VERSION ""

NS_ :

BS_:

BU_: WCM4 WCM3 WCM2 WCM VPM VLM VKM VICM VECM VDM VCU_RTOS_ETH VCU_ENTRY_ETH VCU_AGVM_ETH VCU UVM UPM TIM TEST_TOOL_1 TCP_ETH TCP TCM TCCM SRR_SRR_ETH SRR_SRR SRR_SLR_ETH SRR_SLR SRR_RR SRR_RF_ETH SRR_RF SRR_LR_CR SRR_LF_ETH SRR_LF SIB SDM SCL SBZA_R SBZA_L SBM SAM_RR SAM_RF SAM_LR SAM_LF SAM_BH SADS RadioLow_ETH RadioLow RSI_RTOS_ETH RSI RDCM PTM PLCM PFCM PDR_ETH PDR PCM PA ODS2 ODS NVM MTCM_R MTCM_L MSM_RR MSM_P MSM_LR MSM_D MSB2 MSB1 MRCM_R MRCM_L MFC LRR_RR_ETH LRR_LR_ETH LRR_CF_ETH LRR LRL_CF_ETH LIB_48V LIB1 IPC_INT IPC_GP IPC ICS_Info ICCM HVAC_FP_R HVAC_FP_F HUD_CAN HDLM FPI_RTOS_ETH FPI FOPM FCM_LC FCM EPSb EPS_1 EPSRAb EPSRAa EPS EOCM_HC_Superset EOCM_HCP2 EOCM ELM ECP_X1 ECP_S2 ECP_S ECP_MC ECP_H3 ECP_H2 ECP_H1 ECP_E ECM EBCM DMS DEFC DCM CSM_ETH CSM_AV CSM CGM_OTA_ETH CGM BSM_MH BSM_HEV BSM BCM ARS ARB APA AOS AMP ALC AHS AHL_AFL ADIMb ADIMa ACP2_MCU

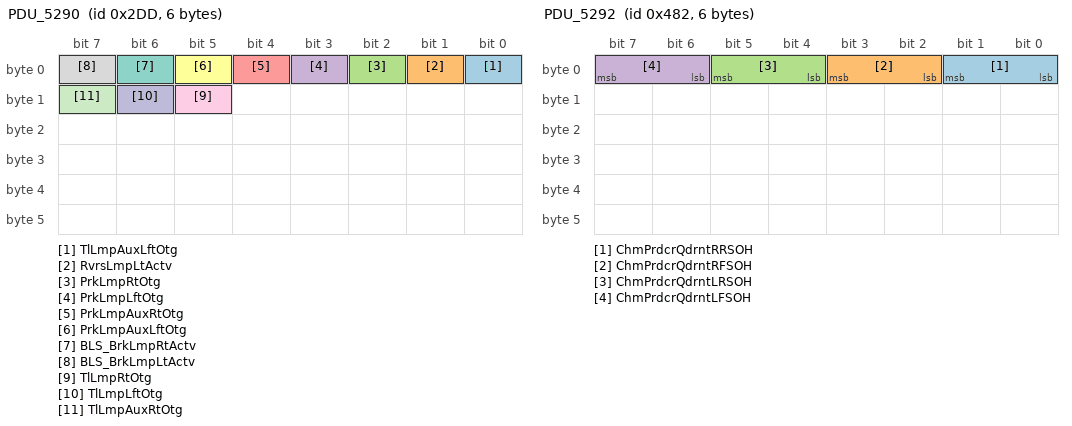
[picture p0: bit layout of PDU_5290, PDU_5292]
BO_ 733 PDU_5290: 6 CGM
 SG_ TlLmpAuxLftOtg : 0|1@0+ (1,0) [0|1] "" VKM
 SG_ RvrsLmpLtActv : 1|1@0+ (1,0) [0|1] "" VKM
 SG_ PrkLmpRtOtg : 2|1@0+ (1,0) [0|1] "" VKM
 SG_ PrkLmpLftOtg : 3|1@0+ (1,0) [0|1] "" VKM
 SG_ PrkLmpAuxRtOtg : 4|1@0+ (1,0) [0|1] "" VKM
 SG_ PrkLmpAuxLftOtg : 5|1@0+ (1,0) [0|1] "" VKM
 SG_ BLS_BrkLmpRtActv : 6|1@0+ (1,0) [0|1] "" VKM
 SG_ BLS_BrkLmpLtActv : 7|1@0+ (1,0) [0|1] "" VKM
 SG_ TlLmpRtOtg : 13|1@0+ (1,0) [0|1] "" VKM
 SG_ TlLmpLftOtg : 14|1@0+ (1,0) [0|1] "" VKM
 SG_ TlLmpAuxRtOtg : 15|1@0+ (1,0) [0|1] "" VKM

BO_ 734 PDU_5291: 6 CGM
 SG_ BGI5_TrnLmpRtFncActv : 6|1@0+ (1,0) [0|1] "" VKM
 SG_ BGI5_TrnLmpLtFncActv : 7|1@0+ (1,0) [0|1] "" VKM

BO_ 1154 PDU_5292: 6 AMP
 SG_ ChmPrdcrQdrntRRSOH : 1|2@0+ (1,0) [0|2] "" VCU
 SG_ ChmPrdcrQdrntRFSOH : 3|2@0+ (1,0) [0|2] "" VCU
 SG_ ChmPrdcrQdrntLRSOH : 5|2@0+ (1,0) [0|2] "" VCU
 SG_ ChmPrdcrQdrntLFSOH : 7|2@0+ (1,0) [0|2] "" VCU

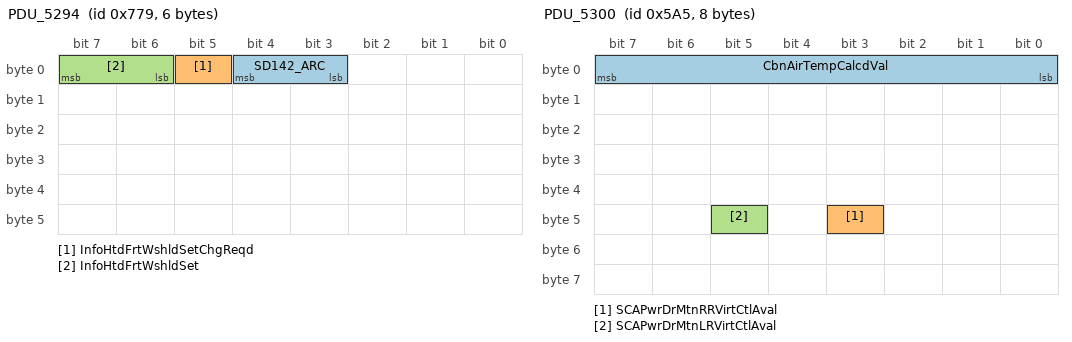
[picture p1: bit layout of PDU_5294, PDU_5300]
BO_ 1913 PDU_5294: 6 RadioLow
 SG_ SD142_ARC : 4|2@0+ (1,0) [0|3] "" CGM
 SG_ InfoHtdFrtWshldSetChgReqd : 5|1@0+ (1,0) [0|1] "" CGM
 SG_ InfoHtdFrtWshldSet : 7|2@0+ (1,0) [0|3] "" CGM

BO_ 229 PDU_5296: 6 CSM
 SG_ DrvModeConfDrvrResp : 7|4@0+ (1,0) [0|15] "" CGM

BO_ 537 PDU_5297: 6 IPC
 SG_ MaxPwrModeConfDrvrResp : 7|3@0+ (1,0) [0|7] "" CGM

BO_ 1304 PDU_5298: 8 VCU
 SG_ HVACICRBlwLvlChgRrRt : 2|5@0+ (1,-12) [-12|19] "" Vector__XXX
 SG_ HVACICRBlwLvlChgFrtRt : 7|5@0+ (1,-12) [-12|19] "" Vector__XXX
 SG_ HVACICRBlwLvlRrRt : 9|4@0+ (1,0) [0|15] "" Vector__XXX
 SG_ HVACICRBlwLvlFrtRt : 13|4@0+ (1,0) [0|15] "" Vector__XXX
 SG_ HVACICRMcrClmStSyncRrRt : 18|1@0+ (1,0) [0|1] "" Vector__XXX
 SG_ HVACICRMcrClmStSyncRrLt : 19|1@0+ (1,0) [0|1] "" Vector__XXX
 SG_ HVACICRMcrClmStSyncFrtRt : 20|1@0+ (1,0) [0|1] "" Vector__XXX
 SG_ HVACICRMcrClmStSyncFrtLt : 21|1@0+ (1,0) [0|1] "" Vector__XXX
 SG_ HVACICRNckScrfLvlChgFrtLt : 25|3@0+ (1,-3) [-3|4] "" Vector__XXX
 SG_ HVACICRNckScrfLvlChgRrRt : 32|3@0+ (1,-3) [-3|4] "" Vector__XXX
 SG_ HVACICRNckScrfLvlChgRrLt : 35|3@0+ (1,-3) [-3|4] "" Vector__XXX
 SG_ HVACICRNckScrfLvlChgFrtRt : 38|3@0+ (1,-3) [-3|4] "" Vector__XXX
 SG_ HVACICRNckScrfLvlRrLt : 41|2@0+ (1,0) [0|3] "" Vector__XXX
 SG_ HVACICRNckScrfLvlFrtRt : 43|2@0+ (1,0) [0|3] "" Vector__XXX
 SG_ HVACICRNckScrfLvlFrtLt : 45|2@0+ (1,0) [0|3] "" Vector__XXX
 SG_ HVACICRFrtRtAutoSetChg : 49|1@0+ (1,0) [0|1] "" Vector__XXX
 SG_ HVACICRBlwLvlRrRtActv : 50|1@0+ (1,0) [0|1] "" Vector__XXX
 SG_ HVACICRBlwLvlFrtRtActv : 51|1@0+ (1,0) [0|1] "" Vector__XXX
 SG_ SD163_ARC : 53|2@0+ (1,0) [0|3] "" Vector__XXX
 SG_ HVACICRNckScrfLvlRrRt : 55|2@0+ (1,0) [0|3] "" Vector__XXX
 SG_ HVACICRRrRtAutoSetChg : 56|1@0+ (1,0) [0|1] "" Vector__XXX
 SG_ HVACICRNckScrfLvlRrRtActv : 57|1@0+ (1,0) [0|1] "" Vector__XXX
 SG_ HVACICRNckScrfLvlRrLtActv : 58|1@0+ (1,0) [0|1] "" Vector__XXX
 SG_ HVACICRNckScrfLvlFrtRtActv : 59|1@0+ (1,0) [0|1] "" Vector__XXX
 SG_ HVACICRNckScrfLvlFrtLtActv : 60|1@0+ (1,0) [0|1] "" Vector__XXX

BO_ 1445 PDU_5300: 8 CGM
 SG_ CbnAirTempCalcdVal : 7|8@0+ (0.5,-40) [-40|87.5] "deg C" TCP
 SG_ SCAPwrDrMtnRRVirtCtlAval : 43|1@0+ (1,0) [0|1] "" VCU
 SG_ SCAPwrDrMtnLRVirtCtlAval : 45|1@0+ (1,0) [0|1] "" VCU

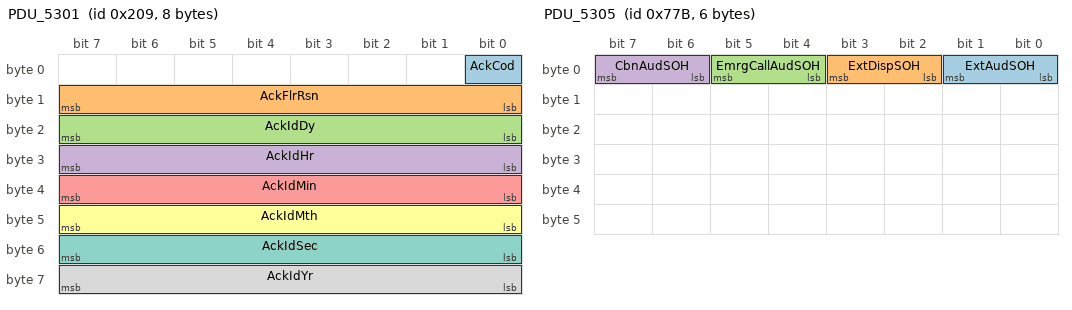
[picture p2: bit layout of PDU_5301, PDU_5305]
BO_ 521 PDU_5301: 8 TCP
 SG_ AckCod : 0|1@0+ (1,0) [0|1] "" Vector__XXX
 SG_ AckFlrRsn : 15|8@0+ (1,0) [0|255] "" Vector__XXX
 SG_ AckIdDy : 23|8@0+ (1,0) [0|255] "" Vector__XXX
 SG_ AckIdHr : 31|8@0+ (1,0) [0|255] "" Vector__XXX
 SG_ AckIdMin : 39|8@0+ (1,0) [0|255] "" Vector__XXX
 SG_ AckIdMth : 47|8@0+ (1,0) [0|255] "" Vector__XXX
 SG_ AckIdSec : 55|8@0+ (1,0) [0|255] "" Vector__XXX
 SG_ AckIdYr : 63|8@0+ (1,0) [0|255] "" Vector__XXX

BO_ 1910 PDU_5303: 8 CGM
 SG_ IntrAmbtColrCtlCstAvlFlg34 : 8|1@0+ (1,0) [0|1] "" VCU
 SG_ IntrAmbtColrCtlCstAvlFlg33 : 9|1@0+ (1,0) [0|1] "" VCU
 SG_ IntrAmbtColrCtlCstAvlFlg32 : 10|1@0+ (1,0) [0|1] "" VCU
 SG_ IntrAmbtColrCtlCstAvlFlg42 : 16|1@0+ (1,0) [0|1] "" VCU
 SG_ IntrAmbtColrCtlCstAvlFlg41 : 17|1@0+ (1,0) [0|1] "" VCU
 SG_ IntrAmbtColrCtlCstAvlFlg40 : 18|1@0+ (1,0) [0|1] "" VCU
 SG_ IntrAmbtColrCtlCstAvlFlg39 : 19|1@0+ (1,0) [0|1] "" VCU
 SG_ IntrAmbtColrCtlCstAvlFlg38 : 20|1@0+ (1,0) [0|1] "" VCU
 SG_ IntrAmbtColrCtlCstAvlFlg37 : 21|1@0+ (1,0) [0|1] "" VCU
 SG_ IntrAmbtColrCtlCstAvlFlg36 : 22|1@0+ (1,0) [0|1] "" VCU
 SG_ IntrAmbtColrCtlCstAvlFlg35 : 23|1@0+ (1,0) [0|1] "" VCU
 SG_ IntrAmbtColrCtlCstAvlFlg50 : 24|1@0+ (1,0) [0|1] "" VCU
 SG_ IntrAmbtColrCtlCstAvlFlg49 : 25|1@0+ (1,0) [0|1] "" VCU
 SG_ IntrAmbtColrCtlCstAvlFlg48 : 26|1@0+ (1,0) [0|1] "" VCU
 SG_ IntrAmbtColrCtlCstAvlFlg47 : 27|1@0+ (1,0) [0|1] "" VCU
 SG_ IntrAmbtColrCtlCstAvlFlg46 : 28|1@0+ (1,0) [0|1] "" VCU
 SG_ IntrAmbtColrCtlCstAvlFlg45 : 29|1@0+ (1,0) [0|1] "" VCU
 SG_ IntrAmbtColrCtlCstAvlFlg44 : 30|1@0+ (1,0) [0|1] "" VCU
 SG_ IntrAmbtColrCtlCstAvlFlg43 : 31|1@0+ (1,0) [0|1] "" VCU
 SG_ IntrAmbtColrCtlCstAvlFlg58 : 32|1@0+ (1,0) [0|1] "" VCU
 SG_ IntrAmbtColrCtlCstAvlFlg57 : 33|1@0+ (1,0) [0|1] "" VCU
 SG_ IntrAmbtColrCtlCstAvlFlg56 : 34|1@0+ (1,0) [0|1] "" VCU
 SG_ IntrAmbtColrCtlCstAvlFlg55 : 35|1@0+ (1,0) [0|1] "" VCU
 SG_ IntrAmbtColrCtlCstAvlFlg54 : 36|1@0+ (1,0) [0|1] "" VCU
 SG_ IntrAmbtColrCtlCstAvlFlg53 : 37|1@0+ (1,0) [0|1] "" VCU
 SG_ IntrAmbtColrCtlCstAvlFlg52 : 38|1@0+ (1,0) [0|1] "" VCU
 SG_ IntrAmbtColrCtlCstAvlFlg51 : 39|1@0+ (1,0) [0|1] "" VCU
 SG_ IntrAmbtColrCtlCstAvlFlg66 : 40|1@0+ (1,0) [0|1] "" VCU
 SG_ IntrAmbtColrCtlCstAvlFlg65 : 41|1@0+ (1,0) [0|1] "" VCU
 SG_ IntrAmbtColrCtlCstAvlFlg64 : 42|1@0+ (1,0) [0|1] "" VCU
 SG_ IntrAmbtColrCtlCstAvlFlg63 : 43|1@0+ (1,0) [0|1] "" VCU
 SG_ IntrAmbtColrCtlCstAvlFlg62 : 44|1@0+ (1,0) [0|1] "" VCU
 SG_ IntrAmbtColrCtlCstAvlFlg61 : 45|1@0+ (1,0) [0|1] "" VCU
 SG_ IntrAmbtColrCtlCstAvlFlg60 : 46|1@0+ (1,0) [0|1] "" VCU
 SG_ IntrAmbtColrCtlCstAvlFlg59 : 47|1@0+ (1,0) [0|1] "" VCU
 SG_ IntrAmbtColrCtlCstAvlFlg74 : 48|1@0+ (1,0) [0|1] "" VCU
 SG_ IntrAmbtColrCtlCstAvlFlg73 : 49|1@0+ (1,0) [0|1] "" VCU
 SG_ IntrAmbtColrCtlCstAvlFlg72 : 50|1@0+ (1,0) [0|1] "" VCU
 SG_ IntrAmbtColrCtlCstAvlFlg71 : 51|1@0+ (1,0) [0|1] "" VCU
 SG_ IntrAmbtColrCtlCstAvlFlg70 : 52|1@0+ (1,0) [0|1] "" VCU
 SG_ IntrAmbtColrCtlCstAvlFlg69 : 53|1@0+ (1,0) [0|1] "" VCU
 SG_ IntrAmbtColrCtlCstAvlFlg68 : 54|1@0+ (1,0) [0|1] "" VCU
 SG_ IntrAmbtColrCtlCstAvlFlg67 : 55|1@0+ (1,0) [0|1] "" VCU
 SG_ IntrAmbtColrCtlCstAvlFlg82 : 56|1@0+ (1,0) [0|1] "" VCU
 SG_ IntrAmbtColrCtlCstAvlFlg81 : 57|1@0+ (1,0) [0|1] "" VCU
 SG_ IntrAmbtColrCtlCstAvlFlg80 : 58|1@0+ (1,0) [0|1] "" VCU
 SG_ IntrAmbtColrCtlCstAvlFlg79 : 59|1@0+ (1,0) [0|1] "" VCU
 SG_ IntrAmbtColrCtlCstAvlFlg78 : 60|1@0+ (1,0) [0|1] "" VCU
 SG_ IntrAmbtColrCtlCstAvlFlg77 : 61|1@0+ (1,0) [0|1] "" VCU
 SG_ IntrAmbtColrCtlCstAvlFlg76 : 62|1@0+ (1,0) [0|1] "" VCU
 SG_ IntrAmbtColrCtlCstAvlFlg75 : 63|1@0+ (1,0) [0|1] "" VCU

BO_ 1912 PDU_5304: 8 CGM
 SG_ IntrAmbtColrCtlCstAvlFlg107 : 0|1@0+ (1,0) [0|1] "" VCU
 SG_ IntrAmbtColrCtlCstAvlFlg106 : 1|1@0+ (1,0) [0|1] "" VCU
 SG_ IntrAmbtColrCtlCstAvlFlg105 : 2|1@0+ (1,0) [0|1] "" VCU
 SG_ IntrAmbtColrCtlCstAvlFlg104 : 3|1@0+ (1,0) [0|1] "" VCU
 SG_ IntrAmbtColrCtlCstAvlFlg103 : 4|1@0+ (1,0) [0|1] "" VCU
 SG_ IntrAmbtColrCtlCstAvlFlg102 : 5|1@0+ (1,0) [0|1] "" VCU
 SG_ IntrAmbtColrCtlCstAvlFlg101 : 6|1@0+ (1,0) [0|1] "" VCU
 SG_ IntrAmbtColrCtlCstAvlFlg100 : 7|1@0+ (1,0) [0|1] "" VCU
 SG_ IntrAmbtColrCtlCstAvlFlg115 : 8|1@0+ (1,0) [0|1] "" VCU
 SG_ IntrAmbtColrCtlCstAvlFlg114 : 9|1@0+ (1,0) [0|1] "" VCU
 SG_ IntrAmbtColrCtlCstAvlFlg113 : 10|1@0+ (1,0) [0|1] "" VCU
 SG_ IntrAmbtColrCtlCstAvlFlg112 : 11|1@0+ (1,0) [0|1] "" VCU
 SG_ IntrAmbtColrCtlCstAvlFlg111 : 12|1@0+ (1,0) [0|1] "" VCU
 SG_ IntrAmbtColrCtlCstAvlFlg110 : 13|1@0+ (1,0) [0|1] "" VCU
 SG_ IntrAmbtColrCtlCstAvlFlg109 : 14|1@0+ (1,0) [0|1] "" VCU
 SG_ IntrAmbtColrCtlCstAvlFlg108 : 15|1@0+ (1,0) [0|1] "" VCU
 SG_ IntrAmbtColrCtlCstAvlFlg123 : 16|1@0+ (1,0) [0|1] "" VCU
 SG_ IntrAmbtColrCtlCstAvlFlg122 : 17|1@0+ (1,0) [0|1] "" VCU
 SG_ IntrAmbtColrCtlCstAvlFlg121 : 18|1@0+ (1,0) [0|1] "" VCU
 SG_ IntrAmbtColrCtlCstAvlFlg120 : 19|1@0+ (1,0) [0|1] "" VCU
 SG_ IntrAmbtColrCtlCstAvlFlg119 : 20|1@0+ (1,0) [0|1] "" VCU
 SG_ IntrAmbtColrCtlCstAvlFlg118 : 21|1@0+ (1,0) [0|1] "" VCU
 SG_ IntrAmbtColrCtlCstAvlFlg117 : 22|1@0+ (1,0) [0|1] "" VCU
 SG_ IntrAmbtColrCtlCstAvlFlg116 : 23|1@0+ (1,0) [0|1] "" VCU
 SG_ IntrAmbtColrCtlCstAvlFlg86 : 24|1@0+ (1,0) [0|1] "" VCU
 SG_ IntrAmbtColrCtlCstAvlFlg85 : 25|1@0+ (1,0) [0|1] "" VCU
 SG_ IntrAmbtColrCtlCstAvlFlg84 : 26|1@0+ (1,0) [0|1] "" VCU
 SG_ IntrAmbtColrCtlCstAvlFlg83 : 27|1@0+ (1,0) [0|1] "" VCU
 SG_ IntrAmbtColrCtlCstAvlFlg127 : 28|1@0+ (1,0) [0|1] "" VCU
 SG_ IntrAmbtColrCtlCstAvlFlg126 : 29|1@0+ (1,0) [0|1] "" VCU
 SG_ IntrAmbtColrCtlCstAvlFlg125 : 30|1@0+ (1,0) [0|1] "" VCU
 SG_ IntrAmbtColrCtlCstAvlFlg124 : 31|1@0+ (1,0) [0|1] "" VCU
 SG_ IntrAmbtColrCtlCstAvlFlg94 : 32|1@0+ (1,0) [0|1] "" VCU
 SG_ IntrAmbtColrCtlCstAvlFlg93 : 33|1@0+ (1,0) [0|1] "" VCU
 SG_ IntrAmbtColrCtlCstAvlFlg92 : 34|1@0+ (1,0) [0|1] "" VCU
 SG_ IntrAmbtColrCtlCstAvlFlg91 : 35|1@0+ (1,0) [0|1] "" VCU
 SG_ IntrAmbtColrCtlCstAvlFlg90 : 36|1@0+ (1,0) [0|1] "" VCU
 SG_ IntrAmbtColrCtlCstAvlFlg89 : 37|1@0+ (1,0) [0|1] "" VCU
 SG_ IntrAmbtColrCtlCstAvlFlg88 : 38|1@0+ (1,0) [0|1] "" VCU
 SG_ IntrAmbtColrCtlCstAvlFlg87 : 39|1@0+ (1,0) [0|1] "" VCU
 SG_ ElvtdIdlCstSetAvlFlg2 : 40|1@0+ (1,0) [0|1] "" RadioLow,CSM,CSM_AV,VCU
 SG_ ElvtdIdlCstSetAvlFlg1 : 41|1@0+ (1,0) [0|1] "" RadioLow,CSM,CSM_AV,VCU
 SG_ ElvtdIdlCstSetAval : 42|1@0+ (1,0) [0|1] "" RadioLow,CSM,CSM_AV,VCU
 SG_ IntrAmbtColrCtlCstAvlFlg99 : 43|1@0+ (1,0) [0|1] "" VCU
 SG_ IntrAmbtColrCtlCstAvlFlg98 : 44|1@0+ (1,0) [0|1] "" VCU
 SG_ IntrAmbtColrCtlCstAvlFlg97 : 45|1@0+ (1,0) [0|1] "" VCU
 SG_ IntrAmbtColrCtlCstAvlFlg96 : 46|1@0+ (1,0) [0|1] "" VCU
 SG_ IntrAmbtColrCtlCstAvlFlg95 : 47|1@0+ (1,0) [0|1] "" VCU
 SG_ DMSDrwDrvrCstAvlFlg3 : 48|1@0+ (1,0) [0|1] "" CSM,CSM_AV,VCU
 SG_ DMSDrwDrvrCstAvlFlg2 : 49|1@0+ (1,0) [0|1] "" CSM,CSM_AV,VCU
 SG_ DMSDrwDrvrCstAvlFlg1 : 50|1@0+ (1,0) [0|1] "" CSM,CSM_AV,VCU
 SG_ ElvtdIdlCstSetAvlFlg7 : 51|1@0+ (1,0) [0|1] "" RadioLow,CSM,CSM_AV,VCU
 SG_ ElvtdIdlCstSetAvlFlg6 : 52|1@0+ (1,0) [0|1] "" RadioLow,CSM,CSM_AV,VCU
 SG_ ElvtdIdlCstSetAvlFlg5 : 53|1@0+ (1,0) [0|1] "" RadioLow,CSM,CSM_AV,VCU
 SG_ ElvtdIdlCstSetAvlFlg4 : 54|1@0+ (1,0) [0|1] "" RadioLow,CSM,CSM_AV,VCU
 SG_ ElvtdIdlCstSetAvlFlg3 : 55|1@0+ (1,0) [0|1] "" RadioLow,CSM,CSM_AV,VCU
 SG_ VehSpdAcurLvl : 58|2@0+ (1,0) [0|2] "" FPI,RSI,IPC,IPC_INT,VCU
 SG_ DMSDrwDrvrCstSetAval : 59|1@0+ (1,0) [0|1] "" CSM,CSM_AV,VCU
 SG_ DMSDrwDrvrCstAvlFlg7 : 60|1@0+ (1,0) [0|1] "" CSM,CSM_AV,VCU
 SG_ DMSDrwDrvrCstAvlFlg6 : 61|1@0+ (1,0) [0|1] "" CSM,CSM_AV,VCU
 SG_ DMSDrwDrvrCstAvlFlg5 : 62|1@0+ (1,0) [0|1] "" CSM,CSM_AV,VCU
 SG_ DMSDrwDrvrCstAvlFlg4 : 63|1@0+ (1,0) [0|1] "" CSM,CSM_AV,VCU

BO_ 1915 PDU_5305: 6 CSM_AV
 SG_ ExtAudSOH : 1|2@0+ (1,0) [0|3] "" CGM
 SG_ ExtDispSOH : 3|2@0+ (1,0) [0|3] "" CGM
 SG_ EmrgCallAudSOH : 5|2@0+ (1,0) [0|3] "" CGM
 SG_ CbnAudSOH : 7|2@0+ (1,0) [0|3] "" CGM

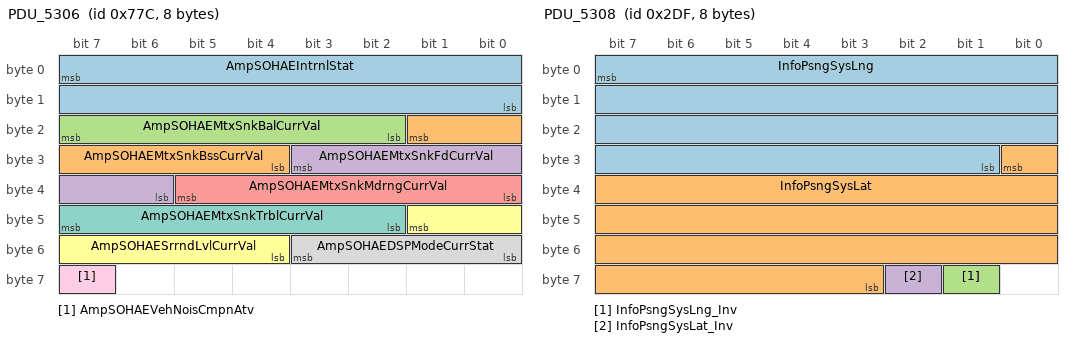
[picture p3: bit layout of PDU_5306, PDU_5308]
BO_ 1916 PDU_5306: 8 AMP
 SG_ AmpSOHAEIntrnlStat : 7|16@0+ (1,0) [0|65535] "" VCU
 SG_ AmpSOHAEMtxSnkBssCurrVal : 17|6@0- (1,0) [-32|31] "detent" VCU
 SG_ AmpSOHAEMtxSnkBalCurrVal : 23|6@0- (1,0) [-32|31] "detent" VCU
 SG_ AmpSOHAEMtxSnkFdCurrVal : 27|6@0- (1,0) [-32|31] "detent" VCU
 SG_ AmpSOHAEMtxSnkMdrngCurrVal : 37|6@0- (1,0) [-32|31] "detent" VCU
 SG_ AmpSOHAESrrndLvlCurrVal : 41|6@0- (1,0) [-32|31] "detent" VCU
 SG_ AmpSOHAEMtxSnkTrblCurrVal : 47|6@0- (1,0) [-32|31] "detent" VCU
 SG_ AmpSOHAEDSPModeCurrStat : 51|4@0+ (1,0) [0|8] "" VCU
 SG_ AmpSOHAEVehNoisCmpnAtv : 63|1@0+ (1,0) [0|1] "" VCU

BO_ 735 PDU_5308: 8 VCU
 SG_ InfoPsngSysLng : 7|31@0- (1,0) [-1.07374e+009|1.07374e+009] "" CGM
 SG_ InfoPsngSysLat : 24|30@0- (1,0) [-5.36871e+008|5.36871e+008] "" CGM
 SG_ InfoPsngSysLng_Inv : 57|1@0+ (1,0) [0|1] "" CGM
 SG_ InfoPsngSysLat_Inv : 58|1@0+ (1,0) [0|1] "" CGM

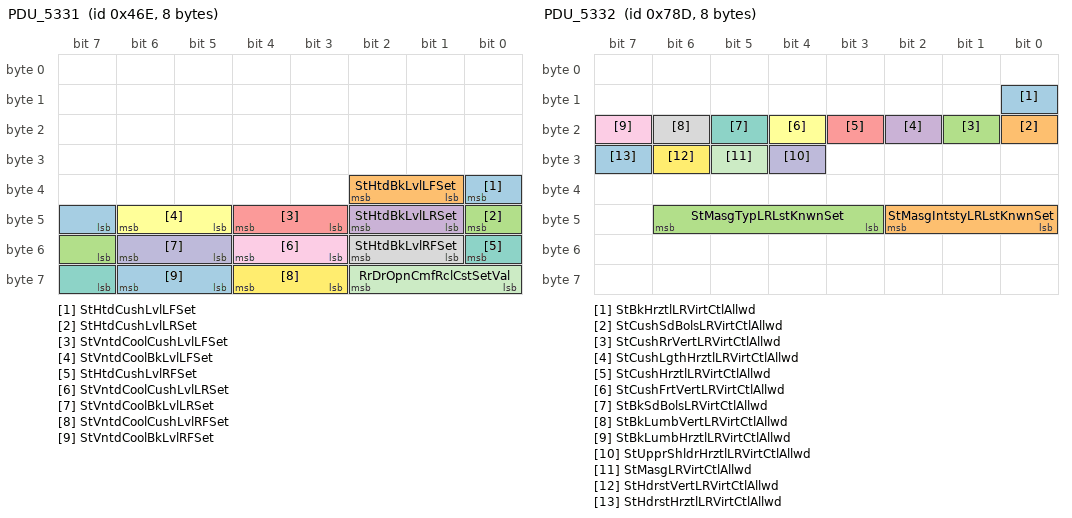
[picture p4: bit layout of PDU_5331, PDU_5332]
BO_ 1134 PDU_5331: 8 CGM
 SG_ StHtdCushLvlLFSet : 32|2@0+ (1,0) [0|3] "" VCU
 SG_ StHtdBkLvlLFSet : 34|2@0+ (1,0) [0|3] "" VCU
 SG_ StHtdCushLvlLRSet : 40|2@0+ (1,0) [0|3] "" VCU
 SG_ StHtdBkLvlLRSet : 42|2@0+ (1,0) [0|3] "" VCU
 SG_ StVntdCoolCushLvlLFSet : 44|2@0+ (1,0) [0|3] "" VCU
 SG_ StVntdCoolBkLvlLFSet : 46|2@0+ (1,0) [0|3] "" VCU
 SG_ StHtdCushLvlRFSet : 48|2@0+ (1,0) [0|3] "" VCU
 SG_ StHtdBkLvlRFSet : 50|2@0+ (1,0) [0|3] "" VCU
 SG_ StVntdCoolCushLvlLRSet : 52|2@0+ (1,0) [0|3] "" VCU
 SG_ StVntdCoolBkLvlLRSet : 54|2@0+ (1,0) [0|3] "" VCU
 SG_ RrDrOpnCmfRclCstSetVal : 58|3@0+ (1,0) [0|2] "" VCU
 SG_ StVntdCoolCushLvlRFSet : 60|2@0+ (1,0) [0|3] "" VCU
 SG_ StVntdCoolBkLvlRFSet : 62|2@0+ (1,0) [0|3] "" VCU

BO_ 1933 PDU_5332: 8 CGM
 SG_ StBkHrztlLRVirtCtlAllwd : 8|1@0+ (1,0) [0|1] "" VCU
 SG_ StCushSdBolsLRVirtCtlAllwd : 16|1@0+ (1,0) [0|1] "" VCU
 SG_ StCushRrVertLRVirtCtlAllwd : 17|1@0+ (1,0) [0|1] "" VCU
 SG_ StCushLgthHrztlLRVirtCtlAllwd : 18|1@0+ (1,0) [0|1] "" VCU
 SG_ StCushHrztlLRVirtCtlAllwd : 19|1@0+ (1,0) [0|1] "" VCU
 SG_ StCushFrtVertLRVirtCtlAllwd : 20|1@0+ (1,0) [0|1] "" VCU
 SG_ StBkSdBolsLRVirtCtlAllwd : 21|1@0+ (1,0) [0|1] "" VCU
 SG_ StBkLumbVertLRVirtCtlAllwd : 22|1@0+ (1,0) [0|1] "" VCU
 SG_ StBkLumbHrztlLRVirtCtlAllwd : 23|1@0+ (1,0) [0|1] "" VCU
 SG_ StUpprShldrHrztlLRVirtCtlAllwd : 28|1@0+ (1,0) [0|1] "" VCU
 SG_ StMasgLRVirtCtlAllwd : 29|1@0+ (1,0) [0|1] "" VCU
 SG_ StHdrstVertLRVirtCtlAllwd : 30|1@0+ (1,0) [0|1] "" VCU
 SG_ StHdrstHrztlLRVirtCtlAllwd : 31|1@0+ (1,0) [0|1] "" VCU
 SG_ StMasgIntstyLRLstKnwnSet : 42|3@0+ (1,0) [0|7] "" VCU
 SG_ StMasgTypLRLstKnwnSet : 46|4@0+ (1,0) [0|15] "" VCU

BO_ 1131 PDU_5335: 8 VCU
 SG_ SuprRmtPrkFcsStsVCU : 34|1@0+ (1,0) [0|1] "" CGM

BO_ 1133 PDU_5338: 8 VCU
 SG_ HVACICROtltFrtRtInbdVrtPs : 0|7@0+ (1,0) [0|127] "%" Vector__XXX
 SG_ HVACICROtltFrtRtInbdHrztlPs : 7|7@0+ (1,0) [0|127] "%" Vector__XXX
 SG_ HVACICROtltFrtRtOtbdHrztlPs : 9|7@0+ (1,0) [0|127] "%" Vector__XXX
 SG_ HVACICROtltFrtRtOtbdVrtPs : 18|7@0+ (1,0) [0|127] "%" Vector__XXX
 SG_ HVACICROtltFrtRtOtbdArflQnty : 24|3@0+ (1,0) [0|4] "" Vector__XXX
 SG_ HVACICROtltFrtRtInbdArflQnty : 27|3@0+ (1,0) [0|4] "" Vector__XXX
 SG_ SD213_ARC : 33|2@0+ (1,0) [0|3] "" Vector__XXX
 SG_ HVACICROtltFrtRtStat : 35|2@0+ (1,0) [0|3] "" Vector__XXX
 SG_ HVACICROscMdFrtRtSet : 37|2@0+ (1,0) [0|3] "" Vector__XXX
 SG_ HVACICROtltRrLtInbdHrztlPs : 45|7@0+ (1,0) [0|127] "%" Vector__XXX
 SG_ HVACICRHVACPwrFrtRtChg : 46|1@0+ (1,0) [0|1] "" Vector__XXX
 SG_ HVACICRCkMdOn : 47|1@0+ (1,0) [0|1] "" Vector__XXX
 SG_ HVACICROtltRrLtInbdVrtPs : 54|7@0+ (1,0) [0|127] "%" Vector__XXX
 SG_ HVACICRHVACPwrRrLtChg : 57|1@0+ (1,0) [0|1] "" Vector__XXX
 SG_ SD214_ARC : 59|2@0+ (1,0) [0|3] "" Vector__XXX
 SG_ HVACICROtltRrLtStat : 61|2@0+ (1,0) [0|3] "" Vector__XXX
 SG_ HVACICROscMdRrLtSet : 63|2@0+ (1,0) [0|3] "" Vector__XXX

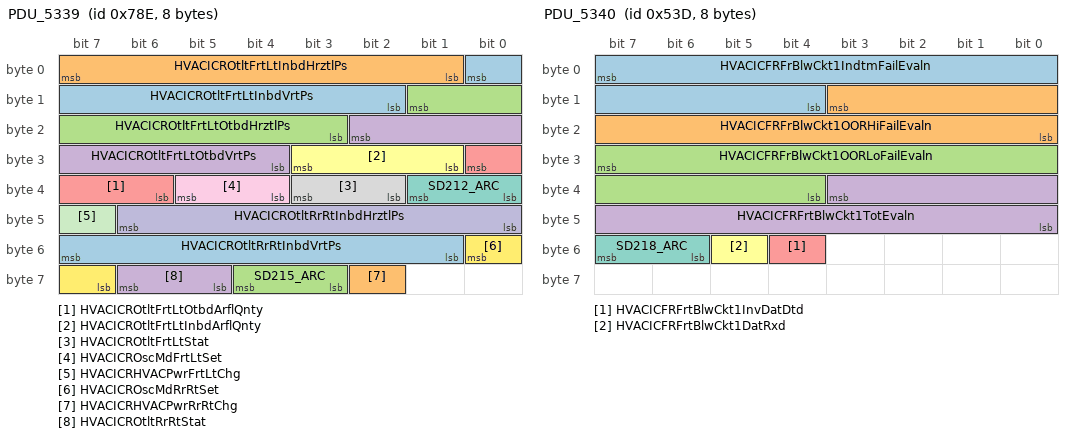
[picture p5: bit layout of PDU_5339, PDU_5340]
BO_ 1934 PDU_5339: 8 VCU
 SG_ HVACICROtltFrtLtInbdVrtPs : 0|7@0+ (1,0) [0|127] "%" Vector__XXX
 SG_ HVACICROtltFrtLtInbdHrztlPs : 7|7@0+ (1,0) [0|127] "%" Vector__XXX
 SG_ HVACICROtltFrtLtOtbdHrztlPs : 9|7@0+ (1,0) [0|127] "%" Vector__XXX
 SG_ HVACICROtltFrtLtOtbdVrtPs : 18|7@0+ (1,0) [0|127] "%" Vector__XXX
 SG_ HVACICROtltFrtLtOtbdArflQnty : 24|3@0+ (1,0) [0|4] "" Vector__XXX
 SG_ HVACICROtltFrtLtInbdArflQnty : 27|3@0+ (1,0) [0|4] "" Vector__XXX
 SG_ SD212_ARC : 33|2@0+ (1,0) [0|3] "" Vector__XXX
 SG_ HVACICROtltFrtLtStat : 35|2@0+ (1,0) [0|3] "" Vector__XXX
 SG_ HVACICROscMdFrtLtSet : 37|2@0+ (1,0) [0|3] "" Vector__XXX
 SG_ HVACICROtltRrRtInbdHrztlPs : 46|7@0+ (1,0) [0|127] "%" Vector__XXX
 SG_ HVACICRHVACPwrFrtLtChg : 47|1@0+ (1,0) [0|1] "" Vector__XXX
 SG_ HVACICROscMdRrRtSet : 48|2@0+ (1,0) [0|3] "" Vector__XXX
 SG_ HVACICROtltRrRtInbdVrtPs : 55|7@0+ (1,0) [0|127] "%" Vector__XXX
 SG_ HVACICRHVACPwrRrRtChg : 58|1@0+ (1,0) [0|1] "" Vector__XXX
 SG_ SD215_ARC : 60|2@0+ (1,0) [0|3] "" Vector__XXX
 SG_ HVACICROtltRrRtStat : 62|2@0+ (1,0) [0|3] "" Vector__XXX

BO_ 1341 PDU_5340: 8 VCU
 SG_ HVACICFRFrBlwCkt1IndtmFailEvaln : 7|12@0+ (1,0) [0|4095] "Counts" Vector__XXX
 SG_ HVACICFRFrBlwCkt1OORHiFailEvaln : 11|12@0+ (1,0) [0|4095] "Counts" Vector__XXX
 SG_ HVACICFRFrBlwCkt1OORLoFailEvaln : 31|12@0+ (1,0) [0|4095] "Counts" Vector__XXX
 SG_ HVACICFRFrtBlwCkt1TotEvaln : 35|12@0+ (1,0) [0|4095] "Counts" Vector__XXX
 SG_ HVACICFRFrtBlwCkt1InvDatDtd : 52|1@0+ (1,0) [0|1] "" Vector__XXX
 SG_ HVACICFRFrtBlwCkt1DatRxd : 53|1@0+ (1,0) [0|1] "" Vector__XXX
 SG_ SD218_ARC : 55|2@0+ (1,0) [0|3] "" Vector__XXX

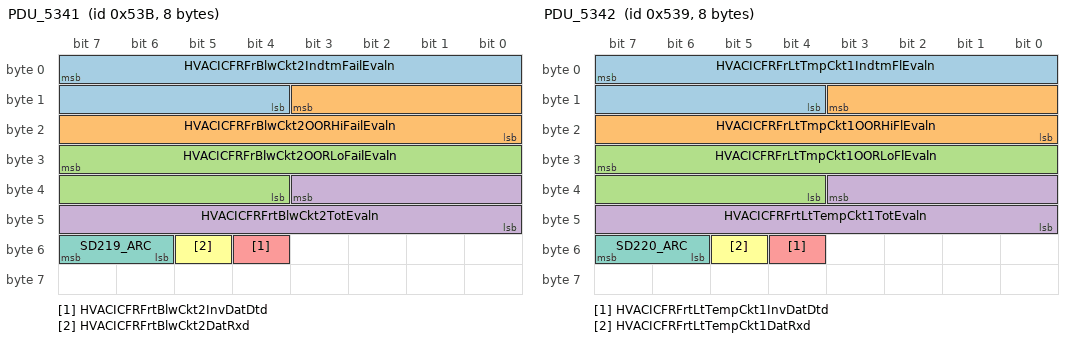
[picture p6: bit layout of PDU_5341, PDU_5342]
BO_ 1339 PDU_5341: 8 VCU
 SG_ HVACICFRFrBlwCkt2IndtmFailEvaln : 7|12@0+ (1,0) [0|4095] "Counts" Vector__XXX
 SG_ HVACICFRFrBlwCkt2OORHiFailEvaln : 11|12@0+ (1,0) [0|4095] "Counts" Vector__XXX
 SG_ HVACICFRFrBlwCkt2OORLoFailEvaln : 31|12@0+ (1,0) [0|4095] "Counts" Vector__XXX
 SG_ HVACICFRFrtBlwCkt2TotEvaln : 35|12@0+ (1,0) [0|4095] "Counts" Vector__XXX
 SG_ HVACICFRFrtBlwCkt2InvDatDtd : 52|1@0+ (1,0) [0|1] "" Vector__XXX
 SG_ HVACICFRFrtBlwCkt2DatRxd : 53|1@0+ (1,0) [0|1] "" Vector__XXX
 SG_ SD219_ARC : 55|2@0+ (1,0) [0|3] "" Vector__XXX

BO_ 1337 PDU_5342: 8 VCU
 SG_ HVACICFRFrLtTmpCkt1IndtmFlEvaln : 7|12@0+ (1,0) [0|4095] "Counts" Vector__XXX
 SG_ HVACICFRFrLtTmpCkt1OORHiFlEvaln : 11|12@0+ (1,0) [0|4095] "Counts" Vector__XXX
 SG_ HVACICFRFrLtTmpCkt1OORLoFlEvaln : 31|12@0+ (1,0) [0|4095] "Counts" Vector__XXX
 SG_ HVACICFRFrtLtTempCkt1TotEvaln : 35|12@0+ (1,0) [0|4095] "Counts" Vector__XXX
 SG_ HVACICFRFrtLtTempCkt1InvDatDtd : 52|1@0+ (1,0) [0|1] "" Vector__XXX
 SG_ HVACICFRFrtLtTempCkt1DatRxd : 53|1@0+ (1,0) [0|1] "" Vector__XXX
 SG_ SD220_ARC : 55|2@0+ (1,0) [0|3] "" Vector__XXX

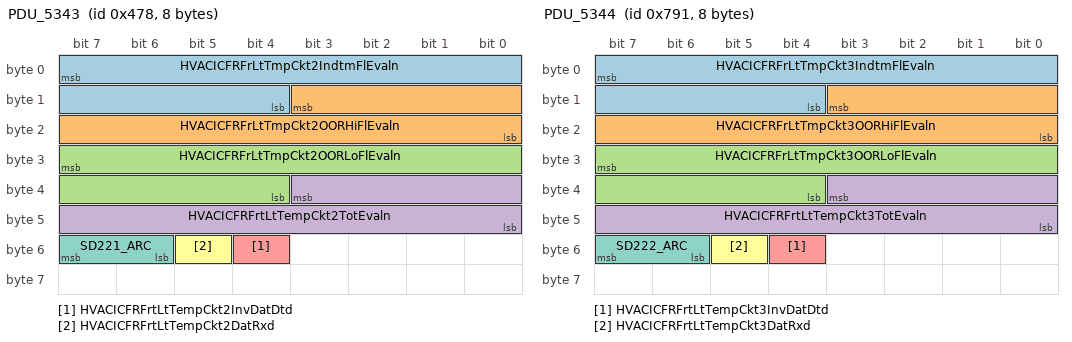
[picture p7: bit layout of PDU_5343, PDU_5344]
BO_ 1144 PDU_5343: 8 VCU
 SG_ HVACICFRFrLtTmpCkt2IndtmFlEvaln : 7|12@0+ (1,0) [0|4095] "Counts" Vector__XXX
 SG_ HVACICFRFrLtTmpCkt2OORHiFlEvaln : 11|12@0+ (1,0) [0|4095] "Counts" Vector__XXX
 SG_ HVACICFRFrLtTmpCkt2OORLoFlEvaln : 31|12@0+ (1,0) [0|4095] "Counts" Vector__XXX
 SG_ HVACICFRFrtLtTempCkt2TotEvaln : 35|12@0+ (1,0) [0|4095] "Counts" Vector__XXX
 SG_ HVACICFRFrtLtTempCkt2InvDatDtd : 52|1@0+ (1,0) [0|1] "" Vector__XXX
 SG_ HVACICFRFrtLtTempCkt2DatRxd : 53|1@0+ (1,0) [0|1] "" Vector__XXX
 SG_ SD221_ARC : 55|2@0+ (1,0) [0|3] "" Vector__XXX

BO_ 1937 PDU_5344: 8 VCU
 SG_ HVACICFRFrLtTmpCkt3IndtmFlEvaln : 7|12@0+ (1,0) [0|4095] "Counts" Vector__XXX
 SG_ HVACICFRFrLtTmpCkt3OORHiFlEvaln : 11|12@0+ (1,0) [0|4095] "Counts" Vector__XXX
 SG_ HVACICFRFrLtTmpCkt3OORLoFlEvaln : 31|12@0+ (1,0) [0|4095] "Counts" Vector__XXX
 SG_ HVACICFRFrtLtTempCkt3TotEvaln : 35|12@0+ (1,0) [0|4095] "Counts" Vector__XXX
 SG_ HVACICFRFrtLtTempCkt3InvDatDtd : 52|1@0+ (1,0) [0|1] "" Vector__XXX
 SG_ HVACICFRFrtLtTempCkt3DatRxd : 53|1@0+ (1,0) [0|1] "" Vector__XXX
 SG_ SD222_ARC : 55|2@0+ (1,0) [0|3] "" Vector__XXX

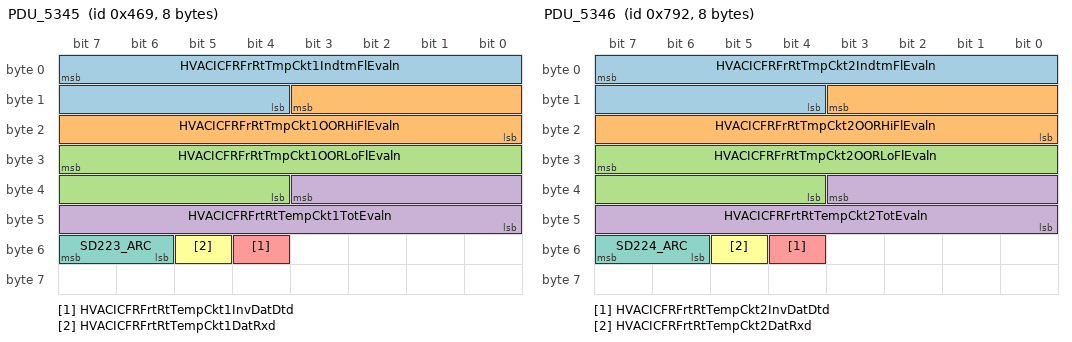
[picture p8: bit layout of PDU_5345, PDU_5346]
BO_ 1129 PDU_5345: 8 VCU
 SG_ HVACICFRFrRtTmpCkt1IndtmFlEvaln : 7|12@0+ (1,0) [0|4095] "Counts" Vector__XXX
 SG_ HVACICFRFrRtTmpCkt1OORHiFlEvaln : 11|12@0+ (1,0) [0|4095] "Counts" Vector__XXX
 SG_ HVACICFRFrRtTmpCkt1OORLoFlEvaln : 31|12@0+ (1,0) [0|4095] "Counts" Vector__XXX
 SG_ HVACICFRFrtRtTempCkt1TotEvaln : 35|12@0+ (1,0) [0|4095] "Counts" Vector__XXX
 SG_ HVACICFRFrtRtTempCkt1InvDatDtd : 52|1@0+ (1,0) [0|1] "" Vector__XXX
 SG_ HVACICFRFrtRtTempCkt1DatRxd : 53|1@0+ (1,0) [0|1] "" Vector__XXX
 SG_ SD223_ARC : 55|2@0+ (1,0) [0|3] "" Vector__XXX

BO_ 1938 PDU_5346: 8 VCU
 SG_ HVACICFRFrRtTmpCkt2IndtmFlEvaln : 7|12@0+ (1,0) [0|4095] "Counts" Vector__XXX
 SG_ HVACICFRFrRtTmpCkt2OORHiFlEvaln : 11|12@0+ (1,0) [0|4095] "Counts" Vector__XXX
 SG_ HVACICFRFrRtTmpCkt2OORLoFlEvaln : 31|12@0+ (1,0) [0|4095] "Counts" Vector__XXX
 SG_ HVACICFRFrtRtTempCkt2TotEvaln : 35|12@0+ (1,0) [0|4095] "Counts" Vector__XXX
 SG_ HVACICFRFrtRtTempCkt2InvDatDtd : 52|1@0+ (1,0) [0|1] "" Vector__XXX
 SG_ HVACICFRFrtRtTempCkt2DatRxd : 53|1@0+ (1,0) [0|1] "" Vector__XXX
 SG_ SD224_ARC : 55|2@0+ (1,0) [0|3] "" Vector__XXX

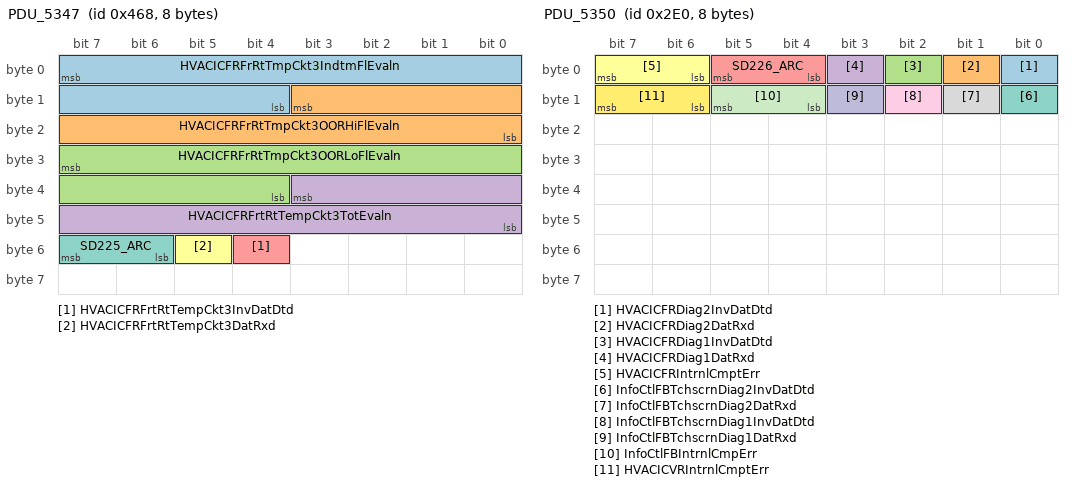
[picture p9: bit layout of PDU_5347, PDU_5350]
BO_ 1128 PDU_5347: 8 VCU
 SG_ HVACICFRFrRtTmpCkt3IndtmFlEvaln : 7|12@0+ (1,0) [0|4095] "Counts" Vector__XXX
 SG_ HVACICFRFrRtTmpCkt3OORHiFlEvaln : 11|12@0+ (1,0) [0|4095] "Counts" Vector__XXX
 SG_ HVACICFRFrRtTmpCkt3OORLoFlEvaln : 31|12@0+ (1,0) [0|4095] "Counts" Vector__XXX
 SG_ HVACICFRFrtRtTempCkt3TotEvaln : 35|12@0+ (1,0) [0|4095] "Counts" Vector__XXX
 SG_ HVACICFRFrtRtTempCkt3InvDatDtd : 52|1@0+ (1,0) [0|1] "" Vector__XXX
 SG_ HVACICFRFrtRtTempCkt3DatRxd : 53|1@0+ (1,0) [0|1] "" Vector__XXX
 SG_ SD225_ARC : 55|2@0+ (1,0) [0|3] "" Vector__XXX

BO_ 1939 PDU_5348: 8 VCU
 SG_ HVACICFRMsg2TotEvaln : 7|8@0+ (1,0) [0|255] "Counts" Vector__XXX
 SG_ HVACICFRTempChgFrtLt : 10|5@0- (1,0) [-16|15] "Counts" Vector__XXX
 SG_ HVACICFRBlwLvlChgFrt : 15|5@0- (1,0) [-16|15] "Counts" Vector__XXX
 SG_ HVACICFRBlwLvlFrtSnsdStat1 : 16|3@0+ (1,0) [0|5] "" Vector__XXX
 SG_ HVACICFRTempChgFrtRt : 21|5@0- (1,0) [-16|15] "Counts" Vector__XXX
 SG_ HVACICFRTempFrtLtSnsdStat1 : 26|3@0+ (1,0) [0|5] "" Vector__XXX
 SG_ HVACICFRBlwLvlFrtSnsdStat2 : 29|3@0+ (1,0) [0|5] "" Vector__XXX
 SG_ HVACICFRTempFrtRtSnsdStat2 : 33|3@0+ (1,0) [0|5] "" Vector__XXX
 SG_ HVACICFRTempFrtRtSnsdStat1 : 36|3@0+ (1,0) [0|5] "" Vector__XXX
 SG_ HVACICFRTempFrtLtSnsdStat2 : 39|3@0+ (1,0) [0|5] "" Vector__XXX
 SG_ SD217_ARC : 40|2@0+ (1,0) [0|3] "" Vector__XXX
 SG_ HVACICFRTempFrtRtCorrSts : 42|2@0+ (1,0) [0|2] "" Vector__XXX
 SG_ HVACICFRTempFrtLtCorrSts : 44|2@0+ (1,0) [0|2] "" Vector__XXX
 SG_ HVACICFRBlwLvlFrtCorrSts : 46|2@0+ (1,0) [0|2] "" Vector__XXX
 SG_ HVACICFRTempFrtRtDatErr : 50|1@0+ (1,0) [0|1] "" Vector__XXX
 SG_ HVACICFRTempFrtLtDatErr : 51|1@0+ (1,0) [0|1] "" Vector__XXX
 SG_ HVACICFRMsg2InvDatDtd : 52|1@0+ (1,0) [0|1] "" Vector__XXX
 SG_ HVACICFRMsg2DatRxd : 53|1@0+ (1,0) [0|1] "" Vector__XXX
 SG_ HVACICFRBlwLvlFrtDatErr : 54|1@0+ (1,0) [0|1] "" Vector__XXX

BO_ 1127 PDU_5349: 8 VCU
 SG_ HVACICFRMsg1TotEvaln : 7|8@0+ (1,0) [0|255] "Counts" Vector__XXX
 SG_ HVACICFRFrtHVACAutoSnsdStat : 9|3@0+ (1,0) [0|5] "" Vector__XXX
 SG_ HVACICFRFrtDefrSnsdStat : 12|3@0+ (1,0) [0|5] "" Vector__XXX
 SG_ HVACICFRCompSnsdStat : 15|3@0+ (1,0) [0|5] "" Vector__XXX
 SG_ HVACICFRRrDfgSnsdStat : 16|3@0+ (1,0) [0|5] "" Vector__XXX
 SG_ HVACICFRRecircSnsdStat : 19|3@0+ (1,0) [0|5] "" Vector__XXX
 SG_ HVACICFRHtSnsdStat : 22|3@0+ (1,0) [0|5] "" Vector__XXX
 SG_ HVACICFRFrtHVACAutoDatErr : 24|1@0+ (1,0) [0|1] "" Vector__XXX
 SG_ HVACICFRFrtDefrDatErr : 25|1@0+ (1,0) [0|1] "" Vector__XXX
 SG_ HVACICFRCompSetChg : 26|1@0+ (1,0) [0|1] "" Vector__XXX
 SG_ HVACICFRCompDatErr : 27|1@0+ (1,0) [0|1] "" Vector__XXX
 SG_ SD216_ARC : 29|2@0+ (1,0) [0|3] "" Vector__XXX
 SG_ HVACICFRRecircSetChg : 32|1@0+ (1,0) [0|1] "" Vector__XXX
 SG_ HVACICFRRecircDatErr : 33|1@0+ (1,0) [0|1] "" Vector__XXX
 SG_ HVACICFRMsg1InvDatDtd : 34|1@0+ (1,0) [0|1] "" Vector__XXX
 SG_ HVACICFRMsg1DatRxd : 35|1@0+ (1,0) [0|1] "" Vector__XXX
 SG_ HVACICFRMaxDefrChg : 36|1@0+ (1,0) [0|1] "" Vector__XXX
 SG_ HVACICFRHtSetChg : 37|1@0+ (1,0) [0|1] "" Vector__XXX
 SG_ HVACICFRHtDatErr : 38|1@0+ (1,0) [0|1] "" Vector__XXX
 SG_ HVACICFRFrtHVACAutoSetChg : 39|1@0+ (1,0) [0|1] "" Vector__XXX
 SG_ HVACICFRRrDfgSetChg : 46|1@0+ (1,0) [0|1] "" Vector__XXX
 SG_ HVACICFRRrDfgDatErr : 47|1@0+ (1,0) [0|1] "" Vector__XXX

BO_ 736 PDU_5350: 8 VCU
 SG_ HVACICFRDiag2InvDatDtd : 0|1@0+ (1,0) [0|1] "" Vector__XXX
 SG_ HVACICFRDiag2DatRxd : 1|1@0+ (1,0) [0|1] "" Vector__XXX
 SG_ HVACICFRDiag1InvDatDtd : 2|1@0+ (1,0) [0|1] "" Vector__XXX
 SG_ HVACICFRDiag1DatRxd : 3|1@0+ (1,0) [0|1] "" Vector__XXX
 SG_ SD226_ARC : 5|2@0+ (1,0) [0|3] "" Vector__XXX
 SG_ HVACICFRIntrnlCmptErr : 7|2@0+ (1,0) [0|2] "" Vector__XXX
 SG_ InfoCtlFBTchscrnDiag2InvDatDtd : 8|1@0+ (1,0) [0|1] "" Vector__XXX
 SG_ InfoCtlFBTchscrnDiag2DatRxd : 9|1@0+ (1,0) [0|1] "" Vector__XXX
 SG_ InfoCtlFBTchscrnDiag1InvDatDtd : 10|1@0+ (1,0) [0|1] "" Vector__XXX
 SG_ InfoCtlFBTchscrnDiag1DatRxd : 11|1@0+ (1,0) [0|1] "" Vector__XXX
 SG_ InfoCtlFBIntrnlCmpErr : 13|2@0+ (1,0) [0|2] "" Vector__XXX
 SG_ HVACICVRIntrnlCmptErr : 15|2@0+ (1,0) [0|2] "" Vector__XXX

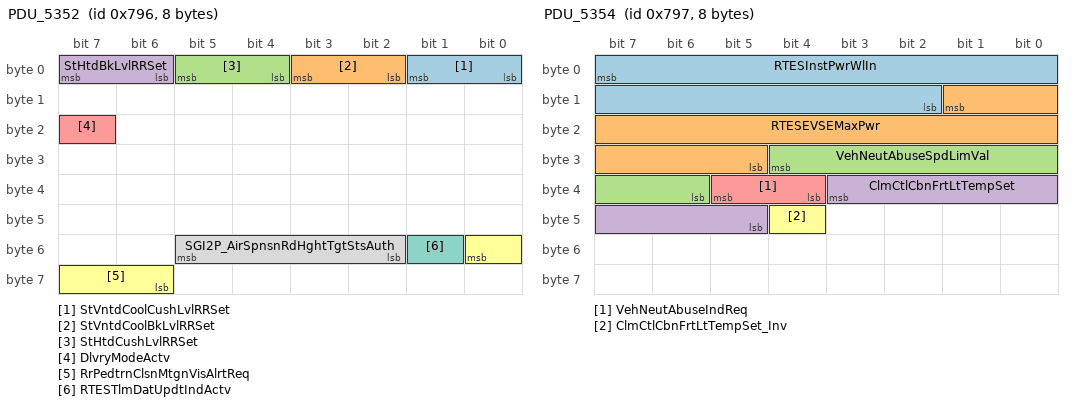
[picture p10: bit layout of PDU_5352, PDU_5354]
BO_ 1942 PDU_5352: 8 CGM
 SG_ StVntdCoolCushLvlRRSet : 1|2@0+ (1,0) [0|3] "" VCU
 SG_ StVntdCoolBkLvlRRSet : 3|2@0+ (1,0) [0|3] "" VCU
 SG_ StHtdCushLvlRRSet : 5|2@0+ (1,0) [0|3] "" VCU
 SG_ StHtdBkLvlRRSet : 7|2@0+ (1,0) [0|3] "" VCU
 SG_ DlvryModeActv : 23|1@0+ (1,0) [0|1] "" CSM,CSM_AV,VCU
 SG_ RrPedtrnClsnMtgnVisAlrtReq : 48|3@0+ (1,0) [0|2] "" VCU
 SG_ RTESTlmDatUpdtIndActv : 49|1@0+ (1,0) [0|1] "" TCP
 SG_ SGI2P_AirSpnsnRdHghtTgtStsAuth : 53|4@0+ (1,0) [0|13] "" CSM,CSM_AV,VCU

BO_ 1124 PDU_5353: 8 VCU
 SG_ StVntdCoolBkLvlLRVirtCtlReq : 1|3@0+ (1,0) [0|4] "" CGM
 SG_ StHtdCushLvlLRVirtCtlReq : 4|3@0+ (1,0) [0|4] "" CGM
 SG_ StHtdBkLvlLRVirtCtlReq : 7|3@0+ (1,0) [0|4] "" CGM
 SG_ StHtdCushLvlRFVirtCtlReq : 8|3@0+ (1,0) [0|4] "" CGM
 SG_ StHtdBkLvlRFVirtCtlReq : 11|3@0+ (1,0) [0|4] "" CGM
 SG_ StVntdCoolCushLvlLRVirtCtlReq : 14|3@0+ (1,0) [0|4] "" CGM
 SG_ StVntdCoolCushLvlRFVirtCtlReq : 18|3@0+ (1,0) [0|4] "" CGM
 SG_ StVntdCoolBkLvlRFVirtCtlReq : 21|3@0+ (1,0) [0|4] "" CGM
 SG_ StVntdCoolBkLvlRRVirtCtlReq : 25|3@0+ (1,0) [0|4] "" CGM
 SG_ StHtdCushLvlRRVirtCtlReq : 28|3@0+ (1,0) [0|4] "" CGM
 SG_ StHtdBkLvlRRVirtCtlReq : 31|3@0+ (1,0) [0|4] "" CGM
 SG_ StMemLRVirtCtlReq : 35|6@0+ (1,0) [0|33] "" CGM
 SG_ StVntdCoolCushLvlRRVirtCtlReq : 38|3@0+ (1,0) [0|4] "" CGM
 SG_ StMemRFVirtCtlReq : 45|6@0+ (1,0) [0|33] "" CGM
 SG_ RrDrOpnCmfRclCstChgSetReq : 49|3@0+ (1,0) [0|2] "" CGM
 SG_ StMemRRVirtCtlReq : 55|6@0+ (1,0) [0|33] "" CGM
 SG_ VirtFrtPsStInfoDspFRstReq : 56|1@0+ (1,0) [0|1] "" FPI
 SG_ PhnWrlsChrg1DsbldCstChgSetReq : 59|3@0+ (1,0) [0|2] "" WCM
 SG_ DlvryModeVwgCstChgSetReq : 62|3@0+ (1,0) [0|2] "" CGM

BO_ 1943 PDU_5354: 8 CGM
 SG_ RTESInstPwrWlIn : 7|14@0- (0.1,0) [-819.2|819.1] "KW" TCP
 SG_ RTESEVSEMaxPwr : 9|13@0+ (0.1,0) [0|819.1] "KW" TCP
 SG_ VehNeutAbuseSpdLimVal : 28|7@0+ (1,0) [0|127] "km/h" IPC,IPC_INT,VCU
 SG_ ClmCtlCbnFrtLtTempSet : 35|7@0+ (0.5,0) [0|63.5] "Deg C" TCP
 SG_ VehNeutAbuseIndReq : 37|2@0+ (1,0) [0|2] "" IPC,IPC_INT,VCU
 SG_ ClmCtlCbnFrtLtTempSet_Inv : 44|1@0+ (1,0) [0|1] "" TCP

BO_ 1123 PDU_5355: 6 FPI
 SG_ VirtFrtPsStInfoDspPwrBtnCtlAval : 4|1@0+ (1,0) [0|1] "" VCU
 SG_ FrtPsStInfoDspPwrBtnCurrSlnVal : 7|3@0+ (1,0) [0|2] "" VCU

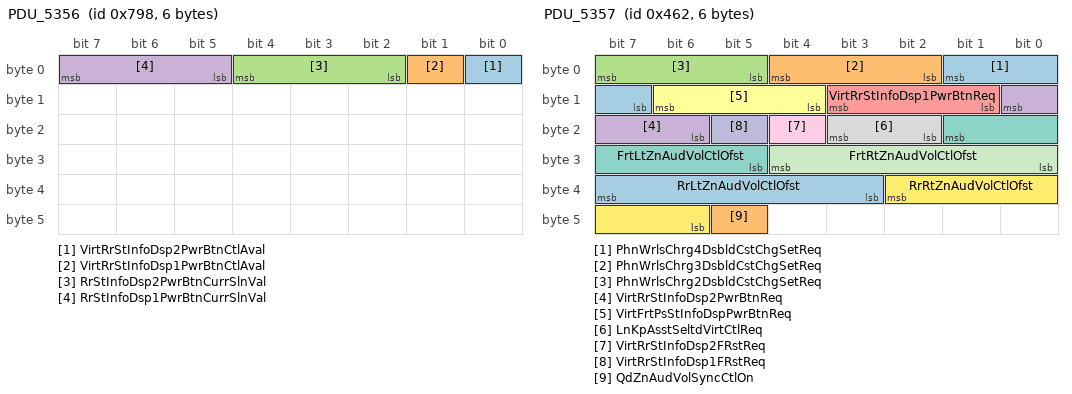
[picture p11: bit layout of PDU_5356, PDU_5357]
BO_ 1944 PDU_5356: 6 RSI
 SG_ VirtRrStInfoDsp2PwrBtnCtlAval : 0|1@0+ (1,0) [0|1] "" VCU
 SG_ VirtRrStInfoDsp1PwrBtnCtlAval : 1|1@0+ (1,0) [0|1] "" VCU
 SG_ RrStInfoDsp2PwrBtnCurrSlnVal : 4|3@0+ (1,0) [0|2] "" VCU
 SG_ RrStInfoDsp1PwrBtnCurrSlnVal : 7|3@0+ (1,0) [0|2] "" VCU

BO_ 1122 PDU_5357: 6 VCU
 SG_ PhnWrlsChrg4DsbldCstChgSetReq : 1|3@0+ (1,0) [0|2] "" WCM4
 SG_ PhnWrlsChrg3DsbldCstChgSetReq : 4|3@0+ (1,0) [0|2] "" WCM3
 SG_ PhnWrlsChrg2DsbldCstChgSetReq : 7|3@0+ (1,0) [0|2] "" WCM2
 SG_ VirtRrStInfoDsp2PwrBtnReq : 8|3@0+ (1,0) [0|2] "" RSI
 SG_ VirtRrStInfoDsp1PwrBtnReq : 11|3@0+ (1,0) [0|2] "" RSI
 SG_ VirtFrtPsStInfoDspPwrBtnReq : 14|3@0+ (1,0) [0|2] "" FPI
 SG_ FrtLtZnAudVolCtlOfst : 17|5@0- (1,0) [-16|15] "detent" AMP
 SG_ LnKpAsstSeltdVirtCtlReq : 19|2@0+ (1,0) [0|2] "" CGM
 SG_ VirtRrStInfoDsp2FRstReq : 20|1@0+ (1,0) [0|1] "" RSI
 SG_ VirtRrStInfoDsp1FRstReq : 21|1@0+ (1,0) [0|1] "" RSI
 SG_ FrtRtZnAudVolCtlOfst : 28|5@0- (1,0) [-16|15] "detent" AMP
 SG_ RrRtZnAudVolCtlOfst : 34|5@0- (1,0) [-16|15] "detent" AMP
 SG_ RrLtZnAudVolCtlOfst : 39|5@0- (1,0) [-16|15] "detent" AMP
 SG_ QdZnAudVolSyncCtlOn : 45|1@0+ (1,0) [0|1] "" AMP

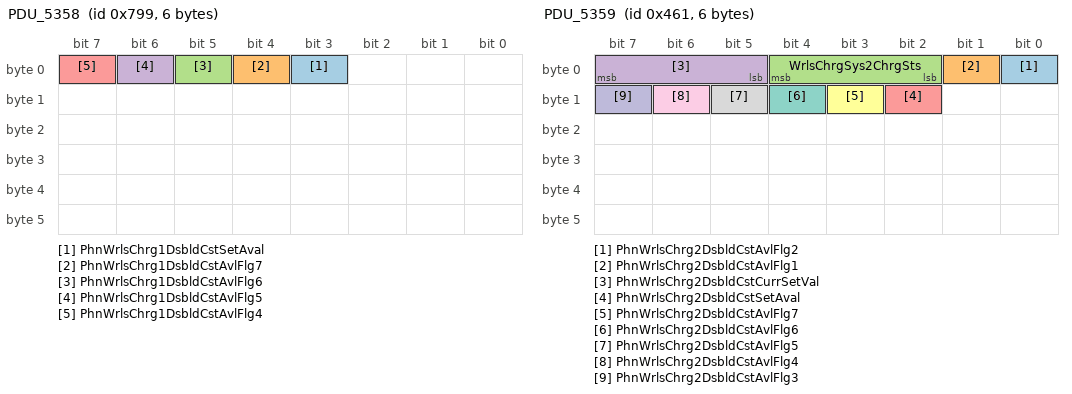
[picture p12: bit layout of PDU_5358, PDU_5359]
BO_ 1945 PDU_5358: 6 WCM
 SG_ PhnWrlsChrg1DsbldCstSetAval : 3|1@0+ (1,0) [0|1] "" VCU
 SG_ PhnWrlsChrg1DsbldCstAvlFlg7 : 4|1@0+ (1,0) [0|1] "" VCU
 SG_ PhnWrlsChrg1DsbldCstAvlFlg6 : 5|1@0+ (1,0) [0|1] "" VCU
 SG_ PhnWrlsChrg1DsbldCstAvlFlg5 : 6|1@0+ (1,0) [0|1] "" VCU
 SG_ PhnWrlsChrg1DsbldCstAvlFlg4 : 7|1@0+ (1,0) [0|1] "" VCU

BO_ 1121 PDU_5359: 6 WCM2
 SG_ PhnWrlsChrg2DsbldCstAvlFlg2 : 0|1@0+ (1,0) [0|1] "" VCU
 SG_ PhnWrlsChrg2DsbldCstAvlFlg1 : 1|1@0+ (1,0) [0|1] "" VCU
 SG_ WrlsChrgSys2ChrgSts : 4|3@0+ (1,0) [0|7] "" VCU
 SG_ PhnWrlsChrg2DsbldCstCurrSetVal : 7|3@0+ (1,0) [0|2] "" VCU
 SG_ PhnWrlsChrg2DsbldCstSetAval : 10|1@0+ (1,0) [0|1] "" VCU
 SG_ PhnWrlsChrg2DsbldCstAvlFlg7 : 11|1@0+ (1,0) [0|1] "" VCU
 SG_ PhnWrlsChrg2DsbldCstAvlFlg6 : 12|1@0+ (1,0) [0|1] "" VCU
 SG_ PhnWrlsChrg2DsbldCstAvlFlg5 : 13|1@0+ (1,0) [0|1] "" VCU
 SG_ PhnWrlsChrg2DsbldCstAvlFlg4 : 14|1@0+ (1,0) [0|1] "" VCU
 SG_ PhnWrlsChrg2DsbldCstAvlFlg3 : 15|1@0+ (1,0) [0|1] "" VCU

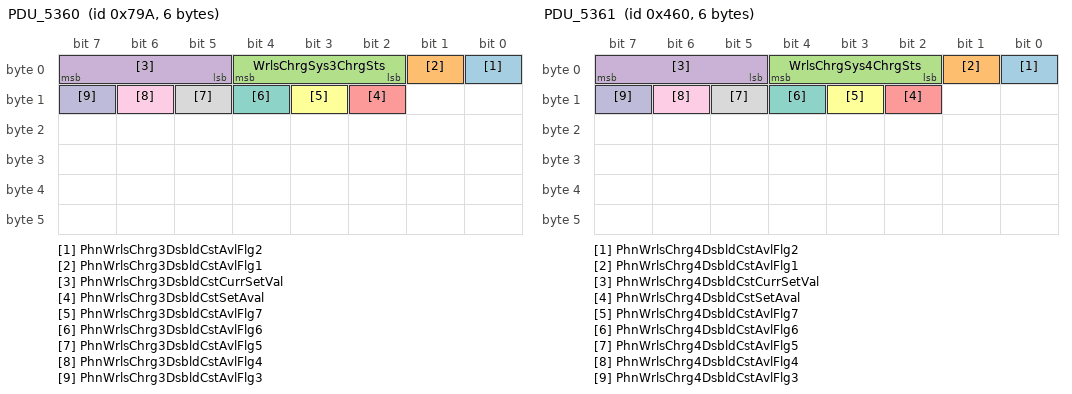
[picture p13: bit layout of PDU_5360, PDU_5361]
BO_ 1946 PDU_5360: 6 WCM3
 SG_ PhnWrlsChrg3DsbldCstAvlFlg2 : 0|1@0+ (1,0) [0|1] "" VCU
 SG_ PhnWrlsChrg3DsbldCstAvlFlg1 : 1|1@0+ (1,0) [0|1] "" VCU
 SG_ WrlsChrgSys3ChrgSts : 4|3@0+ (1,0) [0|7] "" VCU
 SG_ PhnWrlsChrg3DsbldCstCurrSetVal : 7|3@0+ (1,0) [0|2] "" VCU
 SG_ PhnWrlsChrg3DsbldCstSetAval : 10|1@0+ (1,0) [0|1] "" VCU
 SG_ PhnWrlsChrg3DsbldCstAvlFlg7 : 11|1@0+ (1,0) [0|1] "" VCU
 SG_ PhnWrlsChrg3DsbldCstAvlFlg6 : 12|1@0+ (1,0) [0|1] "" VCU
 SG_ PhnWrlsChrg3DsbldCstAvlFlg5 : 13|1@0+ (1,0) [0|1] "" VCU
 SG_ PhnWrlsChrg3DsbldCstAvlFlg4 : 14|1@0+ (1,0) [0|1] "" VCU
 SG_ PhnWrlsChrg3DsbldCstAvlFlg3 : 15|1@0+ (1,0) [0|1] "" VCU

BO_ 1120 PDU_5361: 6 WCM4
 SG_ PhnWrlsChrg4DsbldCstAvlFlg2 : 0|1@0+ (1,0) [0|1] "" VCU
 SG_ PhnWrlsChrg4DsbldCstAvlFlg1 : 1|1@0+ (1,0) [0|1] "" VCU
 SG_ WrlsChrgSys4ChrgSts : 4|3@0+ (1,0) [0|7] "" VCU
 SG_ PhnWrlsChrg4DsbldCstCurrSetVal : 7|3@0+ (1,0) [0|2] "" VCU
 SG_ PhnWrlsChrg4DsbldCstSetAval : 10|1@0+ (1,0) [0|1] "" VCU
 SG_ PhnWrlsChrg4DsbldCstAvlFlg7 : 11|1@0+ (1,0) [0|1] "" VCU
 SG_ PhnWrlsChrg4DsbldCstAvlFlg6 : 12|1@0+ (1,0) [0|1] "" VCU
 SG_ PhnWrlsChrg4DsbldCstAvlFlg5 : 13|1@0+ (1,0) [0|1] "" VCU
 SG_ PhnWrlsChrg4DsbldCstAvlFlg4 : 14|1@0+ (1,0) [0|1] "" VCU
 SG_ PhnWrlsChrg4DsbldCstAvlFlg3 : 15|1@0+ (1,0) [0|1] "" VCU

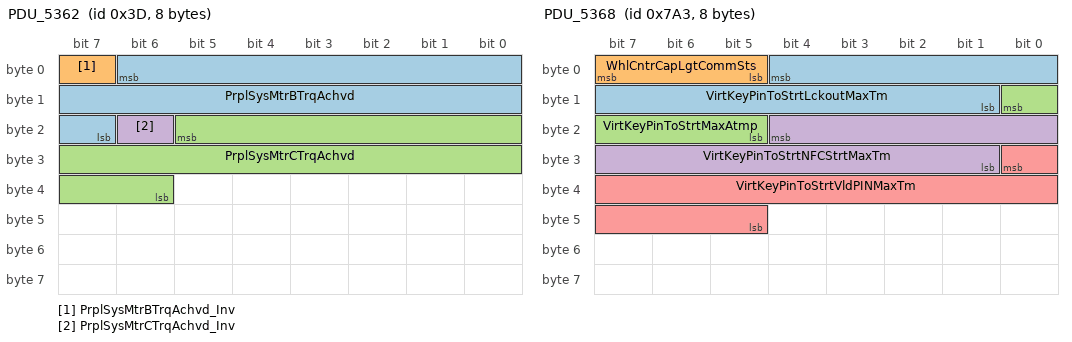
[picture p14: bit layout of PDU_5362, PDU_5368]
BO_ 61 PDU_5362: 8 CGM
 SG_ PrplSysMtrBTrqAchvd : 6|16@0- (0.125,0) [-4096|4095.88] "Nm" AMP,VCU
 SG_ PrplSysMtrBTrqAchvd_Inv : 7|1@0+ (1,0) [0|1] "" AMP,VCU
 SG_ PrplSysMtrCTrqAchvd : 21|16@0- (0.125,0) [-4096|4095.88] "Nm" AMP,VCU
 SG_ PrplSysMtrCTrqAchvd_Inv : 22|1@0+ (1,0) [0|1] "" AMP,VCU

BO_ 1954 PDU_5366: 8 CGM
 SG_ DrvrSeltdSpdLmtrVirtCtlAllwd : 2|1@0+ (1,0) [0|1] "" VCU
 SG_ AutoVehHldVirtCtlAval : 5|1@0+ (1,0) [0|1] "" VCU
 SG_ AutoVehHldVirtCurrSeltnVal : 7|2@0+ (1,0) [0|3] "" VCU
 SG_ TrfcJamAsstVirtCtlCurrSeltnVal : 24|2@0+ (1,0) [0|2] "" VCU
 SG_ DrvrSeltdSpdLmtrVirtCtlAval : 25|1@0+ (1,0) [0|1] "" VCU
 SG_ FuelDrOpnIndOn : 26|1@0+ (1,0) [0|1] "" VCU
 SG_ VehRefulngStat : 29|3@0+ (1,0) [0|2] "" IPC,IPC_INT,VCU
 SG_ DrvrSeltdSpdLmtrVirtCtlSeltnAvl : 31|2@0+ (1,0) [0|2] "" VCU
 SG_ TrfcJamAsstVirtCtlAval : 38|1@0+ (1,0) [0|1] "" VCU
 SG_ DrPstnLF : 44|8@0+ (0.392157,0) [0|100] "%" VCU
 SG_ ElecTransPrkSwSeltd : 47|1@0+ (1,0) [0|1] "" VCU
 SG_ DrPstnRF : 50|8@0+ (0.392157,0) [0|100] "%" VCU
 SG_ DrPstnLF_Inv : 51|1@0+ (1,0) [0|1] "" VCU
 SG_ DrPstnLF_DuD : 52|1@0+ (1,0) [0|1] "" VCU
 SG_ HybChrgModeStat : 56|1@0+ (1,0) [0|1] "" IPC,IPC_INT,VCU
 SG_ DrPstnRF_Inv : 57|1@0+ (1,0) [0|1] "" VCU
 SG_ DrPstnRF_DuD : 58|1@0+ (1,0) [0|1] "" VCU

BO_ 1955 PDU_5368: 8 VKM
 SG_ VirtKeyPinToStrtLckoutMaxTm : 4|12@0+ (1,0) [0|4095] "sec" CSM,VCU
 SG_ WhlCntrCapLgtCommSts : 7|3@0+ (1,0) [0|4] "" CGM
 SG_ VirtKeyPinToStrtMaxAtmp : 8|4@0+ (1,0) [0|15] "" CSM,VCU
 SG_ VirtKeyPinToStrtNFCStrtMaxTm : 20|12@0+ (1,0) [0|4095] "sec" CSM,VCU
 SG_ VirtKeyPinToStrtVldPINMaxTm : 24|12@0+ (1,0) [0|4095] "sec" CSM,VCU

BO_ 737 PDU_5370: 6 VCU
 SG_ SrrndVwCamsOnReqd : 4|1@0+ (1,0) [0|1] "" CGM
 SG_ RmtVidImgXferActv : 5|1@0+ (1,0) [0|1] "" TCP

BO_ 1917 PDU_5371: 8 CGM
 SG_ VehConPrvdrLrnSts : 7|2@0+ (1,0) [0|2] "" TCP

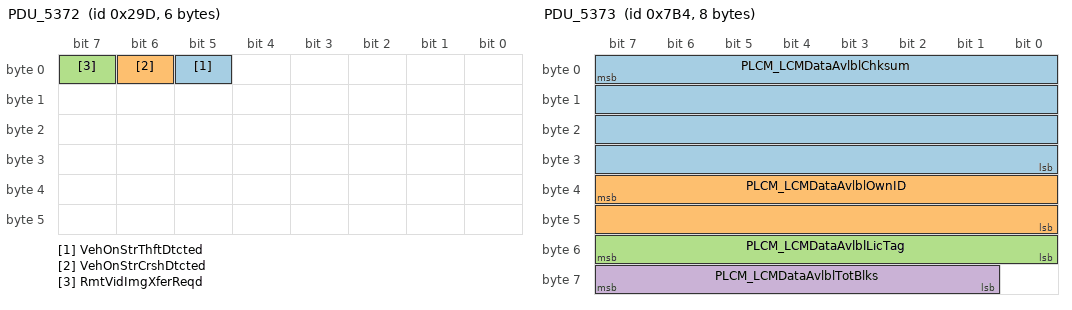
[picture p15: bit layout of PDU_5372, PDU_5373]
BO_ 669 PDU_5372: 6 TCP
 SG_ VehOnStrThftDtcted : 5|1@0+ (1,0) [0|1] "" VCU
 SG_ VehOnStrCrshDtcted : 6|1@0+ (1,0) [0|1] "" VCU
 SG_ RmtVidImgXferReqd : 7|1@0+ (1,0) [0|1] "" VCU

BO_ 1972 PDU_5373: 8 PLCM
 SG_ PLCM_LCMDataAvlblChksum : 7|32@0+ (1,0) [0|4.29497e+009] "" VCU
 SG_ PLCM_LCMDataAvlblOwnID : 39|16@0+ (1,0) [0|65535] "" VCU
 SG_ PLCM_LCMDataAvlblLicTag : 55|8@0+ (1,0) [0|255] "" VCU
 SG_ PLCM_LCMDataAvlblTotBlks : 63|7@0+ (1,0) [0|127] "" VCU

BO_ 1973 PDU_5374: 6 PLCM
 SG_ ChrgCommBridgeDrvrNtfn : 3|3@0+ (1,0) [0|4] "" VCU
 SG_ ChrgCommSLACSts : 7|4@0+ (1,0) [0|12] "" VCU

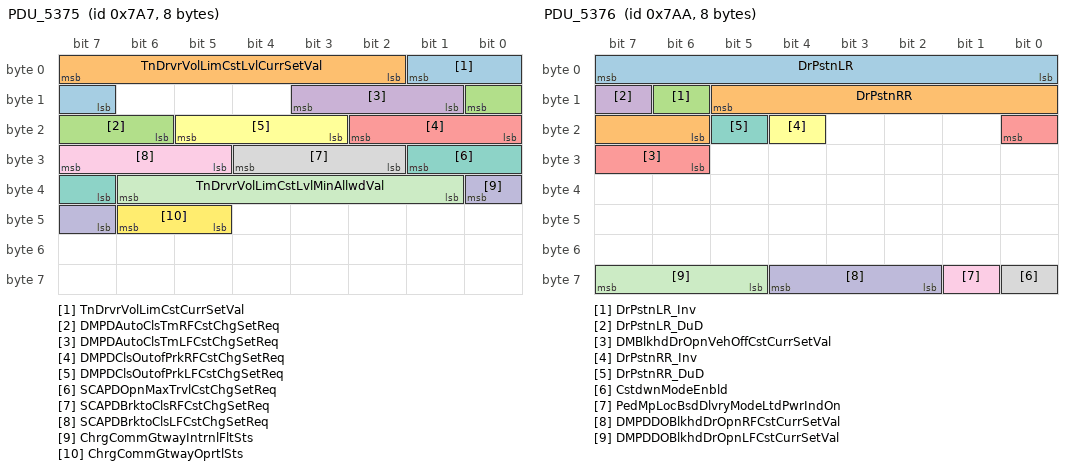
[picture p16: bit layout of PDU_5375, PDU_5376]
BO_ 1959 PDU_5375: 8 VCU
 SG_ TnDrvrVolLimCstCurrSetVal : 1|3@0+ (1,0) [0|2] "" TCP
 SG_ TnDrvrVolLimCstLvlCurrSetVal : 7|6@0+ (1,0) [0|63] "counts" TCP
 SG_ DMPDAutoClsTmRFCstChgSetReq : 8|3@0+ (1,0) [0|3] "" CGM
 SG_ DMPDAutoClsTmLFCstChgSetReq : 11|3@0+ (1,0) [0|3] "" CGM
 SG_ DMPDClsOutofPrkRFCstChgSetReq : 18|3@0+ (1,0) [0|2] "" CGM
 SG_ DMPDClsOutofPrkLFCstChgSetReq : 21|3@0+ (1,0) [0|2] "" CGM
 SG_ SCAPDOpnMaxTrvlCstChgSetReq : 25|3@0+ (1,0) [0|3] "" CGM
 SG_ SCAPDBrktoClsRFCstChgSetReq : 28|3@0+ (1,0) [0|2] "" CGM
 SG_ SCAPDBrktoClsLFCstChgSetReq : 31|3@0+ (1,0) [0|2] "" CGM
 SG_ ChrgCommGtwayIntrnlFltSts : 32|2@0+ (1,0) [0|2] "" CGM,PLCM
 SG_ TnDrvrVolLimCstLvlMinAllwdVal : 38|6@0+ (1,0) [0|63] "counts" TCP
 SG_ ChrgCommGtwayOprtlSts : 46|2@0+ (1,0) [0|3] "" CGM,PLCM

BO_ 1962 PDU_5376: 8 CGM
 SG_ DrPstnLR : 7|8@0+ (0.392157,0) [0|100] "%" VCU
 SG_ DrPstnRR : 13|8@0+ (0.392157,0) [0|100] "%" VCU
 SG_ DrPstnLR_Inv : 14|1@0+ (1,0) [0|1] "" VCU
 SG_ DrPstnLR_DuD : 15|1@0+ (1,0) [0|1] "" VCU
 SG_ DMBlkhdDrOpnVehOffCstCurrSetVal : 16|3@0+ (1,0) [0|2] "" VCU
 SG_ DrPstnRR_Inv : 20|1@0+ (1,0) [0|1] "" VCU
 SG_ DrPstnRR_DuD : 21|1@0+ (1,0) [0|1] "" VCU
 SG_ CstdwnModeEnbld : 56|1@0+ (1,0) [0|1] "" IPC,IPC_INT,VCU
 SG_ PedMpLocBsdDlvryModeLtdPwrIndOn : 57|1@0+ (1,0) [0|1] "" VCU
 SG_ DMPDDOBlkhdDrOpnRFCstCurrSetVal : 60|3@0+ (1,0) [0|2] "" VCU
 SG_ DMPDDOBlkhdDrOpnLFCstCurrSetVal : 63|3@0+ (1,0) [0|2] "" VCU

BO_ 1963 PDU_5377: 8 CGM
 SG_ SCAOOAByKeyFobLFCstCurrSetVal : 4|3@0+ (1,0) [0|2] "" VCU
 SG_ SCAPDBrktoClsLFCstCurrSetVal : 8|3@0+ (1,0) [0|2] "" VCU
 SG_ SCAOOAByVirtKeyLFCstCurrSetVal : 14|3@0+ (1,0) [0|2] "" VKM,VCU
 SG_ SCAPDOpnMaxTrvlCstCurrSetVal : 18|3@0+ (1,0) [0|3] "" VCU
 SG_ CoDrvrDrOpn_DuD : 24|1@0+ (1,0) [0|1] "" Vector__XXX
 SG_ CoDrvrDrOpn : 25|1@0+ (1,0) [0|1] "" VCU
 SG_ DrRROpn_Inv : 26|1@0+ (1,0) [0|1] "" VCU
 SG_ DrRROpn_DuD : 27|1@0+ (1,0) [0|1] "" Vector__XXX
 SG_ DrRROpn : 28|1@0+ (1,0) [0|1] "" VCU
 SG_ DrLROpn_Inv : 29|1@0+ (1,0) [0|1] "" VCU
 SG_ DrLROpn_DuD : 30|1@0+ (1,0) [0|1] "" Vector__XXX
 SG_ DrLROpn : 31|1@0+ (1,0) [0|1] "" VCU
 SG_ SCAPwrDrMtnRRVirtCtlRrAllwd : 32|1@0+ (1,0) [0|1] "" VCU
 SG_ SCAPwrDrMtnRRVirtCtlFrtAllwd : 33|1@0+ (1,0) [0|1] "" VCU
 SG_ SCAPwrDrMtnLRVirtCtlRrAllwd : 35|1@0+ (1,0) [0|1] "" VCU
 SG_ SCAPwrDrMtnLRVirtCtlFrtAllwd : 36|1@0+ (1,0) [0|1] "" VCU
 SG_ SCAPwrDrMtnLFVirtCtlAllwd : 37|1@0+ (1,0) [0|1] "" VCU
 SG_ CoDrvrDrOpn_Inv : 39|1@0+ (1,0) [0|1] "" VCU
 SG_ SdDrRRInMtnActv : 42|1@0+ (1,0) [0|1] "" VCU
 SG_ SdDrRFInMtnActv : 43|1@0+ (1,0) [0|1] "" VCU
 SG_ SdDrLRInMtnActv : 44|1@0+ (1,0) [0|1] "" VCU
 SG_ SdDrLFInMtnActv : 45|1@0+ (1,0) [0|1] "" VCU
 SG_ HtdStrgWhlInd : 48|2@0+ (1,0) [0|3] "" VCU
 SG_ FltDrvrActvRmtCstCurrSetVal : 51|3@0+ (1,0) [0|2] "" TCP
 SG_ LSCMBABP_ReqActvAuth : 59|1@0+ (1,0) [0|1] "" TCP
 SG_ FIMRIMABP_BrkgReqAuth : 60|1@0+ (1,0) [0|1] "" TCP
 SG_ ChsDynoModeEnbld : 61|1@0+ (1,0) [0|1] "" VCU
 SG_ HtdStrgWhlLvlIndOn : 62|1@0+ (1,0) [0|1] "" VCU

BO_ 1100 PDU_5382: 8 VCU
 SG_ HVACICRHtdArmrstLvlChgRrLt : 1|3@0+ (1,-3) [-3|4] "" Vector__XXX
 SG_ HVACICRHtdArmrstLvlChgFrtRt : 4|3@0+ (1,-3) [-3|4] "" Vector__XXX
 SG_ HVACICRHtdArmrstLvlChgFrtLt : 7|3@0+ (1,-3) [-3|4] "" Vector__XXX
 SG_ HVACICRHtdArmrstLvlFrtRt : 9|2@0+ (1,0) [0|3] "" Vector__XXX
 SG_ HVACICRHtdArmrstLvlFrtLt : 11|2@0+ (1,0) [0|3] "" Vector__XXX
 SG_ HVACICRHtdArmrstLvlChgRrRt : 14|3@0+ (1,-3) [-3|4] "" Vector__XXX
 SG_ HVACICRHtdArmrstLvlFrtRtActv : 16|1@0+ (1,0) [0|1] "" Vector__XXX
 SG_ HVACICRHtdArmrstLvlFrtLtActv : 17|1@0+ (1,0) [0|1] "" Vector__XXX
 SG_ SD265_ARC : 19|2@0+ (1,0) [0|3] "" Vector__XXX
 SG_ HVACICRHtdArmrstLvlRrRt : 21|2@0+ (1,0) [0|3] "" Vector__XXX
 SG_ HVACICRHtdArmrstLvlRrLt : 23|2@0+ (1,0) [0|3] "" Vector__XXX
 SG_ HVACInfoCtlRqBlwLvlChgThrdRw : 24|5@0- (1,0) [-16|15] "" Vector__XXX
 SG_ HVACInfoCtlRqAirDstThrdRw : 28|4@0+ (1,0) [0|8] "" Vector__XXX
 SG_ HVACInfoCtlRqAirDstChgNxtThrdRw : 29|1@0+ (1,0) [0|1] "" Vector__XXX
 SG_ HVACICRHtdArmrstLvlRrRtActv : 30|1@0+ (1,0) [0|1] "" Vector__XXX
 SG_ HVACICRHtdArmrstLvlRrLtActv : 31|1@0+ (1,0) [0|1] "" Vector__XXX
 SG_ HVACInfoCtlRqBlwLvlThrdRw : 35|4@0+ (1,0) [0|15] "" Vector__XXX
 SG_ HVACInfoCtlRqTempChgThrdRw : 45|7@0- (1,0) [-64|63] "" Vector__XXX
 SG_ HVACInfoCtlRqSyncThrdRwChg : 46|1@0+ (1,0) [0|1] "" Vector__XXX
 SG_ HVACInfoCtlRqBlwLvlThrdRwActv : 47|1@0+ (1,0) [0|1] "" Vector__XXX
 SG_ HVACInfoCtlRqTempLvlThrdRw : 54|7@0- (1,0) [-64|63] "" Vector__XXX
 SG_ SD264_ARC : 59|2@0+ (1,0) [0|3] "" Vector__XXX
 SG_ HVACInfoCtlRqThrdRwPwrSetChg : 60|1@0+ (1,0) [0|1] "" Vector__XXX
 SG_ HVACInfoCtlRqThrdRwLckSetChg : 61|1@0+ (1,0) [0|1] "" Vector__XXX
 SG_ HVACInfoCtlRqThrdRwAutoSetChg : 62|1@0+ (1,0) [0|1] "" Vector__XXX
 SG_ HVACInfoCtlRqTempLvlThrdRwActv : 63|1@0+ (1,0) [0|1] "" Vector__XXX

BO_ 1967 PDU_5383: 6 PLCM
 SG_ ChrgCommBridgeOprtlSts : 5|2@0+ (1,0) [0|3] "" CGM,VCU
 SG_ ChrgCommBridgeIntrnlFltSts : 7|2@0+ (1,0) [0|2] "" CGM,VCU

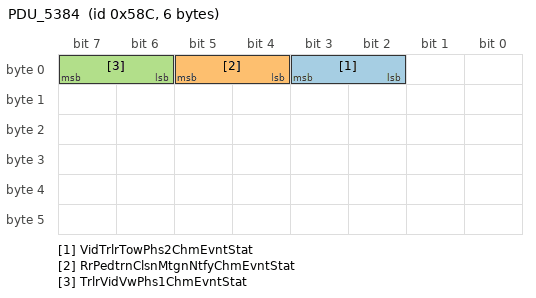
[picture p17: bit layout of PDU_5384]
BO_ 1420 PDU_5384: 6 CGM
 SG_ VidTrlrTowPhs2ChmEvntStat : 3|2@0+ (1,0) [0|2] "" IPC,IPC_INT,VCU
 SG_ RrPedtrnClsnMtgnNtfyChmEvntStat : 5|2@0+ (1,0) [0|2] "" IPC,IPC_INT,VCU
 SG_ TrlrVidVwPhs1ChmEvntStat : 7|2@0+ (1,0) [0|2] "" IPC,IPC_INT,VCU

BO_ 1113 PDU_5385: 8 CSM
 SG_ DMHrnOutPrkCstChgSetReq : 0|3@0+ (1,0) [0|2] "" Vector__XXX
 SG_ DMCabLgtPrkCstChgSetReq : 3|3@0+ (1,0) [0|2] "" Vector__XXX
 SG_ InfoFrtSnshdPstnReq : 7|4@0+ (1,0) [0|13] "" Vector__XXX
 SG_ RmtVidVwgLgtFlshReqd : 8|1@0+ (1,0) [0|1] "" Vector__XXX
 SG_ RmtVidVwgIntrLgtReqd : 9|1@0+ (1,0) [0|1] "" Vector__XXX
 SG_ RmtVidVwgExtLgtReqd : 10|1@0+ (1,0) [0|1] "" Vector__XXX
 SG_ HtdArmrstSyncCstChgSetReq : 13|3@0+ (1,0) [0|2] "" Vector__XXX
 SG_ AutoAirOtltAmgCstChgSetReq : 17|3@0+ (1,0) [0|2] "" Vector__XXX
 SG_ ArflBsdOnOccpRrPsCstChgSetReq : 20|3@0+ (1,0) [0|2] "" Vector__XXX
 SG_ ArflBsdOnOccpFrtPsCstChgSetReq : 23|3@0+ (1,0) [0|2] "" Vector__XXX
 SG_ TrlrTireLkDtnUserReq : 24|2@0+ (1,0) [0|3] "" Vector__XXX
 SG_ CbnAirClnFltrtnCstChgSetReq : 27|3@0+ (1,0) [0|2] "" Vector__XXX
 SG_ AutoNckScrfCstChgSetReq : 30|3@0+ (1,0) [0|3] "" Vector__XXX
 SG_ ClmCtlRrBlw2CtlCktOORHiFlrSts : 32|2@0+ (1,0) [0|2] "" Vector__XXX
 SG_ ClmCtlRrBlw2CtlCktFlrSts : 34|2@0+ (1,0) [0|2] "" Vector__XXX
 SG_ DuctAirTempRrVntRwVltgDatRxd : 35|1@0+ (1,0) [0|1] "" Vector__XXX
 SG_ DuctAirTempRrRtVntRwVltgDatRxd : 36|1@0+ (1,0) [0|1] "" Vector__XXX
 SG_ DuctAirTempRrRtFloorRwVltDatRxd : 37|1@0+ (1,0) [0|1] "" Vector__XXX
 SG_ DuctAirTempRrFloorRwVltgDatRxd : 38|1@0+ (1,0) [0|1] "" Vector__XXX
 SG_ ClmCtlRrBlwCtlCktOORHiFlrSts : 41|2@0+ (1,0) [0|2] "" Vector__XXX
 SG_ ClmCtlRrBlwCtlCktFlrSts : 43|2@0+ (1,0) [0|2] "" Vector__XXX
 SG_ ClmCtlRrBlw2CtlCktStsDatRxd : 44|1@0+ (1,0) [0|1] "" Vector__XXX
 SG_ ClmCtlRrBlw2CtlCktOORLoFlrSts : 46|2@0+ (1,0) [0|2] "" Vector__XXX
 SG_ InfoThmSeltnExpdCurrSetVal : 52|8@0+ (1,0) [0|255] "" Vector__XXX
 SG_ ClmCtlRrBlwCtlCktStsDatRxd : 53|1@0+ (1,0) [0|1] "" Vector__XXX
 SG_ ClmCtlRrBlwCtlCktOORLoFlrSts : 55|2@0+ (1,0) [0|2] "" Vector__XXX
 SG_ OccptLtBehindRmndrCstChgSetReq : 60|3@0+ (1,0) [0|2] "" Vector__XXX

BA_DEF_ SG_  "SignalType" STRING ;
BA_DEF_ SG_  "SignalLongName" STRING ;
BA_DEF_ BO_  "GenMsgCycleTime" INT 0 10000;
BA_DEF_ BO_  "GenMsgSendType" ENUM "cyclicX","spontanX","cyclicIfActiveX","spontanWithDelay","cyclicAndSpontanX","cyclicAndSpontanWithDelay","spontanWithRepetition","cyclicIfActiveAndSpontanWD";
BA_DEF_DEF_  "SignalType" "";
BA_DEF_DEF_  "SignalLongName" "";
BA_DEF_DEF_  "GenMsgCycleTime" 0;
BA_DEF_DEF_  "GenMsgSendType" "cyclicX";
BA_ "GenMsgCycleTime" BO_ 733 100;
BA_ "GenMsgCycleTime" BO_ 734 100;
BA_ "GenMsgCycleTime" BO_ 1154 1000;
BA_ "GenMsgCycleTime" BO_ 1913 1000;
BA_ "GenMsgCycleTime" BO_ 229 50;
BA_ "GenMsgCycleTime" BO_ 537 50;
BA_ "GenMsgCycleTime" BO_ 1304 1000;
BA_ "GenMsgCycleTime" BO_ 1445 1000;
BA_ "GenMsgCycleTime" BO_ 1910 1000;
BA_ "GenMsgCycleTime" BO_ 1912 1000;
BA_ "GenMsgCycleTime" BO_ 1915 1000;
BA_ "GenMsgCycleTime" BO_ 1916 1000;
BA_ "GenMsgCycleTime" BO_ 735 100;
BA_ "GenMsgCycleTime" BO_ 1134 1000;
BA_ "GenMsgCycleTime" BO_ 1933 1000;
BA_ "GenMsgCycleTime" BO_ 1131 1000;
BA_ "GenMsgCycleTime" BO_ 1133 1000;
BA_ "GenMsgCycleTime" BO_ 1934 1000;
BA_ "GenMsgCycleTime" BO_ 1341 1000;
BA_ "GenMsgCycleTime" BO_ 1339 1000;
BA_ "GenMsgCycleTime" BO_ 1337 1000;
BA_ "GenMsgCycleTime" BO_ 1144 1000;
BA_ "GenMsgCycleTime" BO_ 1937 1000;
BA_ "GenMsgCycleTime" BO_ 1129 1000;
BA_ "GenMsgCycleTime" BO_ 1938 1000;
BA_ "GenMsgCycleTime" BO_ 1128 1000;
BA_ "GenMsgCycleTime" BO_ 1939 1000;
BA_ "GenMsgCycleTime" BO_ 1127 1000;
BA_ "GenMsgCycleTime" BO_ 736 200;
BA_ "GenMsgCycleTime" BO_ 1942 1000;
BA_ "GenMsgCycleTime" BO_ 1124 1000;
BA_ "GenMsgCycleTime" BO_ 1943 1000;
BA_ "GenMsgCycleTime" BO_ 1123 1000;
BA_ "GenMsgCycleTime" BO_ 1944 1000;
BA_ "GenMsgCycleTime" BO_ 1122 1000;
BA_ "GenMsgCycleTime" BO_ 1945 1000;
BA_ "GenMsgCycleTime" BO_ 1121 1000;
BA_ "GenMsgCycleTime" BO_ 1946 1000;
BA_ "GenMsgCycleTime" BO_ 1120 1000;
BA_ "GenMsgCycleTime" BO_ 61 12.5;
BA_ "GenMsgCycleTime" BO_ 1954 1000;
BA_ "GenMsgCycleTime" BO_ 1955 1000;
BA_ "GenMsgCycleTime" BO_ 737 100;
BA_ "GenMsgCycleTime" BO_ 1917 1000;
BA_ "GenMsgCycleTime" BO_ 669 100;
BA_ "GenMsgCycleTime" BO_ 1973 1000;
BA_ "GenMsgCycleTime" BO_ 1959 1000;
BA_ "GenMsgCycleTime" BO_ 1962 1000;
BA_ "GenMsgCycleTime" BO_ 1963 1000;
BA_ "GenMsgCycleTime" BO_ 1100 1000;
BA_ "GenMsgCycleTime" BO_ 1967 1000;
BA_ "GenMsgCycleTime" BO_ 1420 1000;
BA_ "GenMsgCycleTime" BO_ 1113 1000;
BA_ "SignalType" SG_ 733 TlLmpAuxLftOtg "ENM";
BA_ "SignalLongName" SG_ 733 TlLmpAuxLftOtg "Tail Lamp Aux Left Outage";
BA_ "SignalType" SG_ 733 RvrsLmpLtActv "ENM";
BA_ "SignalLongName" SG_ 733 RvrsLmpLtActv "Reverse Lamp Active";
BA_ "SignalType" SG_ 733 PrkLmpRtOtg "ENM";
BA_ "SignalLongName" SG_ 733 PrkLmpRtOtg "Park Lamp Right Outage";
BA_ "SignalType" SG_ 733 PrkLmpLftOtg "ENM";
BA_ "SignalLongName" SG_ 733 PrkLmpLftOtg "Park Lamp Left Outage";
BA_ "SignalType" SG_ 733 PrkLmpAuxRtOtg "ENM";
BA_ "SignalLongName" SG_ 733 PrkLmpAuxRtOtg "Park Lamp Aux Right Outage";
BA_ "SignalType" SG_ 733 PrkLmpAuxLftOtg "ENM";
BA_ "SignalLongName" SG_ 733 PrkLmpAuxLftOtg "Park Lamp Aux Left Outage";
BA_ "SignalType" SG_ 733 BLS_BrkLmpRtActv "ENM";
BA_ "SignalLongName" SG_ 733 BLS_BrkLmpRtActv "Brake Lamps Status : Brake Lamp Right Active";
BA_ "SignalType" SG_ 733 BLS_BrkLmpLtActv "ENM";
BA_ "SignalLongName" SG_ 733 BLS_BrkLmpLtActv "Brake Lamps Status : Brake Lamp Left Active";
BA_ "SignalType" SG_ 733 TlLmpRtOtg "ENM";
BA_ "SignalLongName" SG_ 733 TlLmpRtOtg "Tail Lamp Right Outage";
BA_ "SignalType" SG_ 733 TlLmpLftOtg "ENM";
BA_ "SignalLongName" SG_ 733 TlLmpLftOtg "Tail Lamp Left Outage";
BA_ "SignalType" SG_ 733 TlLmpAuxRtOtg "ENM";
BA_ "SignalLongName" SG_ 733 TlLmpAuxRtOtg "Tail Lamp Aux Right Outage";
BA_ "SignalType" SG_ 734 BGI5_TrnLmpRtFncActv "ENM";
BA_ "SignalLongName" SG_ 734 BGI5_TrnLmpRtFncActv "Body General Information 5 : Turn Lamp Right Function Active";
BA_ "SignalType" SG_ 734 BGI5_TrnLmpLtFncActv "ENM";
BA_ "SignalLongName" SG_ 734 BGI5_TrnLmpLtFncActv "Body General Information 5 : Turn Lamp Left Function Active";
BA_ "SignalType" SG_ 1154 ChmPrdcrQdrntRRSOH "ENM";
BA_ "SignalLongName" SG_ 1154 ChmPrdcrQdrntRRSOH "Chime Producer Quadrant Right Rear State of Health";
BA_ "SignalType" SG_ 1154 ChmPrdcrQdrntRFSOH "ENM";
BA_ "SignalLongName" SG_ 1154 ChmPrdcrQdrntRFSOH "Chime Producer Quadrant Right Front State of Health";
BA_ "SignalType" SG_ 1154 ChmPrdcrQdrntLRSOH "ENM";
BA_ "SignalLongName" SG_ 1154 ChmPrdcrQdrntLRSOH "Chime Producer Quadrant Left Rear State of Health";
BA_ "SignalType" SG_ 1154 ChmPrdcrQdrntLFSOH "ENM";
BA_ "SignalLongName" SG_ 1154 ChmPrdcrQdrntLFSOH "Chime Producer Quadrant Left Front State of Health";
BA_ "SignalLongName" SG_ 1913 SD142_ARC "Serial Data 142 : Alive Rolling Count";
BA_ "SignalType" SG_ 1913 InfoHtdFrtWshldSetChgReqd "ENM";
BA_ "SignalLongName" SG_ 1913 InfoHtdFrtWshldSetChgReqd "Serial Data 142 : Infotainment Heated Front Windshield Setting Change Requested";
BA_ "SignalType" SG_ 1913 InfoHtdFrtWshldSet "ENM";
BA_ "SignalLongName" SG_ 1913 InfoHtdFrtWshldSet "Serial Data 142 : Infotainment Heated Front Windshield Setting";
BA_ "SignalType" SG_ 229 DrvModeConfDrvrResp "ENM";
BA_ "SignalLongName" SG_ 229 DrvModeConfDrvrResp "Drive Mode Confirmation Driver Response";
BA_ "SignalType" SG_ 537 MaxPwrModeConfDrvrResp "ENM";
BA_ "SignalLongName" SG_ 537 MaxPwrModeConfDrvrResp "Max Power Mode Confirmation Driver Response";
BA_ "SignalLongName" SG_ 1304 HVACICRBlwLvlChgRrRt "Serial Data 163 : HVAC Infotainment Controls Request Blower Level Change Rear Right";
BA_ "SignalLongName" SG_ 1304 HVACICRBlwLvlChgFrtRt "Serial Data 163 : HVAC Infotainment Controls Request Blower Level Change Front Right";
BA_ "SignalLongName" SG_ 1304 HVACICRBlwLvlRrRt "Serial Data 163 : HVAC Infotainment Controls Request Blower Level Rear Right";
BA_ "SignalLongName" SG_ 1304 HVACICRBlwLvlFrtRt "Serial Data 163 : HVAC Infotainment Controls Request Blower Level Front Right";
BA_ "SignalType" SG_ 1304 HVACICRMcrClmStSyncRrRt "ENM";
BA_ "SignalLongName" SG_ 1304 HVACICRMcrClmStSyncRrRt "Serial Data 163 : HVAC Infotainment Controls Request Micro Climate Seat Sync Rear Right";
BA_ "SignalType" SG_ 1304 HVACICRMcrClmStSyncRrLt "ENM";
BA_ "SignalLongName" SG_ 1304 HVACICRMcrClmStSyncRrLt "Serial Data 163 : HVAC Infotainment Controls Request Micro Climate Seat Sync Rear Left";
BA_ "SignalType" SG_ 1304 HVACICRMcrClmStSyncFrtRt "ENM";
BA_ "SignalLongName" SG_ 1304 HVACICRMcrClmStSyncFrtRt "Serial Data 163 : HVAC Infotainment Controls Request Micro Climate Seat Sync Front Right";
BA_ "SignalType" SG_ 1304 HVACICRMcrClmStSyncFrtLt "ENM";
BA_ "SignalLongName" SG_ 1304 HVACICRMcrClmStSyncFrtLt "Serial Data 163 : HVAC Infotainment Controls Request Micro Climate Seat Sync Front Left";
BA_ "SignalLongName" SG_ 1304 HVACICRNckScrfLvlChgFrtLt "Serial Data 163 : HVAC Infotainment Controls Request Neck Scarf Level Change Front Left";
BA_ "SignalLongName" SG_ 1304 HVACICRNckScrfLvlChgRrRt "Serial Data 163 : HVAC Infotainment Controls Request Neck Scarf Level Change Rear Right";
BA_ "SignalLongName" SG_ 1304 HVACICRNckScrfLvlChgRrLt "Serial Data 163 : HVAC Infotainment Controls Request Neck Scarf Level Change Rear Left";
BA_ "SignalLongName" SG_ 1304 HVACICRNckScrfLvlChgFrtRt "Serial Data 163 : HVAC Infotainment Controls Request Neck Scarf Level Change Front Right";
BA_ "SignalType" SG_ 1304 HVACICRNckScrfLvlRrLt "ENM";
BA_ "SignalLongName" SG_ 1304 HVACICRNckScrfLvlRrLt "Serial Data 163 : HVAC Infotainment Controls Request Neck Scarf Level Rear Left";
BA_ "SignalType" SG_ 1304 HVACICRNckScrfLvlFrtRt "ENM";
BA_ "SignalLongName" SG_ 1304 HVACICRNckScrfLvlFrtRt "Serial Data 163 : HVAC Infotainment Controls Request Neck Scarf Level Front Right";
BA_ "SignalType" SG_ 1304 HVACICRNckScrfLvlFrtLt "ENM";
BA_ "SignalLongName" SG_ 1304 HVACICRNckScrfLvlFrtLt "Serial Data 163 : HVAC Infotainment Controls Request Neck Scarf Level Front Left";
BA_ "SignalType" SG_ 1304 HVACICRFrtRtAutoSetChg "ENM";
BA_ "SignalLongName" SG_ 1304 HVACICRFrtRtAutoSetChg "Serial Data 163 : HVAC Infotainment Controls Request Front Right Auto Setting Change";
BA_ "SignalType" SG_ 1304 HVACICRBlwLvlRrRtActv "ENM";
BA_ "SignalLongName" SG_ 1304 HVACICRBlwLvlRrRtActv "Serial Data 163 : HVAC Infotainment Controls Request Blower Level Rear Right Active";
BA_ "SignalType" SG_ 1304 HVACICRBlwLvlFrtRtActv "ENM";
BA_ "SignalLongName" SG_ 1304 HVACICRBlwLvlFrtRtActv "Serial Data 163 : HVAC Infotainment Controls Request Blower Level Front Right Active";
BA_ "SignalLongName" SG_ 1304 SD163_ARC "Serial Data 163 : Alive Rolling Count";
BA_ "SignalType" SG_ 1304 HVACICRNckScrfLvlRrRt "ENM";
BA_ "SignalLongName" SG_ 1304 HVACICRNckScrfLvlRrRt "Serial Data 163 : HVAC Infotainment Controls Request Neck Scarf Level Rear Right";
BA_ "SignalType" SG_ 1304 HVACICRRrRtAutoSetChg "ENM";
BA_ "SignalLongName" SG_ 1304 HVACICRRrRtAutoSetChg "Serial Data 163 : HVAC Infotainment Controls Request Rear Right Auto Setting Change";
BA_ "SignalType" SG_ 1304 HVACICRNckScrfLvlRrRtActv "ENM";
BA_ "SignalLongName" SG_ 1304 HVACICRNckScrfLvlRrRtActv "Serial Data 163 : HVAC Infotainment Controls Request Neck Scarf Level Rear Right Active";
BA_ "SignalType" SG_ 1304 HVACICRNckScrfLvlRrLtActv "ENM";
BA_ "SignalLongName" SG_ 1304 HVACICRNckScrfLvlRrLtActv "Serial Data 163 : HVAC Infotainment Controls Request Neck Scarf Level Rear Left Active";
BA_ "SignalType" SG_ 1304 HVACICRNckScrfLvlFrtRtActv "ENM";
BA_ "SignalLongName" SG_ 1304 HVACICRNckScrfLvlFrtRtActv "Serial Data 163 : HVAC Infotainment Controls Request Neck Scarf Level Front Right Active";
BA_ "SignalType" SG_ 1304 HVACICRNckScrfLvlFrtLtActv "ENM";
BA_ "SignalLongName" SG_ 1304 HVACICRNckScrfLvlFrtLtActv "Serial Data 163 : HVAC Infotainment Controls Request Neck Scarf Level Front Left Active";
BA_ "SignalLongName" SG_ 1445 CbnAirTempCalcdVal "Cabin Air Temperature Calculated Information : Cabin Air Temperature Calculated Value";
BA_ "SignalType" SG_ 1445 SCAPwrDrMtnRRVirtCtlAval "ENM";
BA_ "SignalLongName" SG_ 1445 SCAPwrDrMtnRRVirtCtlAval "Side Closure Access Power Door Motion Right Rear Virtual Control Available";
BA_ "SignalType" SG_ 1445 SCAPwrDrMtnLRVirtCtlAval "ENM";
BA_ "SignalLongName" SG_ 1445 SCAPwrDrMtnLRVirtCtlAval "Side Closure Access Power Door Motion Left Rear Virtual Control Available";
BA_ "SignalType" SG_ 521 AckCod "ENM";
BA_ "SignalLongName" SG_ 521 AckCod "Acknowledge Identification Vehicle Data Monitor : Acknowledge Code";
BA_ "SignalType" SG_ 521 AckFlrRsn "ENM";
BA_ "SignalLongName" SG_ 521 AckFlrRsn "Acknowledge Identification Vehicle Data Monitor : Acknowledge Failure Reason";
BA_ "SignalLongName" SG_ 521 AckIdDy "Acknowledge Identification Vehicle Data Monitor : Acknowledge Identification Day";
BA_ "SignalLongName" SG_ 521 AckIdHr "Acknowledge Identification Vehicle Data Monitor : Acknowledge Identification Hour";
BA_ "SignalLongName" SG_ 521 AckIdMin "Acknowledge Identification Vehicle Data Monitor : Acknowledge Identification Minute";
BA_ "SignalLongName" SG_ 521 AckIdMth "Acknowledge Identification Vehicle Data Monitor : Acknowledge Identification Month";
BA_ "SignalLongName" SG_ 521 AckIdSec "Acknowledge Identification Vehicle Data Monitor : Acknowledge Identification Second";
BA_ "SignalLongName" SG_ 521 AckIdYr "Acknowledge Identification Vehicle Data Monitor : Acknowledge Identification Year";
BA_ "SignalType" SG_ 1910 IntrAmbtColrCtlCstAvlFlg34 "ENM";
BA_ "SignalLongName" SG_ 1910 IntrAmbtColrCtlCstAvlFlg34 "Interior Ambient Color Control Customization Availability Flag 34";
BA_ "SignalType" SG_ 1910 IntrAmbtColrCtlCstAvlFlg33 "ENM";
BA_ "SignalLongName" SG_ 1910 IntrAmbtColrCtlCstAvlFlg33 "Interior Ambient Color Control Customization Availability Flag 33";
BA_ "SignalType" SG_ 1910 IntrAmbtColrCtlCstAvlFlg32 "ENM";
BA_ "SignalLongName" SG_ 1910 IntrAmbtColrCtlCstAvlFlg32 "Interior Ambient Color Control Customization Availability Flag 32";
BA_ "SignalType" SG_ 1910 IntrAmbtColrCtlCstAvlFlg42 "ENM";
BA_ "SignalLongName" SG_ 1910 IntrAmbtColrCtlCstAvlFlg42 "Interior Ambient Color Control Customization Availability Flag 42";
BA_ "SignalType" SG_ 1910 IntrAmbtColrCtlCstAvlFlg41 "ENM";
BA_ "SignalLongName" SG_ 1910 IntrAmbtColrCtlCstAvlFlg41 "Interior Ambient Color Control Customization Availability Flag 41";
BA_ "SignalType" SG_ 1910 IntrAmbtColrCtlCstAvlFlg40 "ENM";
BA_ "SignalLongName" SG_ 1910 IntrAmbtColrCtlCstAvlFlg40 "Interior Ambient Color Control Customization Availability Flag 40";
BA_ "SignalType" SG_ 1910 IntrAmbtColrCtlCstAvlFlg39 "ENM";
BA_ "SignalLongName" SG_ 1910 IntrAmbtColrCtlCstAvlFlg39 "Interior Ambient Color Control Customization Availability Flag 39";
BA_ "SignalType" SG_ 1910 IntrAmbtColrCtlCstAvlFlg38 "ENM";
BA_ "SignalLongName" SG_ 1910 IntrAmbtColrCtlCstAvlFlg38 "Interior Ambient Color Control Customization Availability Flag 38";
BA_ "SignalType" SG_ 1910 IntrAmbtColrCtlCstAvlFlg37 "ENM";
BA_ "SignalLongName" SG_ 1910 IntrAmbtColrCtlCstAvlFlg37 "Interior Ambient Color Control Customization Availability Flag 37";
BA_ "SignalType" SG_ 1910 IntrAmbtColrCtlCstAvlFlg36 "ENM";
BA_ "SignalLongName" SG_ 1910 IntrAmbtColrCtlCstAvlFlg36 "Interior Ambient Color Control Customization Availability Flag 36";
BA_ "SignalType" SG_ 1910 IntrAmbtColrCtlCstAvlFlg35 "ENM";
BA_ "SignalLongName" SG_ 1910 IntrAmbtColrCtlCstAvlFlg35 "Interior Ambient Color Control Customization Availability Flag 35";
BA_ "SignalType" SG_ 1910 IntrAmbtColrCtlCstAvlFlg50 "ENM";
BA_ "SignalLongName" SG_ 1910 IntrAmbtColrCtlCstAvlFlg50 "Interior Ambient Color Control Customization Availability Flag 50";
BA_ "SignalType" SG_ 1910 IntrAmbtColrCtlCstAvlFlg49 "ENM";
BA_ "SignalLongName" SG_ 1910 IntrAmbtColrCtlCstAvlFlg49 "Interior Ambient Color Control Customization Availability Flag 49";
BA_ "SignalType" SG_ 1910 IntrAmbtColrCtlCstAvlFlg48 "ENM";
BA_ "SignalLongName" SG_ 1910 IntrAmbtColrCtlCstAvlFlg48 "Interior Ambient Color Control Customization Availability Flag 48";
BA_ "SignalType" SG_ 1910 IntrAmbtColrCtlCstAvlFlg47 "ENM";
BA_ "SignalLongName" SG_ 1910 IntrAmbtColrCtlCstAvlFlg47 "Interior Ambient Color Control Customization Availability Flag 47";
BA_ "SignalType" SG_ 1910 IntrAmbtColrCtlCstAvlFlg46 "ENM";
BA_ "SignalLongName" SG_ 1910 IntrAmbtColrCtlCstAvlFlg46 "Interior Ambient Color Control Customization Availability Flag 46";
BA_ "SignalType" SG_ 1910 IntrAmbtColrCtlCstAvlFlg45 "ENM";
BA_ "SignalLongName" SG_ 1910 IntrAmbtColrCtlCstAvlFlg45 "Interior Ambient Color Control Customization Availability Flag 45";
BA_ "SignalType" SG_ 1910 IntrAmbtColrCtlCstAvlFlg44 "ENM";
BA_ "SignalLongName" SG_ 1910 IntrAmbtColrCtlCstAvlFlg44 "Interior Ambient Color Control Customization Availability Flag 44";
BA_ "SignalType" SG_ 1910 IntrAmbtColrCtlCstAvlFlg43 "ENM";
BA_ "SignalLongName" SG_ 1910 IntrAmbtColrCtlCstAvlFlg43 "Interior Ambient Color Control Customization Availability Flag 43";
BA_ "SignalType" SG_ 1910 IntrAmbtColrCtlCstAvlFlg58 "ENM";
BA_ "SignalLongName" SG_ 1910 IntrAmbtColrCtlCstAvlFlg58 "Interior Ambient Color Control Customization Availability Flag 58";
BA_ "SignalType" SG_ 1910 IntrAmbtColrCtlCstAvlFlg57 "ENM";
BA_ "SignalLongName" SG_ 1910 IntrAmbtColrCtlCstAvlFlg57 "Interior Ambient Color Control Customization Availability Flag 57";
BA_ "SignalType" SG_ 1910 IntrAmbtColrCtlCstAvlFlg56 "ENM";
BA_ "SignalLongName" SG_ 1910 IntrAmbtColrCtlCstAvlFlg56 "Interior Ambient Color Control Customization Availability Flag 56";
BA_ "SignalType" SG_ 1910 IntrAmbtColrCtlCstAvlFlg55 "ENM";
BA_ "SignalLongName" SG_ 1910 IntrAmbtColrCtlCstAvlFlg55 "Interior Ambient Color Control Customization Availability Flag 55";
BA_ "SignalType" SG_ 1910 IntrAmbtColrCtlCstAvlFlg54 "ENM";
BA_ "SignalLongName" SG_ 1910 IntrAmbtColrCtlCstAvlFlg54 "Interior Ambient Color Control Customization Availability Flag 54";
BA_ "SignalType" SG_ 1910 IntrAmbtColrCtlCstAvlFlg53 "ENM";
BA_ "SignalLongName" SG_ 1910 IntrAmbtColrCtlCstAvlFlg53 "Interior Ambient Color Control Customization Availability Flag 53";
BA_ "SignalType" SG_ 1910 IntrAmbtColrCtlCstAvlFlg52 "ENM";
BA_ "SignalLongName" SG_ 1910 IntrAmbtColrCtlCstAvlFlg52 "Interior Ambient Color Control Customization Availability Flag 52";
BA_ "SignalType" SG_ 1910 IntrAmbtColrCtlCstAvlFlg51 "ENM";
BA_ "SignalLongName" SG_ 1910 IntrAmbtColrCtlCstAvlFlg51 "Interior Ambient Color Control Customization Availability Flag 51";
BA_ "SignalType" SG_ 1910 IntrAmbtColrCtlCstAvlFlg66 "ENM";
BA_ "SignalLongName" SG_ 1910 IntrAmbtColrCtlCstAvlFlg66 "Interior Ambient Color Control Customization Availability Flag 66";
BA_ "SignalType" SG_ 1910 IntrAmbtColrCtlCstAvlFlg65 "ENM";
BA_ "SignalLongName" SG_ 1910 IntrAmbtColrCtlCstAvlFlg65 "Interior Ambient Color Control Customization Availability Flag 65";
BA_ "SignalType" SG_ 1910 IntrAmbtColrCtlCstAvlFlg64 "ENM";
BA_ "SignalLongName" SG_ 1910 IntrAmbtColrCtlCstAvlFlg64 "Interior Ambient Color Control Customization Availability Flag 64";
BA_ "SignalType" SG_ 1910 IntrAmbtColrCtlCstAvlFlg63 "ENM";
BA_ "SignalLongName" SG_ 1910 IntrAmbtColrCtlCstAvlFlg63 "Interior Ambient Color Control Customization Availability Flag 63";
BA_ "SignalType" SG_ 1910 IntrAmbtColrCtlCstAvlFlg62 "ENM";
BA_ "SignalLongName" SG_ 1910 IntrAmbtColrCtlCstAvlFlg62 "Interior Ambient Color Control Customization Availability Flag 62";
BA_ "SignalType" SG_ 1910 IntrAmbtColrCtlCstAvlFlg61 "ENM";
BA_ "SignalLongName" SG_ 1910 IntrAmbtColrCtlCstAvlFlg61 "Interior Ambient Color Control Customization Availability Flag 61";
BA_ "SignalType" SG_ 1910 IntrAmbtColrCtlCstAvlFlg60 "ENM";
BA_ "SignalLongName" SG_ 1910 IntrAmbtColrCtlCstAvlFlg60 "Interior Ambient Color Control Customization Availability Flag 60";
BA_ "SignalType" SG_ 1910 IntrAmbtColrCtlCstAvlFlg59 "ENM";
BA_ "SignalLongName" SG_ 1910 IntrAmbtColrCtlCstAvlFlg59 "Interior Ambient Color Control Customization Availability Flag 59";
BA_ "SignalType" SG_ 1910 IntrAmbtColrCtlCstAvlFlg74 "ENM";
BA_ "SignalLongName" SG_ 1910 IntrAmbtColrCtlCstAvlFlg74 "Interior Ambient Color Control Customization Availability Flag 74";
BA_ "SignalType" SG_ 1910 IntrAmbtColrCtlCstAvlFlg73 "ENM";
BA_ "SignalLongName" SG_ 1910 IntrAmbtColrCtlCstAvlFlg73 "Interior Ambient Color Control Customization Availability Flag 73";
BA_ "SignalType" SG_ 1910 IntrAmbtColrCtlCstAvlFlg72 "ENM";
BA_ "SignalLongName" SG_ 1910 IntrAmbtColrCtlCstAvlFlg72 "Interior Ambient Color Control Customization Availability Flag 72";
BA_ "SignalType" SG_ 1910 IntrAmbtColrCtlCstAvlFlg71 "ENM";
BA_ "SignalLongName" SG_ 1910 IntrAmbtColrCtlCstAvlFlg71 "Interior Ambient Color Control Customization Availability Flag 71";
BA_ "SignalType" SG_ 1910 IntrAmbtColrCtlCstAvlFlg70 "ENM";
BA_ "SignalLongName" SG_ 1910 IntrAmbtColrCtlCstAvlFlg70 "Interior Ambient Color Control Customization Availability Flag 70";
BA_ "SignalType" SG_ 1910 IntrAmbtColrCtlCstAvlFlg69 "ENM";
BA_ "SignalLongName" SG_ 1910 IntrAmbtColrCtlCstAvlFlg69 "Interior Ambient Color Control Customization Availability Flag 69";
BA_ "SignalType" SG_ 1910 IntrAmbtColrCtlCstAvlFlg68 "ENM";
BA_ "SignalLongName" SG_ 1910 IntrAmbtColrCtlCstAvlFlg68 "Interior Ambient Color Control Customization Availability Flag 68";
BA_ "SignalType" SG_ 1910 IntrAmbtColrCtlCstAvlFlg67 "ENM";
BA_ "SignalLongName" SG_ 1910 IntrAmbtColrCtlCstAvlFlg67 "Interior Ambient Color Control Customization Availability Flag 67";
BA_ "SignalType" SG_ 1910 IntrAmbtColrCtlCstAvlFlg82 "ENM";
BA_ "SignalLongName" SG_ 1910 IntrAmbtColrCtlCstAvlFlg82 "Interior Ambient Color Control Customization Availability Flag 82";
BA_ "SignalType" SG_ 1910 IntrAmbtColrCtlCstAvlFlg81 "ENM";
BA_ "SignalLongName" SG_ 1910 IntrAmbtColrCtlCstAvlFlg81 "Interior Ambient Color Control Customization Availability Flag 81";
BA_ "SignalType" SG_ 1910 IntrAmbtColrCtlCstAvlFlg80 "ENM";
BA_ "SignalLongName" SG_ 1910 IntrAmbtColrCtlCstAvlFlg80 "Interior Ambient Color Control Customization Availability Flag 80";
BA_ "SignalType" SG_ 1910 IntrAmbtColrCtlCstAvlFlg79 "ENM";
BA_ "SignalLongName" SG_ 1910 IntrAmbtColrCtlCstAvlFlg79 "Interior Ambient Color Control Customization Availability Flag 79";
BA_ "SignalType" SG_ 1910 IntrAmbtColrCtlCstAvlFlg78 "ENM";
BA_ "SignalLongName" SG_ 1910 IntrAmbtColrCtlCstAvlFlg78 "Interior Ambient Color Control Customization Availability Flag 78";
BA_ "SignalType" SG_ 1910 IntrAmbtColrCtlCstAvlFlg77 "ENM";
BA_ "SignalLongName" SG_ 1910 IntrAmbtColrCtlCstAvlFlg77 "Interior Ambient Color Control Customization Availability Flag 77";
BA_ "SignalType" SG_ 1910 IntrAmbtColrCtlCstAvlFlg76 "ENM";
BA_ "SignalLongName" SG_ 1910 IntrAmbtColrCtlCstAvlFlg76 "Interior Ambient Color Control Customization Availability Flag 76";
BA_ "SignalType" SG_ 1910 IntrAmbtColrCtlCstAvlFlg75 "ENM";
BA_ "SignalLongName" SG_ 1910 IntrAmbtColrCtlCstAvlFlg75 "Interior Ambient Color Control Customization Availability Flag 75";
BA_ "SignalType" SG_ 1912 IntrAmbtColrCtlCstAvlFlg107 "ENM";
BA_ "SignalLongName" SG_ 1912 IntrAmbtColrCtlCstAvlFlg107 "Interior Ambient Color Control Customization Availability Flag 107";
BA_ "SignalType" SG_ 1912 IntrAmbtColrCtlCstAvlFlg106 "ENM";
BA_ "SignalLongName" SG_ 1912 IntrAmbtColrCtlCstAvlFlg106 "Interior Ambient Color Control Customization Availability Flag 106";
BA_ "SignalType" SG_ 1912 IntrAmbtColrCtlCstAvlFlg105 "ENM";
BA_ "SignalLongName" SG_ 1912 IntrAmbtColrCtlCstAvlFlg105 "Interior Ambient Color Control Customization Availability Flag 105";
BA_ "SignalType" SG_ 1912 IntrAmbtColrCtlCstAvlFlg104 "ENM";
BA_ "SignalLongName" SG_ 1912 IntrAmbtColrCtlCstAvlFlg104 "Interior Ambient Color Control Customization Availability Flag 104";
BA_ "SignalType" SG_ 1912 IntrAmbtColrCtlCstAvlFlg103 "ENM";
BA_ "SignalLongName" SG_ 1912 IntrAmbtColrCtlCstAvlFlg103 "Interior Ambient Color Control Customization Availability Flag 103";
BA_ "SignalType" SG_ 1912 IntrAmbtColrCtlCstAvlFlg102 "ENM";
BA_ "SignalLongName" SG_ 1912 IntrAmbtColrCtlCstAvlFlg102 "Interior Ambient Color Control Customization Availability Flag 102";
BA_ "SignalType" SG_ 1912 IntrAmbtColrCtlCstAvlFlg101 "ENM";
BA_ "SignalLongName" SG_ 1912 IntrAmbtColrCtlCstAvlFlg101 "Interior Ambient Color Control Customization Availability Flag 101";
BA_ "SignalType" SG_ 1912 IntrAmbtColrCtlCstAvlFlg100 "ENM";
BA_ "SignalLongName" SG_ 1912 IntrAmbtColrCtlCstAvlFlg100 "Interior Ambient Color Control Customization Availability Flag 100";
BA_ "SignalType" SG_ 1912 IntrAmbtColrCtlCstAvlFlg115 "ENM";
BA_ "SignalLongName" SG_ 1912 IntrAmbtColrCtlCstAvlFlg115 "Interior Ambient Color Control Customization Availability Flag 115";
BA_ "SignalType" SG_ 1912 IntrAmbtColrCtlCstAvlFlg114 "ENM";
BA_ "SignalLongName" SG_ 1912 IntrAmbtColrCtlCstAvlFlg114 "Interior Ambient Color Control Customization Availability Flag 114";
BA_ "SignalType" SG_ 1912 IntrAmbtColrCtlCstAvlFlg113 "ENM";
BA_ "SignalLongName" SG_ 1912 IntrAmbtColrCtlCstAvlFlg113 "Interior Ambient Color Control Customization Availability Flag 113";
BA_ "SignalType" SG_ 1912 IntrAmbtColrCtlCstAvlFlg112 "ENM";
BA_ "SignalLongName" SG_ 1912 IntrAmbtColrCtlCstAvlFlg112 "Interior Ambient Color Control Customization Availability Flag 112";
BA_ "SignalType" SG_ 1912 IntrAmbtColrCtlCstAvlFlg111 "ENM";
BA_ "SignalLongName" SG_ 1912 IntrAmbtColrCtlCstAvlFlg111 "Interior Ambient Color Control Customization Availability Flag 111";
BA_ "SignalType" SG_ 1912 IntrAmbtColrCtlCstAvlFlg110 "ENM";
BA_ "SignalLongName" SG_ 1912 IntrAmbtColrCtlCstAvlFlg110 "Interior Ambient Color Control Customization Availability Flag 110";
BA_ "SignalType" SG_ 1912 IntrAmbtColrCtlCstAvlFlg109 "ENM";
BA_ "SignalLongName" SG_ 1912 IntrAmbtColrCtlCstAvlFlg109 "Interior Ambient Color Control Customization Availability Flag 109";
BA_ "SignalType" SG_ 1912 IntrAmbtColrCtlCstAvlFlg108 "ENM";
BA_ "SignalLongName" SG_ 1912 IntrAmbtColrCtlCstAvlFlg108 "Interior Ambient Color Control Customization Availability Flag 108";
BA_ "SignalType" SG_ 1912 IntrAmbtColrCtlCstAvlFlg123 "ENM";
BA_ "SignalLongName" SG_ 1912 IntrAmbtColrCtlCstAvlFlg123 "Interior Ambient Color Control Customization Availability Flag 123";
BA_ "SignalType" SG_ 1912 IntrAmbtColrCtlCstAvlFlg122 "ENM";
BA_ "SignalLongName" SG_ 1912 IntrAmbtColrCtlCstAvlFlg122 "Interior Ambient Color Control Customization Availability Flag 122";
BA_ "SignalType" SG_ 1912 IntrAmbtColrCtlCstAvlFlg121 "ENM";
BA_ "SignalLongName" SG_ 1912 IntrAmbtColrCtlCstAvlFlg121 "Interior Ambient Color Control Customization Availability Flag 121";
BA_ "SignalType" SG_ 1912 IntrAmbtColrCtlCstAvlFlg120 "ENM";
BA_ "SignalLongName" SG_ 1912 IntrAmbtColrCtlCstAvlFlg120 "Interior Ambient Color Control Customization Availability Flag 120";
BA_ "SignalType" SG_ 1912 IntrAmbtColrCtlCstAvlFlg119 "ENM";
BA_ "SignalLongName" SG_ 1912 IntrAmbtColrCtlCstAvlFlg119 "Interior Ambient Color Control Customization Availability Flag 119";
BA_ "SignalType" SG_ 1912 IntrAmbtColrCtlCstAvlFlg118 "ENM";
BA_ "SignalLongName" SG_ 1912 IntrAmbtColrCtlCstAvlFlg118 "Interior Ambient Color Control Customization Availability Flag 118";
BA_ "SignalType" SG_ 1912 IntrAmbtColrCtlCstAvlFlg117 "ENM";
BA_ "SignalLongName" SG_ 1912 IntrAmbtColrCtlCstAvlFlg117 "Interior Ambient Color Control Customization Availability Flag 117";
BA_ "SignalType" SG_ 1912 IntrAmbtColrCtlCstAvlFlg116 "ENM";
BA_ "SignalLongName" SG_ 1912 IntrAmbtColrCtlCstAvlFlg116 "Interior Ambient Color Control Customization Availability Flag 116";
BA_ "SignalType" SG_ 1912 IntrAmbtColrCtlCstAvlFlg86 "ENM";
BA_ "SignalLongName" SG_ 1912 IntrAmbtColrCtlCstAvlFlg86 "Interior Ambient Color Control Customization Availability Flag 86";
BA_ "SignalType" SG_ 1912 IntrAmbtColrCtlCstAvlFlg85 "ENM";
BA_ "SignalLongName" SG_ 1912 IntrAmbtColrCtlCstAvlFlg85 "Interior Ambient Color Control Customization Availability Flag 85";
BA_ "SignalType" SG_ 1912 IntrAmbtColrCtlCstAvlFlg84 "ENM";
BA_ "SignalLongName" SG_ 1912 IntrAmbtColrCtlCstAvlFlg84 "Interior Ambient Color Control Customization Availability Flag 84";
BA_ "SignalType" SG_ 1912 IntrAmbtColrCtlCstAvlFlg83 "ENM";
BA_ "SignalLongName" SG_ 1912 IntrAmbtColrCtlCstAvlFlg83 "Interior Ambient Color Control Customization Availability Flag 83";
BA_ "SignalType" SG_ 1912 IntrAmbtColrCtlCstAvlFlg127 "ENM";
BA_ "SignalLongName" SG_ 1912 IntrAmbtColrCtlCstAvlFlg127 "Interior Ambient Color Control Customization Availability Flag 127";
BA_ "SignalType" SG_ 1912 IntrAmbtColrCtlCstAvlFlg126 "ENM";
BA_ "SignalLongName" SG_ 1912 IntrAmbtColrCtlCstAvlFlg126 "Interior Ambient Color Control Customization Availability Flag 126";
BA_ "SignalType" SG_ 1912 IntrAmbtColrCtlCstAvlFlg125 "ENM";
BA_ "SignalLongName" SG_ 1912 IntrAmbtColrCtlCstAvlFlg125 "Interior Ambient Color Control Customization Availability Flag 125";
BA_ "SignalType" SG_ 1912 IntrAmbtColrCtlCstAvlFlg124 "ENM";
BA_ "SignalLongName" SG_ 1912 IntrAmbtColrCtlCstAvlFlg124 "Interior Ambient Color Control Customization Availability Flag 124";
BA_ "SignalType" SG_ 1912 IntrAmbtColrCtlCstAvlFlg94 "ENM";
BA_ "SignalLongName" SG_ 1912 IntrAmbtColrCtlCstAvlFlg94 "Interior Ambient Color Control Customization Availability Flag 94";
BA_ "SignalType" SG_ 1912 IntrAmbtColrCtlCstAvlFlg93 "ENM";
BA_ "SignalLongName" SG_ 1912 IntrAmbtColrCtlCstAvlFlg93 "Interior Ambient Color Control Customization Availability Flag 93";
BA_ "SignalType" SG_ 1912 IntrAmbtColrCtlCstAvlFlg92 "ENM";
BA_ "SignalLongName" SG_ 1912 IntrAmbtColrCtlCstAvlFlg92 "Interior Ambient Color Control Customization Availability Flag 92";
BA_ "SignalType" SG_ 1912 IntrAmbtColrCtlCstAvlFlg91 "ENM";
BA_ "SignalLongName" SG_ 1912 IntrAmbtColrCtlCstAvlFlg91 "Interior Ambient Color Control Customization Availability Flag 91";
BA_ "SignalType" SG_ 1912 IntrAmbtColrCtlCstAvlFlg90 "ENM";
BA_ "SignalLongName" SG_ 1912 IntrAmbtColrCtlCstAvlFlg90 "Interior Ambient Color Control Customization Availability Flag 90";
BA_ "SignalType" SG_ 1912 IntrAmbtColrCtlCstAvlFlg89 "ENM";
BA_ "SignalLongName" SG_ 1912 IntrAmbtColrCtlCstAvlFlg89 "Interior Ambient Color Control Customization Availability Flag 89";
BA_ "SignalType" SG_ 1912 IntrAmbtColrCtlCstAvlFlg88 "ENM";
BA_ "SignalLongName" SG_ 1912 IntrAmbtColrCtlCstAvlFlg88 "Interior Ambient Color Control Customization Availability Flag 88";
BA_ "SignalType" SG_ 1912 IntrAmbtColrCtlCstAvlFlg87 "ENM";
BA_ "SignalLongName" SG_ 1912 IntrAmbtColrCtlCstAvlFlg87 "Interior Ambient Color Control Customization Availability Flag 87";
BA_ "SignalType" SG_ 1912 ElvtdIdlCstSetAvlFlg2 "ENM";
BA_ "SignalLongName" SG_ 1912 ElvtdIdlCstSetAvlFlg2 "Elevated Idle Customization Setting Availability Flag 2";
BA_ "SignalType" SG_ 1912 ElvtdIdlCstSetAvlFlg1 "ENM";
BA_ "SignalLongName" SG_ 1912 ElvtdIdlCstSetAvlFlg1 "Elevated Idle Customization Setting Availability Flag 1";
BA_ "SignalType" SG_ 1912 ElvtdIdlCstSetAval "ENM";
BA_ "SignalLongName" SG_ 1912 ElvtdIdlCstSetAval "Elevated Idle Customization Setting Available";
BA_ "SignalType" SG_ 1912 IntrAmbtColrCtlCstAvlFlg99 "ENM";
BA_ "SignalLongName" SG_ 1912 IntrAmbtColrCtlCstAvlFlg99 "Interior Ambient Color Control Customization Availability Flag 99";
BA_ "SignalType" SG_ 1912 IntrAmbtColrCtlCstAvlFlg98 "ENM";
BA_ "SignalLongName" SG_ 1912 IntrAmbtColrCtlCstAvlFlg98 "Interior Ambient Color Control Customization Availability Flag 98";
BA_ "SignalType" SG_ 1912 IntrAmbtColrCtlCstAvlFlg97 "ENM";
BA_ "SignalLongName" SG_ 1912 IntrAmbtColrCtlCstAvlFlg97 "Interior Ambient Color Control Customization Availability Flag 97";
BA_ "SignalType" SG_ 1912 IntrAmbtColrCtlCstAvlFlg96 "ENM";
BA_ "SignalLongName" SG_ 1912 IntrAmbtColrCtlCstAvlFlg96 "Interior Ambient Color Control Customization Availability Flag 96";
BA_ "SignalType" SG_ 1912 IntrAmbtColrCtlCstAvlFlg95 "ENM";
BA_ "SignalLongName" SG_ 1912 IntrAmbtColrCtlCstAvlFlg95 "Interior Ambient Color Control Customization Availability Flag 95";
BA_ "SignalType" SG_ 1912 DMSDrwDrvrCstAvlFlg3 "ENM";
BA_ "SignalLongName" SG_ 1912 DMSDrwDrvrCstAvlFlg3 "Driver Monitoring System Drowsy Driver Customization Availability Flag3";
BA_ "SignalType" SG_ 1912 DMSDrwDrvrCstAvlFlg2 "ENM";
BA_ "SignalLongName" SG_ 1912 DMSDrwDrvrCstAvlFlg2 "Driver Monitoring System Drowsy Driver Customization Availability Flag2";
BA_ "SignalType" SG_ 1912 DMSDrwDrvrCstAvlFlg1 "ENM";
BA_ "SignalLongName" SG_ 1912 DMSDrwDrvrCstAvlFlg1 "Driver Monitoring System Drowsy Driver Customization Availability Flag1";
BA_ "SignalType" SG_ 1912 ElvtdIdlCstSetAvlFlg7 "ENM";
BA_ "SignalLongName" SG_ 1912 ElvtdIdlCstSetAvlFlg7 "Elevated Idle Customization Setting Availability Flag 7";
BA_ "SignalType" SG_ 1912 ElvtdIdlCstSetAvlFlg6 "ENM";
BA_ "SignalLongName" SG_ 1912 ElvtdIdlCstSetAvlFlg6 "Elevated Idle Customization Setting Availability Flag 6";
BA_ "SignalType" SG_ 1912 ElvtdIdlCstSetAvlFlg5 "ENM";
BA_ "SignalLongName" SG_ 1912 ElvtdIdlCstSetAvlFlg5 "Elevated Idle Customization Setting Availability Flag 5";
BA_ "SignalType" SG_ 1912 ElvtdIdlCstSetAvlFlg4 "ENM";
BA_ "SignalLongName" SG_ 1912 ElvtdIdlCstSetAvlFlg4 "Elevated Idle Customization Setting Availability Flag 4";
BA_ "SignalType" SG_ 1912 ElvtdIdlCstSetAvlFlg3 "ENM";
BA_ "SignalLongName" SG_ 1912 ElvtdIdlCstSetAvlFlg3 "Elevated Idle Customization Setting Availability Flag 3";
BA_ "SignalType" SG_ 1912 VehSpdAcurLvl "ENM";
BA_ "SignalLongName" SG_ 1912 VehSpdAcurLvl "Vehicle Speed Accuracy Level";
BA_ "SignalType" SG_ 1912 DMSDrwDrvrCstSetAval "ENM";
BA_ "SignalLongName" SG_ 1912 DMSDrwDrvrCstSetAval "Driver Monitoring System Drowsy Driver Customization Setting Available";
BA_ "SignalType" SG_ 1912 DMSDrwDrvrCstAvlFlg7 "ENM";
BA_ "SignalLongName" SG_ 1912 DMSDrwDrvrCstAvlFlg7 "Driver Monitoring System Drowsy Driver Customization Availability Flag7";
BA_ "SignalType" SG_ 1912 DMSDrwDrvrCstAvlFlg6 "ENM";
BA_ "SignalLongName" SG_ 1912 DMSDrwDrvrCstAvlFlg6 "Driver Monitoring System Drowsy Driver Customization Availability Flag6";
BA_ "SignalType" SG_ 1912 DMSDrwDrvrCstAvlFlg5 "ENM";
BA_ "SignalLongName" SG_ 1912 DMSDrwDrvrCstAvlFlg5 "Driver Monitoring System Drowsy Driver Customization Availability Flag5";
BA_ "SignalType" SG_ 1912 DMSDrwDrvrCstAvlFlg4 "ENM";
BA_ "SignalLongName" SG_ 1912 DMSDrwDrvrCstAvlFlg4 "Driver Monitoring System Drowsy Driver Customization Availability Flag4";
BA_ "SignalType" SG_ 1915 ExtAudSOH "ENM";
BA_ "SignalLongName" SG_ 1915 ExtAudSOH "Exterior Audio State of Health";
BA_ "SignalType" SG_ 1915 ExtDispSOH "ENM";
BA_ "SignalLongName" SG_ 1915 ExtDispSOH "Exterior Display State of Health";
BA_ "SignalType" SG_ 1915 EmrgCallAudSOH "ENM";
BA_ "SignalLongName" SG_ 1915 EmrgCallAudSOH "Emergency Call Audio State of Health";
BA_ "SignalType" SG_ 1915 CbnAudSOH "ENM";
BA_ "SignalLongName" SG_ 1915 CbnAudSOH "Cabin Audio State of Health";
BA_ "SignalLongName" SG_ 1916 AmpSOHAEIntrnlStat "Amplifier State Of Health Audio Equalization Information : Amplifier State Of Health Audio Equalization Internal State";
BA_ "SignalLongName" SG_ 1916 AmpSOHAEMtxSnkBssCurrVal "Amplifier State Of Health Audio Equalization Information : Amplifier State Of Health Audio Equalization Mutex Sink Bass Current Value";
BA_ "SignalLongName" SG_ 1916 AmpSOHAEMtxSnkBalCurrVal "Amplifier State Of Health Audio Equalization Information : Amplifier State Of Health Audio Equalization Mutex Sink Balance Current Value";
BA_ "SignalLongName" SG_ 1916 AmpSOHAEMtxSnkFdCurrVal "Amplifier State Of Health Audio Equalization Information : Amplifier State Of Health Audio Equalization Mutex Sink Fade Current Value";
BA_ "SignalLongName" SG_ 1916 AmpSOHAEMtxSnkMdrngCurrVal "Amplifier State Of Health Audio Equalization Information : Amplifier State Of Health Audio Equalization Mutex Sink Midrange Current Value";
BA_ "SignalLongName" SG_ 1916 AmpSOHAESrrndLvlCurrVal "Amplifier State Of Health Audio Equalization Information : Amplifier State Of Health Audio Equalization Surround Level Current Value";
BA_ "SignalLongName" SG_ 1916 AmpSOHAEMtxSnkTrblCurrVal "Amplifier State Of Health Audio Equalization Information : Amplifier State Of Health Audio Equalization Mutex Sink Treble Current Value";
BA_ "SignalType" SG_ 1916 AmpSOHAEDSPModeCurrStat "ENM";
BA_ "SignalLongName" SG_ 1916 AmpSOHAEDSPModeCurrStat "Amplifier State Of Health Audio Equalization Information : Amplifier State Of Health Audio Equalization DSP Mode Current State";
BA_ "SignalType" SG_ 1916 AmpSOHAEVehNoisCmpnAtv "ENM";
BA_ "SignalLongName" SG_ 1916 AmpSOHAEVehNoisCmpnAtv "Amplifier State Of Health Audio Equalization Information : Amplifier State Of Health Audio Equalization Vehicle Noise Compensation Active";
BA_ "SignalLongName" SG_ 735 InfoPsngSysLng "Infotainment Positioning System Information : Infotainment Positioning System Longitude";
BA_ "SignalLongName" SG_ 735 InfoPsngSysLat "Infotainment Positioning System Information : Infotainment Positioning System Latitude";
BA_ "SignalType" SG_ 735 InfoPsngSysLng_Inv "ENM";
BA_ "SignalLongName" SG_ 735 InfoPsngSysLng_Inv "Infotainment Positioning System Information : Infotainment Positioning System Longitude Invalid";
BA_ "SignalType" SG_ 735 InfoPsngSysLat_Inv "ENM";
BA_ "SignalLongName" SG_ 735 InfoPsngSysLat_Inv "Infotainment Positioning System Information : Infotainment Positioning System Latitude Invalid";
BA_ "SignalType" SG_ 1134 StHtdCushLvlLFSet "ENM";
BA_ "SignalLongName" SG_ 1134 StHtdCushLvlLFSet "Seat Heated Vented or Cooled Left Front Information : Seat Heated Cushion Level Left Front Setting";
BA_ "SignalType" SG_ 1134 StHtdBkLvlLFSet "ENM";
BA_ "SignalLongName" SG_ 1134 StHtdBkLvlLFSet "Seat Heated Vented or Cooled Left Front Information : Seat Heated Back Level Left Front Setting";
BA_ "SignalType" SG_ 1134 StHtdCushLvlLRSet "ENM";
BA_ "SignalLongName" SG_ 1134 StHtdCushLvlLRSet "Seat Heated Vented or Cooled Left Rear Information : Seat Heated Cushion Level Left Rear Setting";
BA_ "SignalType" SG_ 1134 StHtdBkLvlLRSet "ENM";
BA_ "SignalLongName" SG_ 1134 StHtdBkLvlLRSet "Seat Heated Vented or Cooled Left Rear Information : Seat Heated Back Level Left Rear Setting";
BA_ "SignalType" SG_ 1134 StVntdCoolCushLvlLFSet "ENM";
BA_ "SignalLongName" SG_ 1134 StVntdCoolCushLvlLFSet "Seat Heated Vented or Cooled Left Front Information : Seat Vented or Cooled Cushion Level Left Front Setting";
BA_ "SignalType" SG_ 1134 StVntdCoolBkLvlLFSet "ENM";
BA_ "SignalLongName" SG_ 1134 StVntdCoolBkLvlLFSet "Seat Heated Vented or Cooled Left Front Information : Seat Vented or Cooled Back Level Left Front Setting";
BA_ "SignalType" SG_ 1134 StHtdCushLvlRFSet "ENM";
BA_ "SignalLongName" SG_ 1134 StHtdCushLvlRFSet "Seat Heated Vented or Cooled Right Front Information : Seat Heated Cushion Level Right Front Setting";
BA_ "SignalType" SG_ 1134 StHtdBkLvlRFSet "ENM";
BA_ "SignalLongName" SG_ 1134 StHtdBkLvlRFSet "Seat Heated Vented or Cooled Right Front Information : Seat Heated Back Level Right Front Setting";
BA_ "SignalType" SG_ 1134 StVntdCoolCushLvlLRSet "ENM";
BA_ "SignalLongName" SG_ 1134 StVntdCoolCushLvlLRSet "Seat Heated Vented or Cooled Left Rear Information : Seat Vented or Cooled Cushion Level Left Rear Setting";
BA_ "SignalType" SG_ 1134 StVntdCoolBkLvlLRSet "ENM";
BA_ "SignalLongName" SG_ 1134 StVntdCoolBkLvlLRSet "Seat Heated Vented or Cooled Left Rear Information : Seat Vented or Cooled Back Level Left Rear Setting";
BA_ "SignalType" SG_ 1134 RrDrOpnCmfRclCstSetVal "ENM";
BA_ "SignalLongName" SG_ 1134 RrDrOpnCmfRclCstSetVal "Rear Door Open Comfort Recall Customization Setting Value";
BA_ "SignalType" SG_ 1134 StVntdCoolCushLvlRFSet "ENM";
BA_ "SignalLongName" SG_ 1134 StVntdCoolCushLvlRFSet "Seat Heated Vented or Cooled Right Front Information : Seat Vented or Cooled Cushion Level Right Front Setting";
BA_ "SignalType" SG_ 1134 StVntdCoolBkLvlRFSet "ENM";
BA_ "SignalLongName" SG_ 1134 StVntdCoolBkLvlRFSet "Seat Heated Vented or Cooled Right Front Information : Seat Vented or Cooled Back Level Right Front Setting";
BA_ "SignalType" SG_ 1933 StBkHrztlLRVirtCtlAllwd "ENM";
BA_ "SignalLongName" SG_ 1933 StBkHrztlLRVirtCtlAllwd "Seat Left Rear Virtual Control Allowed Information : Seat Back Horizontal Left Rear Virtual Control Allowed";
BA_ "SignalType" SG_ 1933 StCushSdBolsLRVirtCtlAllwd "ENM";
BA_ "SignalLongName" SG_ 1933 StCushSdBolsLRVirtCtlAllwd "Seat Left Rear Virtual Control Allowed Information : Seat Cushion Side Bolster Left Rear Virtual Control Allowed";
BA_ "SignalType" SG_ 1933 StCushRrVertLRVirtCtlAllwd "ENM";
BA_ "SignalLongName" SG_ 1933 StCushRrVertLRVirtCtlAllwd "Seat Left Rear Virtual Control Allowed Information : Seat Cushion Rear Vertical Left Rear Virtual Control Allowed";
BA_ "SignalType" SG_ 1933 StCushLgthHrztlLRVirtCtlAllwd "ENM";
BA_ "SignalLongName" SG_ 1933 StCushLgthHrztlLRVirtCtlAllwd "Seat Left Rear Virtual Control Allowed Information : Seat Cushion Length Horizontal Left Rear Virtual Control Allowed";
BA_ "SignalType" SG_ 1933 StCushHrztlLRVirtCtlAllwd "ENM";
BA_ "SignalLongName" SG_ 1933 StCushHrztlLRVirtCtlAllwd "Seat Left Rear Virtual Control Allowed Information : Seat Cushion Horizontal Left Rear Virtual Control Allowed";
BA_ "SignalType" SG_ 1933 StCushFrtVertLRVirtCtlAllwd "ENM";
BA_ "SignalLongName" SG_ 1933 StCushFrtVertLRVirtCtlAllwd "Seat Left Rear Virtual Control Allowed Information : Seat Cushion Front Vertical Left Rear Virtual Control Allowed";
BA_ "SignalType" SG_ 1933 StBkSdBolsLRVirtCtlAllwd "ENM";
BA_ "SignalLongName" SG_ 1933 StBkSdBolsLRVirtCtlAllwd "Seat Left Rear Virtual Control Allowed Information : Seat Back Side Bolster Left Rear Virtual Control Allowed";
BA_ "SignalType" SG_ 1933 StBkLumbVertLRVirtCtlAllwd "ENM";
BA_ "SignalLongName" SG_ 1933 StBkLumbVertLRVirtCtlAllwd "Seat Left Rear Virtual Control Allowed Information : Seat Back Lumbar Vertical Left Rear Virtual Control Allowed";
BA_ "SignalType" SG_ 1933 StBkLumbHrztlLRVirtCtlAllwd "ENM";
BA_ "SignalLongName" SG_ 1933 StBkLumbHrztlLRVirtCtlAllwd "Seat Left Rear Virtual Control Allowed Information : Seat Back Lumbar Horizontal Left Rear Virtual Control Allowed";
BA_ "SignalType" SG_ 1933 StUpprShldrHrztlLRVirtCtlAllwd "ENM";
BA_ "SignalLongName" SG_ 1933 StUpprShldrHrztlLRVirtCtlAllwd "Seat Left Rear Virtual Control Allowed Information : Seat Upper Shoulder Horizontal Left Rear Virtual Control Allowed";
BA_ "SignalType" SG_ 1933 StMasgLRVirtCtlAllwd "ENM";
BA_ "SignalLongName" SG_ 1933 StMasgLRVirtCtlAllwd "Seat Left Rear Virtual Control Allowed Information : Seat Massage Left Rear Virtual Control Allowed";
BA_ "SignalType" SG_ 1933 StHdrstVertLRVirtCtlAllwd "ENM";
BA_ "SignalLongName" SG_ 1933 StHdrstVertLRVirtCtlAllwd "Seat Left Rear Virtual Control Allowed Information : Seat Headrest Vertical Left Rear Virtual Control Allowed";
BA_ "SignalType" SG_ 1933 StHdrstHrztlLRVirtCtlAllwd "ENM";
BA_ "SignalLongName" SG_ 1933 StHdrstHrztlLRVirtCtlAllwd "Seat Left Rear Virtual Control Allowed Information : Seat Headrest Horizontal Left Rear Virtual Control Allowed";
BA_ "SignalType" SG_ 1933 StMasgIntstyLRLstKnwnSet "ENM";
BA_ "SignalLongName" SG_ 1933 StMasgIntstyLRLstKnwnSet "Seat Left Rear Massage Setting Information : Seat Massage Intensity Left Rear Last Known Setting";
BA_ "SignalType" SG_ 1933 StMasgTypLRLstKnwnSet "ENM";
BA_ "SignalLongName" SG_ 1933 StMasgTypLRLstKnwnSet "Seat Left Rear Massage Setting Information : Seat Massage Type Left Rear Last Known Setting";
BA_ "SignalType" SG_ 1131 SuprRmtPrkFcsStsVCU "ENM";
BA_ "SignalLongName" SG_ 1131 SuprRmtPrkFcsStsVCU "Supervised Remote Parking Focus Status VCU";
BA_ "SignalLongName" SG_ 1133 HVACICROtltFrtRtInbdVrtPs "Serial Data 213 : HVAC Infotainment Controls Request Outlet Front Right Inboard Vertical Position";
BA_ "SignalLongName" SG_ 1133 HVACICROtltFrtRtInbdHrztlPs "Serial Data 213 : HVAC Infotainment Controls Request Outlet Front Right Inboard Horizontal Position";
BA_ "SignalLongName" SG_ 1133 HVACICROtltFrtRtOtbdHrztlPs "Serial Data 213 : HVAC Infotainment Controls Request Outlet Front Right Outboard Horizontal Position";
BA_ "SignalLongName" SG_ 1133 HVACICROtltFrtRtOtbdVrtPs "Serial Data 213 : HVAC Infotainment Controls Request Outlet Front Right Outboard Vertical Position";
BA_ "SignalType" SG_ 1133 HVACICROtltFrtRtOtbdArflQnty "ENM";
BA_ "SignalLongName" SG_ 1133 HVACICROtltFrtRtOtbdArflQnty "Serial Data 213 : HVAC Infotainment Controls Request Outlet Front Right Outboard Airflow Quantity";
BA_ "SignalType" SG_ 1133 HVACICROtltFrtRtInbdArflQnty "ENM";
BA_ "SignalLongName" SG_ 1133 HVACICROtltFrtRtInbdArflQnty "Serial Data 213 : HVAC Infotainment Controls Request Outlet Front Right Inboard Airflow Quantity";
BA_ "SignalLongName" SG_ 1133 SD213_ARC "Serial Data 213 : Alive Rolling Count";
BA_ "SignalType" SG_ 1133 HVACICROtltFrtRtStat "ENM";
BA_ "SignalLongName" SG_ 1133 HVACICROtltFrtRtStat "Serial Data 213 : HVAC Infotainment Controls Request Outlet Front Right State";
BA_ "SignalType" SG_ 1133 HVACICROscMdFrtRtSet "ENM";
BA_ "SignalLongName" SG_ 1133 HVACICROscMdFrtRtSet "Serial Data 213 : HVAC Infotainment Controls Request Oscillation Mode Front Right Setting";
BA_ "SignalLongName" SG_ 1133 HVACICROtltRrLtInbdHrztlPs "Serial Data 214 : HVAC Infotainment Controls Request Outlet Rear Left Inboard Horizontal Position";
BA_ "SignalType" SG_ 1133 HVACICRHVACPwrFrtRtChg "ENM";
BA_ "SignalLongName" SG_ 1133 HVACICRHVACPwrFrtRtChg "Serial Data 213 : HVAC Infotainment Controls Request HVAC Power Front Right Change";
BA_ "SignalType" SG_ 1133 HVACICRCkMdOn "ENM";
BA_ "SignalLongName" SG_ 1133 HVACICRCkMdOn "Serial Data 213 : HVAC Infotainment Controls Request Cake Mode On";
BA_ "SignalLongName" SG_ 1133 HVACICROtltRrLtInbdVrtPs "Serial Data 214 : HVAC Infotainment Controls Request Outlet Rear Left Inboard Vertical Position";
BA_ "SignalType" SG_ 1133 HVACICRHVACPwrRrLtChg "ENM";
BA_ "SignalLongName" SG_ 1133 HVACICRHVACPwrRrLtChg "Serial Data 214 : HVAC Infotainment Controls Request HVAC Power Rear Left Change";
BA_ "SignalLongName" SG_ 1133 SD214_ARC "Serial Data 214 : Alive Rolling Count";
BA_ "SignalType" SG_ 1133 HVACICROtltRrLtStat "ENM";
BA_ "SignalLongName" SG_ 1133 HVACICROtltRrLtStat "Serial Data 214 : HVAC Infotainment Controls Request Outlet Rear Left State";
BA_ "SignalType" SG_ 1133 HVACICROscMdRrLtSet "ENM";
BA_ "SignalLongName" SG_ 1133 HVACICROscMdRrLtSet "Serial Data 214 : HVAC Infotainment Controls Request Oscillation Mode Rear Left Setting";
BA_ "SignalLongName" SG_ 1934 HVACICROtltFrtLtInbdVrtPs "Serial Data 212 : HVAC Infotainment Controls Request Outlet Front Left Inboard Vertical Position";
BA_ "SignalLongName" SG_ 1934 HVACICROtltFrtLtInbdHrztlPs "Serial Data 212 : HVAC Infotainment Controls Request Outlet Front Left Inboard Horizontal Position";
BA_ "SignalLongName" SG_ 1934 HVACICROtltFrtLtOtbdHrztlPs "Serial Data 212 : HVAC Infotainment Controls Request Outlet Front Left Outboard Horizontal Position";
BA_ "SignalLongName" SG_ 1934 HVACICROtltFrtLtOtbdVrtPs "Serial Data 212 : HVAC Infotainment Controls Request Outlet Front Left Outboard Vertical Position";
BA_ "SignalType" SG_ 1934 HVACICROtltFrtLtOtbdArflQnty "ENM";
BA_ "SignalLongName" SG_ 1934 HVACICROtltFrtLtOtbdArflQnty "Serial Data 212 : HVAC Infotainment Controls Request Outlet Front Left Outboard Airflow Quantity";
BA_ "SignalType" SG_ 1934 HVACICROtltFrtLtInbdArflQnty "ENM";
BA_ "SignalLongName" SG_ 1934 HVACICROtltFrtLtInbdArflQnty "Serial Data 212 : HVAC Infotainment Controls Request Outlet Front Left Inboard Airflow Quantity";
BA_ "SignalLongName" SG_ 1934 SD212_ARC "Serial Data 212 : Alive Rolling Count";
BA_ "SignalType" SG_ 1934 HVACICROtltFrtLtStat "ENM";
BA_ "SignalLongName" SG_ 1934 HVACICROtltFrtLtStat "Serial Data 212 : HVAC Infotainment Controls Request Outlet Front Left State";
BA_ "SignalType" SG_ 1934 HVACICROscMdFrtLtSet "ENM";
BA_ "SignalLongName" SG_ 1934 HVACICROscMdFrtLtSet "Serial Data 212 : HVAC Infotainment Controls Request Oscillation Mode Front Left Setting";
BA_ "SignalLongName" SG_ 1934 HVACICROtltRrRtInbdHrztlPs "Serial Data 215 : HVAC Infotainment Controls Request Outlet Rear Right Inboard Horizontal Position";
BA_ "SignalType" SG_ 1934 HVACICRHVACPwrFrtLtChg "ENM";
BA_ "SignalLongName" SG_ 1934 HVACICRHVACPwrFrtLtChg "Serial Data 212 : HVAC Infotainment Controls Request HVAC Power Front Left Change";
BA_ "SignalType" SG_ 1934 HVACICROscMdRrRtSet "ENM";
BA_ "SignalLongName" SG_ 1934 HVACICROscMdRrRtSet "Serial Data 215 : HVAC Infotainment Controls Request Oscillation Mode Rear Right Setting";
BA_ "SignalLongName" SG_ 1934 HVACICROtltRrRtInbdVrtPs "Serial Data 215 : HVAC Infotainment Controls Request Outlet Rear Right Inboard Vertical Position";
BA_ "SignalType" SG_ 1934 HVACICRHVACPwrRrRtChg "ENM";
BA_ "SignalLongName" SG_ 1934 HVACICRHVACPwrRrRtChg "Serial Data 215 : HVAC Infotainment Controls Request HVAC Power Rear Right Change";
BA_ "SignalLongName" SG_ 1934 SD215_ARC "Serial Data 215 : Alive Rolling Count";
BA_ "SignalType" SG_ 1934 HVACICROtltRrRtStat "ENM";
BA_ "SignalLongName" SG_ 1934 HVACICROtltRrRtStat "Serial Data 215 : HVAC Infotainment Controls Request Outlet Rear Right State";
BA_ "SignalLongName" SG_ 1341 HVACICFRFrBlwCkt1IndtmFailEvaln "Serial Data 218 : HVAC Infotainment Controls FIDM Request Front Blower Circuit 1 Indeterminate Fail Evaluations";
BA_ "SignalLongName" SG_ 1341 HVACICFRFrBlwCkt1OORHiFailEvaln "Serial Data 218 : HVAC Infotainment Controls FIDM Request Front Blower Circuit 1 Out Of Range High Fail Evaluations";
BA_ "SignalLongName" SG_ 1341 HVACICFRFrBlwCkt1OORLoFailEvaln "Serial Data 218 : HVAC Infotainment Controls FIDM Request Front Blower Circuit 1 Out Of Range Low Fail Evaluations";
BA_ "SignalLongName" SG_ 1341 HVACICFRFrtBlwCkt1TotEvaln "Serial Data 218 : HVAC Infotainment Controls FIDM Request Front Blower Circuit 1 Total Evaluations";
BA_ "SignalType" SG_ 1341 HVACICFRFrtBlwCkt1InvDatDtd "ENM";
BA_ "SignalLongName" SG_ 1341 HVACICFRFrtBlwCkt1InvDatDtd "Serial Data 218 : HVAC Infotainment Controls FIDM Request Front Blower Circuit 1 Invalid Data Detected";
BA_ "SignalType" SG_ 1341 HVACICFRFrtBlwCkt1DatRxd "ENM";
BA_ "SignalLongName" SG_ 1341 HVACICFRFrtBlwCkt1DatRxd "Serial Data 218 : HVAC Infotainment Controls FIDM Request Front Blower Circuit 1 Data Received";
BA_ "SignalLongName" SG_ 1341 SD218_ARC "Serial Data 218 : Alive Rolling Count";
BA_ "SignalLongName" SG_ 1339 HVACICFRFrBlwCkt2IndtmFailEvaln "Serial Data 219 : HVAC Infotainment Controls FIDM Request Front Blower Circuit 2 Indeterminate Fail Evaluations";
BA_ "SignalLongName" SG_ 1339 HVACICFRFrBlwCkt2OORHiFailEvaln "Serial Data 219 : HVAC Infotainment Controls FIDM Request Front Blower Circuit 2 Out Of Range High Fail Evaluations";
BA_ "SignalLongName" SG_ 1339 HVACICFRFrBlwCkt2OORLoFailEvaln "Serial Data 219 : HVAC Infotainment Controls FIDM Request Front Blower Circuit 2 Out Of Range Low Fail Evaluations";
BA_ "SignalLongName" SG_ 1339 HVACICFRFrtBlwCkt2TotEvaln "Serial Data 219 : HVAC Infotainment Controls FIDM Request Front Blower Circuit 2 Total Evaluations";
BA_ "SignalType" SG_ 1339 HVACICFRFrtBlwCkt2InvDatDtd "ENM";
BA_ "SignalLongName" SG_ 1339 HVACICFRFrtBlwCkt2InvDatDtd "Serial Data 219 : HVAC Infotainment Controls FIDM Request Front Blower Circuit 2 Invalid Data Detected";
BA_ "SignalType" SG_ 1339 HVACICFRFrtBlwCkt2DatRxd "ENM";
BA_ "SignalLongName" SG_ 1339 HVACICFRFrtBlwCkt2DatRxd "Serial Data 219 : HVAC Infotainment Controls FIDM Request Front Blower Circuit 2 Data Received";
BA_ "SignalLongName" SG_ 1339 SD219_ARC "Serial Data 219 : Alive Rolling Count";
BA_ "SignalLongName" SG_ 1337 HVACICFRFrLtTmpCkt1IndtmFlEvaln "Serial Data 220 : HVAC Infotainment Controls FIDM Request Front Left Temperature Circuit 1 Indeterminate Fail Evaluations";
BA_ "SignalLongName" SG_ 1337 HVACICFRFrLtTmpCkt1OORHiFlEvaln "Serial Data 220 : HVAC Infotainment Controls FIDM Request Front Left Temperature Circuit 1 Out Of Range High Fail Evaluations";
BA_ "SignalLongName" SG_ 1337 HVACICFRFrLtTmpCkt1OORLoFlEvaln "Serial Data 220 : HVAC Infotainment Controls FIDM Request Front Left Temperature Circuit 1 Out Of Range Low Fail Evaluations";
BA_ "SignalLongName" SG_ 1337 HVACICFRFrtLtTempCkt1TotEvaln "Serial Data 220 : HVAC Infotainment Controls FIDM Request Front Left Temperature Circuit 1 Total Evaluations";
BA_ "SignalType" SG_ 1337 HVACICFRFrtLtTempCkt1InvDatDtd "ENM";
BA_ "SignalLongName" SG_ 1337 HVACICFRFrtLtTempCkt1InvDatDtd "Serial Data 220 : HVAC Infotainment Controls FIDM Request Front Left Temperature Circuit 1 Invalid Data Detected";
BA_ "SignalType" SG_ 1337 HVACICFRFrtLtTempCkt1DatRxd "ENM";
BA_ "SignalLongName" SG_ 1337 HVACICFRFrtLtTempCkt1DatRxd "Serial Data 220 : HVAC Infotainment Controls FIDM Request Front Left Temperature Circuit 1 Data Received";
BA_ "SignalLongName" SG_ 1337 SD220_ARC "Serial Data 220 : Alive Rolling Count";
BA_ "SignalLongName" SG_ 1144 HVACICFRFrLtTmpCkt2IndtmFlEvaln "Serial Data 221 : HVAC Infotainment Controls FIDM Request Front Left Temperature Circuit 2 Indeterminate Fail Evaluations";
BA_ "SignalLongName" SG_ 1144 HVACICFRFrLtTmpCkt2OORHiFlEvaln "Serial Data 221 : HVAC Infotainment Controls FIDM Request Front Left Temperature Circuit 2 Out Of Range High Fail Evaluations";
BA_ "SignalLongName" SG_ 1144 HVACICFRFrLtTmpCkt2OORLoFlEvaln "Serial Data 221 : HVAC Infotainment Controls FIDM Request Front Left Temperature Circuit 2 Out Of Range Low Fail Evaluations";
BA_ "SignalLongName" SG_ 1144 HVACICFRFrtLtTempCkt2TotEvaln "Serial Data 221 : HVAC Infotainment Controls FIDM Request Front Left Temperature Circuit 2 Total Evaluations";
BA_ "SignalType" SG_ 1144 HVACICFRFrtLtTempCkt2InvDatDtd "ENM";
BA_ "SignalLongName" SG_ 1144 HVACICFRFrtLtTempCkt2InvDatDtd "Serial Data 221 : HVAC Infotainment Controls FIDM Request Front Left Temperature Circuit 2 Invalid Data Detected";
BA_ "SignalType" SG_ 1144 HVACICFRFrtLtTempCkt2DatRxd "ENM";
BA_ "SignalLongName" SG_ 1144 HVACICFRFrtLtTempCkt2DatRxd "Serial Data 221 : HVAC Infotainment Controls FIDM Request Front Left Temperature Circuit 2 Data Received";
BA_ "SignalLongName" SG_ 1144 SD221_ARC "Serial Data 221 : Alive Rolling Count";
BA_ "SignalLongName" SG_ 1937 HVACICFRFrLtTmpCkt3IndtmFlEvaln "Serial Data 222 : HVAC Infotainment Controls FIDM Request Front Left Temperature Circuit 3 Indeterminate Fail Evaluations";
BA_ "SignalLongName" SG_ 1937 HVACICFRFrLtTmpCkt3OORHiFlEvaln "Serial Data 222 : HVAC Infotainment Controls FIDM Request Front Left Temperature Circuit 3 Out Of Range High Fail Evaluations";
BA_ "SignalLongName" SG_ 1937 HVACICFRFrLtTmpCkt3OORLoFlEvaln "Serial Data 222 : HVAC Infotainment Controls FIDM Request Front Left Temperature Circuit 3 Out Of Range Low Fail Evaluations";
BA_ "SignalLongName" SG_ 1937 HVACICFRFrtLtTempCkt3TotEvaln "Serial Data 222 : HVAC Infotainment Controls FIDM Request Front Left Temperature Circuit 3 Total Evaluations";
BA_ "SignalType" SG_ 1937 HVACICFRFrtLtTempCkt3InvDatDtd "ENM";
BA_ "SignalLongName" SG_ 1937 HVACICFRFrtLtTempCkt3InvDatDtd "Serial Data 222 : HVAC Infotainment Controls FIDM Request Front Left Temperature Circuit 3 Invalid Data Detected";
BA_ "SignalType" SG_ 1937 HVACICFRFrtLtTempCkt3DatRxd "ENM";
BA_ "SignalLongName" SG_ 1937 HVACICFRFrtLtTempCkt3DatRxd "Serial Data 222 : HVAC Infotainment Controls FIDM Request Front Left Temperature Circuit 3 Data Received";
BA_ "SignalLongName" SG_ 1937 SD222_ARC "Serial Data 222 : Alive Rolling Count";
BA_ "SignalLongName" SG_ 1129 HVACICFRFrRtTmpCkt1IndtmFlEvaln "Serial Data 223 : HVAC Infotainment Controls FIDM Request Front Right Temperature Circuit 1 Indeterminate Fail Evaluations";
BA_ "SignalLongName" SG_ 1129 HVACICFRFrRtTmpCkt1OORHiFlEvaln "Serial Data 223 : HVAC Infotainment Controls FIDM Request Front Right Temperature Circuit 1 Out Of Range High Fail Evaluations";
BA_ "SignalLongName" SG_ 1129 HVACICFRFrRtTmpCkt1OORLoFlEvaln "Serial Data 223 : HVAC Infotainment Controls FIDM Request Front Right Temperature Circuit 1 Out Of Range Low Fail Evaluations";
BA_ "SignalLongName" SG_ 1129 HVACICFRFrtRtTempCkt1TotEvaln "Serial Data 223 : HVAC Infotainment Controls FIDM Request Front Right Temperature Circuit 1 Total Evaluations";
BA_ "SignalType" SG_ 1129 HVACICFRFrtRtTempCkt1InvDatDtd "ENM";
BA_ "SignalLongName" SG_ 1129 HVACICFRFrtRtTempCkt1InvDatDtd "Serial Data 223 : HVAC Infotainment Controls FIDM Request Front Right Temperature Circuit 1 Invalid Data Detected";
BA_ "SignalType" SG_ 1129 HVACICFRFrtRtTempCkt1DatRxd "ENM";
BA_ "SignalLongName" SG_ 1129 HVACICFRFrtRtTempCkt1DatRxd "Serial Data 223 : HVAC Infotainment Controls FIDM Request Front Right Temperature Circuit 1 Data Received";
BA_ "SignalLongName" SG_ 1129 SD223_ARC "Serial Data 223 : Alive Rolling Count";
BA_ "SignalLongName" SG_ 1938 HVACICFRFrRtTmpCkt2IndtmFlEvaln "Serial Data 224 : HVAC Infotainment Controls FIDM Request Front Right Temperature Circuit 2 Indeterminate Fail Evaluations";
BA_ "SignalLongName" SG_ 1938 HVACICFRFrRtTmpCkt2OORHiFlEvaln "Serial Data 224 : HVAC Infotainment Controls FIDM Request Front Right Temperature Circuit 2 Out Of Range High Fail Evaluations";
BA_ "SignalLongName" SG_ 1938 HVACICFRFrRtTmpCkt2OORLoFlEvaln "Serial Data 224 : HVAC Infotainment Controls FIDM Request Front Right Temperature Circuit 2 Out Of Range Low Fail Evaluations";
BA_ "SignalLongName" SG_ 1938 HVACICFRFrtRtTempCkt2TotEvaln "Serial Data 224 : HVAC Infotainment Controls FIDM Request Front Right Temperature Circuit 2 Total Evaluations";
BA_ "SignalType" SG_ 1938 HVACICFRFrtRtTempCkt2InvDatDtd "ENM";
BA_ "SignalLongName" SG_ 1938 HVACICFRFrtRtTempCkt2InvDatDtd "Serial Data 224 : HVAC Infotainment Controls FIDM Request Front Right Temperature Circuit 2 Invalid Data Detected";
BA_ "SignalType" SG_ 1938 HVACICFRFrtRtTempCkt2DatRxd "ENM";
BA_ "SignalLongName" SG_ 1938 HVACICFRFrtRtTempCkt2DatRxd "Serial Data 224 : HVAC Infotainment Controls FIDM Request Front Right Temperature Circuit 2 Data Received";
BA_ "SignalLongName" SG_ 1938 SD224_ARC "Serial Data 224 : Alive Rolling Count";
BA_ "SignalLongName" SG_ 1128 HVACICFRFrRtTmpCkt3IndtmFlEvaln "Serial Data 225 : HVAC Infotainment Controls FIDM Request Front Right Temperature Circuit 3 Indeterminate Fail Evaluations";
BA_ "SignalLongName" SG_ 1128 HVACICFRFrRtTmpCkt3OORHiFlEvaln "Serial Data 225 : HVAC Infotainment Controls FIDM Request Front Right Temperature Circuit 3 Out Of Range High Fail Evaluations";
BA_ "SignalLongName" SG_ 1128 HVACICFRFrRtTmpCkt3OORLoFlEvaln "Serial Data 225 : HVAC Infotainment Controls FIDM Request Front Right Temperature Circuit 3 Out Of Range Low Fail Evaluations";
BA_ "SignalLongName" SG_ 1128 HVACICFRFrtRtTempCkt3TotEvaln "Serial Data 225 : HVAC Infotainment Controls FIDM Request Front Right Temperature Circuit 3 Total Evaluations";
BA_ "SignalType" SG_ 1128 HVACICFRFrtRtTempCkt3InvDatDtd "ENM";
BA_ "SignalLongName" SG_ 1128 HVACICFRFrtRtTempCkt3InvDatDtd "Serial Data 225 : HVAC Infotainment Controls FIDM Request Front Right Temperature Circuit 3 Invalid Data Detected";
BA_ "SignalType" SG_ 1128 HVACICFRFrtRtTempCkt3DatRxd "ENM";
BA_ "SignalLongName" SG_ 1128 HVACICFRFrtRtTempCkt3DatRxd "Serial Data 225 : HVAC Infotainment Controls FIDM Request Front Right Temperature Circuit 3 Data Received";
BA_ "SignalLongName" SG_ 1128 SD225_ARC "Serial Data 225 : Alive Rolling Count";
BA_ "SignalLongName" SG_ 1939 HVACICFRMsg2TotEvaln "Serial Data 217 : HVAC Infotainment Controls FIDM Request Message 2 Total Evaluations";
BA_ "SignalLongName" SG_ 1939 HVACICFRTempChgFrtLt "Serial Data 217 : HVAC Infotainment Controls FIDM Request Temperature Change Front Left";
BA_ "SignalLongName" SG_ 1939 HVACICFRBlwLvlChgFrt "Serial Data 217 : HVAC Infotainment Controls FIDM Request Blower Level Change Front";
BA_ "SignalType" SG_ 1939 HVACICFRBlwLvlFrtSnsdStat1 "ENM";
BA_ "SignalLongName" SG_ 1939 HVACICFRBlwLvlFrtSnsdStat1 "Serial Data 217 : HVAC Infotainment Controls FIDM Request Blower Level Front Sensed State 1";
BA_ "SignalLongName" SG_ 1939 HVACICFRTempChgFrtRt "Serial Data 217 : HVAC Infotainment Controls FIDM Request Temperature Change Front Right";
BA_ "SignalType" SG_ 1939 HVACICFRTempFrtLtSnsdStat1 "ENM";
BA_ "SignalLongName" SG_ 1939 HVACICFRTempFrtLtSnsdStat1 "Serial Data 217 : HVAC Infotainment Controls FIDM Request Temperature Front Left Sensed State 1";
BA_ "SignalType" SG_ 1939 HVACICFRBlwLvlFrtSnsdStat2 "ENM";
BA_ "SignalLongName" SG_ 1939 HVACICFRBlwLvlFrtSnsdStat2 "Serial Data 217 : HVAC Infotainment Controls FIDM Request Blower Level Front Sensed State 2";
BA_ "SignalType" SG_ 1939 HVACICFRTempFrtRtSnsdStat2 "ENM";
BA_ "SignalLongName" SG_ 1939 HVACICFRTempFrtRtSnsdStat2 "Serial Data 217 : HVAC Infotainment Controls FIDM Request Temperature Front Right Sensed State 2";
BA_ "SignalType" SG_ 1939 HVACICFRTempFrtRtSnsdStat1 "ENM";
BA_ "SignalLongName" SG_ 1939 HVACICFRTempFrtRtSnsdStat1 "Serial Data 217 : HVAC Infotainment Controls FIDM Request Temperature Front Right Sensed State 1";
BA_ "SignalType" SG_ 1939 HVACICFRTempFrtLtSnsdStat2 "ENM";
BA_ "SignalLongName" SG_ 1939 HVACICFRTempFrtLtSnsdStat2 "Serial Data 217 : HVAC Infotainment Controls FIDM Request Temperature Front Left Sensed State 2";
BA_ "SignalLongName" SG_ 1939 SD217_ARC "Serial Data 217 : Alive Rolling Count";
BA_ "SignalType" SG_ 1939 HVACICFRTempFrtRtCorrSts "ENM";
BA_ "SignalLongName" SG_ 1939 HVACICFRTempFrtRtCorrSts "Serial Data 217 : HVAC Infotainment Controls FIDM Request Temperature Front Right Correlation Status";
BA_ "SignalType" SG_ 1939 HVACICFRTempFrtLtCorrSts "ENM";
BA_ "SignalLongName" SG_ 1939 HVACICFRTempFrtLtCorrSts "Serial Data 217 : HVAC Infotainment Controls FIDM Request Temperature Front Left Correlation Status";
BA_ "SignalType" SG_ 1939 HVACICFRBlwLvlFrtCorrSts "ENM";
BA_ "SignalLongName" SG_ 1939 HVACICFRBlwLvlFrtCorrSts "Serial Data 217 : HVAC Infotainment Controls FIDM Request Blower Level Front Correlation Status";
BA_ "SignalType" SG_ 1939 HVACICFRTempFrtRtDatErr "ENM";
BA_ "SignalLongName" SG_ 1939 HVACICFRTempFrtRtDatErr "Serial Data 217 : HVAC Infotainment Controls FIDM Request Temperature Front Right Data Error";
BA_ "SignalType" SG_ 1939 HVACICFRTempFrtLtDatErr "ENM";
BA_ "SignalLongName" SG_ 1939 HVACICFRTempFrtLtDatErr "Serial Data 217 : HVAC Infotainment Controls FIDM Request Temperature Front Left Data Error";
BA_ "SignalType" SG_ 1939 HVACICFRMsg2InvDatDtd "ENM";
BA_ "SignalLongName" SG_ 1939 HVACICFRMsg2InvDatDtd "Serial Data 217 : HVAC Infotainment Controls FIDM Request Message 2 Invalid Data Detected";
BA_ "SignalType" SG_ 1939 HVACICFRMsg2DatRxd "ENM";
BA_ "SignalLongName" SG_ 1939 HVACICFRMsg2DatRxd "Serial Data 217 : HVAC Infotainment Controls FIDM Request Message 2 Data Received";
BA_ "SignalType" SG_ 1939 HVACICFRBlwLvlFrtDatErr "ENM";
BA_ "SignalLongName" SG_ 1939 HVACICFRBlwLvlFrtDatErr "Serial Data 217 : HVAC Infotainment Controls FIDM Request Blower Level Front Data Error";
BA_ "SignalLongName" SG_ 1127 HVACICFRMsg1TotEvaln "Serial Data 216 : HVAC Infotainment Controls FIDM Request Message 1 Total Evaluations";
BA_ "SignalType" SG_ 1127 HVACICFRFrtHVACAutoSnsdStat "ENM";
BA_ "SignalLongName" SG_ 1127 HVACICFRFrtHVACAutoSnsdStat "Serial Data 216 : HVAC Infotainment Controls FIDM Request Front HVAC Auto Sensed State";
BA_ "SignalType" SG_ 1127 HVACICFRFrtDefrSnsdStat "ENM";
BA_ "SignalLongName" SG_ 1127 HVACICFRFrtDefrSnsdStat "Serial Data 216 : HVAC Infotainment Controls FIDM Request Front Defrost Sensed State";
BA_ "SignalType" SG_ 1127 HVACICFRCompSnsdStat "ENM";
BA_ "SignalLongName" SG_ 1127 HVACICFRCompSnsdStat "Serial Data 216 : HVAC Infotainment Controls FIDM Request Compressor Sensed State";
BA_ "SignalType" SG_ 1127 HVACICFRRrDfgSnsdStat "ENM";
BA_ "SignalLongName" SG_ 1127 HVACICFRRrDfgSnsdStat "Serial Data 216 : HVAC Infotainment Controls FIDM Request Rear Defog Sensed State";
BA_ "SignalType" SG_ 1127 HVACICFRRecircSnsdStat "ENM";
BA_ "SignalLongName" SG_ 1127 HVACICFRRecircSnsdStat "Serial Data 216 : HVAC Infotainment Controls FIDM Request Recirculation Sensed State";
BA_ "SignalType" SG_ 1127 HVACICFRHtSnsdStat "ENM";
BA_ "SignalLongName" SG_ 1127 HVACICFRHtSnsdStat "Serial Data 216 : HVAC Infotainment Controls FIDM Request Heat Sensed State";
BA_ "SignalType" SG_ 1127 HVACICFRFrtHVACAutoDatErr "ENM";
BA_ "SignalLongName" SG_ 1127 HVACICFRFrtHVACAutoDatErr "Serial Data 216 : HVAC Infotainment Controls FIDM Request Front HVAC Auto Data Error";
BA_ "SignalType" SG_ 1127 HVACICFRFrtDefrDatErr "ENM";
BA_ "SignalLongName" SG_ 1127 HVACICFRFrtDefrDatErr "Serial Data 216 : HVAC Infotainment Controls FIDM Request Front Defrost Data Error";
BA_ "SignalType" SG_ 1127 HVACICFRCompSetChg "ENM";
BA_ "SignalLongName" SG_ 1127 HVACICFRCompSetChg "Serial Data 216 : HVAC Infotainment Controls FIDM Request Compressor Setting Change";
BA_ "SignalType" SG_ 1127 HVACICFRCompDatErr "ENM";
BA_ "SignalLongName" SG_ 1127 HVACICFRCompDatErr "Serial Data 216 : HVAC Infotainment Controls FIDM Request Compressor Data Error";
BA_ "SignalLongName" SG_ 1127 SD216_ARC "Serial Data 216 : Alive Rolling Count";
BA_ "SignalType" SG_ 1127 HVACICFRRecircSetChg "ENM";
BA_ "SignalLongName" SG_ 1127 HVACICFRRecircSetChg "Serial Data 216 : HVAC Infotainment Controls FIDM Request Recirculation Setting Change";
BA_ "SignalType" SG_ 1127 HVACICFRRecircDatErr "ENM";
BA_ "SignalLongName" SG_ 1127 HVACICFRRecircDatErr "Serial Data 216 : HVAC Infotainment Controls FIDM Request Recirculation Data Error";
BA_ "SignalType" SG_ 1127 HVACICFRMsg1InvDatDtd "ENM";
BA_ "SignalLongName" SG_ 1127 HVACICFRMsg1InvDatDtd "Serial Data 216 : HVAC Infotainment Controls FIDM Request Message 1 Invalid Data Detected";
BA_ "SignalType" SG_ 1127 HVACICFRMsg1DatRxd "ENM";
BA_ "SignalLongName" SG_ 1127 HVACICFRMsg1DatRxd "Serial Data 216 : HVAC Infotainment Controls FIDM Request Message 1 Data Received";
BA_ "SignalType" SG_ 1127 HVACICFRMaxDefrChg "ENM";
BA_ "SignalLongName" SG_ 1127 HVACICFRMaxDefrChg "Serial Data 216 : HVAC Infotainment Controls FIDM Request Max Defrost Change";
BA_ "SignalType" SG_ 1127 HVACICFRHtSetChg "ENM";
BA_ "SignalLongName" SG_ 1127 HVACICFRHtSetChg "Serial Data 216 : HVAC Infotainment Controls FIDM Request Heat Setting Change";
BA_ "SignalType" SG_ 1127 HVACICFRHtDatErr "ENM";
BA_ "SignalLongName" SG_ 1127 HVACICFRHtDatErr "Serial Data 216 : HVAC Infotainment Controls FIDM Request Heat Data Error";
BA_ "SignalType" SG_ 1127 HVACICFRFrtHVACAutoSetChg "ENM";
BA_ "SignalLongName" SG_ 1127 HVACICFRFrtHVACAutoSetChg "Serial Data 216 : HVAC Infotainment Controls FIDM Request Front HVAC Auto Setting Change";
BA_ "SignalType" SG_ 1127 HVACICFRRrDfgSetChg "ENM";
BA_ "SignalLongName" SG_ 1127 HVACICFRRrDfgSetChg "Serial Data 216 : HVAC Infotainment Controls FIDM Request Rear Defog Setting Change";
BA_ "SignalType" SG_ 1127 HVACICFRRrDfgDatErr "ENM";
BA_ "SignalLongName" SG_ 1127 HVACICFRRrDfgDatErr "Serial Data 216 : HVAC Infotainment Controls FIDM Request Rear Defog Data Error";
BA_ "SignalType" SG_ 736 HVACICFRDiag2InvDatDtd "ENM";
BA_ "SignalLongName" SG_ 736 HVACICFRDiag2InvDatDtd "Serial Data 226 : HVAC Infotainment Controls FIDM Request Diagnostic 2 Invalid Data Detected";
BA_ "SignalType" SG_ 736 HVACICFRDiag2DatRxd "ENM";
BA_ "SignalLongName" SG_ 736 HVACICFRDiag2DatRxd "Serial Data 226 : HVAC Infotainment Controls FIDM Request Diagnostic 2 Data Received";
BA_ "SignalType" SG_ 736 HVACICFRDiag1InvDatDtd "ENM";
BA_ "SignalLongName" SG_ 736 HVACICFRDiag1InvDatDtd "Serial Data 226 : HVAC Infotainment Controls FIDM Request Diagnostic 1 Invalid Data Detected";
BA_ "SignalType" SG_ 736 HVACICFRDiag1DatRxd "ENM";
BA_ "SignalLongName" SG_ 736 HVACICFRDiag1DatRxd "Serial Data 226 : HVAC Infotainment Controls FIDM Request Diagnostic 1 Data Received";
BA_ "SignalLongName" SG_ 736 SD226_ARC "Serial Data 226 : Alive Rolling Count";
BA_ "SignalType" SG_ 736 HVACICFRIntrnlCmptErr "ENM";
BA_ "SignalLongName" SG_ 736 HVACICFRIntrnlCmptErr "Serial Data 226 : HVAC Infotainment Controls FIDM Request Internal Component Error";
BA_ "SignalType" SG_ 736 InfoCtlFBTchscrnDiag2InvDatDtd "ENM";
BA_ "SignalLongName" SG_ 736 InfoCtlFBTchscrnDiag2InvDatDtd "Serial Data 226 : Infotainment Controls FIDM B Touchscreen Diagnostic 2 Invalid Data Detected";
BA_ "SignalType" SG_ 736 InfoCtlFBTchscrnDiag2DatRxd "ENM";
BA_ "SignalLongName" SG_ 736 InfoCtlFBTchscrnDiag2DatRxd "Serial Data 226 : Infotainment Controls FIDM B Touchscreen Diagnostic 2 Data Received";
BA_ "SignalType" SG_ 736 InfoCtlFBTchscrnDiag1InvDatDtd "ENM";
BA_ "SignalLongName" SG_ 736 InfoCtlFBTchscrnDiag1InvDatDtd "Serial Data 226 : Infotainment Controls FIDM B Touchscreen Diagnostic 1 Invalid Data Detected";
BA_ "SignalType" SG_ 736 InfoCtlFBTchscrnDiag1DatRxd "ENM";
BA_ "SignalLongName" SG_ 736 InfoCtlFBTchscrnDiag1DatRxd "Serial Data 226 : Infotainment Controls FIDM B Touchscreen Diagnostic 1 Data Received";
BA_ "SignalType" SG_ 736 InfoCtlFBIntrnlCmpErr "ENM";
BA_ "SignalLongName" SG_ 736 InfoCtlFBIntrnlCmpErr "Serial Data 226 : Infotainment Controls FIDM B Internal Component Error";
BA_ "SignalType" SG_ 736 HVACICVRIntrnlCmptErr "ENM";
BA_ "SignalLongName" SG_ 736 HVACICVRIntrnlCmptErr "Serial Data 226 : HVAC Infotainment Controls VCU Request Internal Component Error";
BA_ "SignalType" SG_ 1942 StVntdCoolCushLvlRRSet "ENM";
BA_ "SignalLongName" SG_ 1942 StVntdCoolCushLvlRRSet "Seat Heated Vented or Cooled Right Rear Information : Seat Vented or Cooled Cushion Level Right Rear Setting";
BA_ "SignalType" SG_ 1942 StVntdCoolBkLvlRRSet "ENM";
BA_ "SignalLongName" SG_ 1942 StVntdCoolBkLvlRRSet "Seat Heated Vented or Cooled Right Rear Information : Seat Vented or Cooled Back Level Right Rear Setting";
BA_ "SignalType" SG_ 1942 StHtdCushLvlRRSet "ENM";
BA_ "SignalLongName" SG_ 1942 StHtdCushLvlRRSet "Seat Heated Vented or Cooled Right Rear Information : Seat Heated Cushion Level Right Rear Setting";
BA_ "SignalType" SG_ 1942 StHtdBkLvlRRSet "ENM";
BA_ "SignalLongName" SG_ 1942 StHtdBkLvlRRSet "Seat Heated Vented or Cooled Right Rear Information : Seat Heated Back Level Right Rear Setting";
BA_ "SignalType" SG_ 1942 DlvryModeActv "ENM";
BA_ "SignalLongName" SG_ 1942 DlvryModeActv "Delivery Mode Active";
BA_ "SignalType" SG_ 1942 RrPedtrnClsnMtgnVisAlrtReq "ENM";
BA_ "SignalLongName" SG_ 1942 RrPedtrnClsnMtgnVisAlrtReq "Rear Pedestrian Collision Mitigation Visual Alert Request";
BA_ "SignalType" SG_ 1942 RTESTlmDatUpdtIndActv "ENM";
BA_ "SignalLongName" SG_ 1942 RTESTlmDatUpdtIndActv "Real Time Energy Status Telematics Data Update Indication Active";
BA_ "SignalType" SG_ 1942 SGI2P_AirSpnsnRdHghtTgtStsAuth "ENM";
BA_ "SignalLongName" SG_ 1942 SGI2P_AirSpnsnRdHghtTgtStsAuth "Suspension General Information 2 Protected : Air Suspension Ride Height Target Status Authenticated";
BA_ "SignalType" SG_ 1124 StVntdCoolBkLvlLRVirtCtlReq "ENM";
BA_ "SignalLongName" SG_ 1124 StVntdCoolBkLvlLRVirtCtlReq "Seat Heated Vented or Cooled Left Rear Virtual Control Requests : Seat Vented or Cooled Back Level Left Rear Virtual Control Request";
BA_ "SignalType" SG_ 1124 StHtdCushLvlLRVirtCtlReq "ENM";
BA_ "SignalLongName" SG_ 1124 StHtdCushLvlLRVirtCtlReq "Seat Heated Vented or Cooled Left Rear Virtual Control Requests : Seat Heated Cushion Level Left Rear Virtual Control Request";
BA_ "SignalType" SG_ 1124 StHtdBkLvlLRVirtCtlReq "ENM";
BA_ "SignalLongName" SG_ 1124 StHtdBkLvlLRVirtCtlReq "Seat Heated Vented or Cooled Left Rear Virtual Control Requests : Seat Heated Back Level Left Rear Virtual Control Request";
BA_ "SignalType" SG_ 1124 StHtdCushLvlRFVirtCtlReq "ENM";
BA_ "SignalLongName" SG_ 1124 StHtdCushLvlRFVirtCtlReq "Seat Heated Vented or Cooled Right Front Virtual Control Requests : Seat Heated Cushion Level Right Front Virtual Control Request";
BA_ "SignalType" SG_ 1124 StHtdBkLvlRFVirtCtlReq "ENM";
BA_ "SignalLongName" SG_ 1124 StHtdBkLvlRFVirtCtlReq "Seat Heated Vented or Cooled Right Front Virtual Control Requests : Seat Heated Back Level Right Front Virtual Control Request";
BA_ "SignalType" SG_ 1124 StVntdCoolCushLvlLRVirtCtlReq "ENM";
BA_ "SignalLongName" SG_ 1124 StVntdCoolCushLvlLRVirtCtlReq "Seat Heated Vented or Cooled Left Rear Virtual Control Requests : Seat Vented or Cooled Cushion Level Left Rear Virtual Control Request";
BA_ "SignalType" SG_ 1124 StVntdCoolCushLvlRFVirtCtlReq "ENM";
BA_ "SignalLongName" SG_ 1124 StVntdCoolCushLvlRFVirtCtlReq "Seat Heated Vented or Cooled Right Front Virtual Control Requests : Seat Vented or Cooled Cushion Level Right Front Virtual Control Request";
BA_ "SignalType" SG_ 1124 StVntdCoolBkLvlRFVirtCtlReq "ENM";
BA_ "SignalLongName" SG_ 1124 StVntdCoolBkLvlRFVirtCtlReq "Seat Heated Vented or Cooled Right Front Virtual Control Requests : Seat Vented or Cooled Back Level Right Front Virtual Control Request";
BA_ "SignalType" SG_ 1124 StVntdCoolBkLvlRRVirtCtlReq "ENM";
BA_ "SignalLongName" SG_ 1124 StVntdCoolBkLvlRRVirtCtlReq "Seat Heated Vented or Cooled Right Rear Virtual Control Requests : Seat Vented or Cooled Back Level Right Rear Virtual Control Request";
BA_ "SignalType" SG_ 1124 StHtdCushLvlRRVirtCtlReq "ENM";
BA_ "SignalLongName" SG_ 1124 StHtdCushLvlRRVirtCtlReq "Seat Heated Vented or Cooled Right Rear Virtual Control Requests : Seat Heated Cushion Level Right Rear Virtual Control Request";
BA_ "SignalType" SG_ 1124 StHtdBkLvlRRVirtCtlReq "ENM";
BA_ "SignalLongName" SG_ 1124 StHtdBkLvlRRVirtCtlReq "Seat Heated Vented or Cooled Right Rear Virtual Control Requests : Seat Heated Back Level Right Rear Virtual Control Request";
BA_ "SignalType" SG_ 1124 StMemLRVirtCtlReq "ENM";
BA_ "SignalLongName" SG_ 1124 StMemLRVirtCtlReq "Seat Memory Left Rear Virtual Control Request";
BA_ "SignalType" SG_ 1124 StVntdCoolCushLvlRRVirtCtlReq "ENM";
BA_ "SignalLongName" SG_ 1124 StVntdCoolCushLvlRRVirtCtlReq "Seat Heated Vented or Cooled Right Rear Virtual Control Requests : Seat Vented or Cooled Cushion Level Right Rear Virtual Control Request";
BA_ "SignalType" SG_ 1124 StMemRFVirtCtlReq "ENM";
BA_ "SignalLongName" SG_ 1124 StMemRFVirtCtlReq "Seat Memory Right Front Virtual Control Request";
BA_ "SignalType" SG_ 1124 RrDrOpnCmfRclCstChgSetReq "ENM";
BA_ "SignalLongName" SG_ 1124 RrDrOpnCmfRclCstChgSetReq "Rear Door Open Comfort Recall Customization Change Setting Request";
BA_ "SignalType" SG_ 1124 StMemRRVirtCtlReq "ENM";
BA_ "SignalLongName" SG_ 1124 StMemRRVirtCtlReq "Seat Memory Right Rear Virtual Control Request";
BA_ "SignalType" SG_ 1124 VirtFrtPsStInfoDspFRstReq "ENM";
BA_ "SignalLongName" SG_ 1124 VirtFrtPsStInfoDspFRstReq "Virtual Front Passenger Seat Infotainment Display Force Reset Request";
BA_ "SignalType" SG_ 1124 PhnWrlsChrg1DsbldCstChgSetReq "ENM";
BA_ "SignalLongName" SG_ 1124 PhnWrlsChrg1DsbldCstChgSetReq "Phone Wireless Charging 1 Disabled Customization Change Setting Request";
BA_ "SignalType" SG_ 1124 DlvryModeVwgCstChgSetReq "ENM";
BA_ "SignalLongName" SG_ 1124 DlvryModeVwgCstChgSetReq "Delivery Mode Viewing Customization Change Setting Request";
BA_ "SignalLongName" SG_ 1943 RTESInstPwrWlIn "Real Time Energy Status Instant Power from Wall Input";
BA_ "SignalLongName" SG_ 1943 RTESEVSEMaxPwr "Real Time Energy Status Electric Vehicle Supply Equipment Maximum Power";
BA_ "SignalLongName" SG_ 1943 VehNeutAbuseSpdLimVal "Vehicle Neutral Abuse Information : Vehicle Neutral Abuse Speed Limit Value";
BA_ "SignalLongName" SG_ 1943 ClmCtlCbnFrtLtTempSet "Serial Data 145 : Climate Control Cabin Front Left Temperature Setting";
BA_ "SignalType" SG_ 1943 VehNeutAbuseIndReq "ENM";
BA_ "SignalLongName" SG_ 1943 VehNeutAbuseIndReq "Vehicle Neutral Abuse Information : Vehicle Neutral Abuse Indication Request";
BA_ "SignalType" SG_ 1943 ClmCtlCbnFrtLtTempSet_Inv "ENM";
BA_ "SignalLongName" SG_ 1943 ClmCtlCbnFrtLtTempSet_Inv "Serial Data 145 : Climate Control Cabin Front Left Temperature Setting Invalid";
BA_ "SignalType" SG_ 1123 VirtFrtPsStInfoDspPwrBtnCtlAval "ENM";
BA_ "SignalLongName" SG_ 1123 VirtFrtPsStInfoDspPwrBtnCtlAval "Virtual Front Passenger Seat Infotainment Display Power Button Control Available";
BA_ "SignalType" SG_ 1123 FrtPsStInfoDspPwrBtnCurrSlnVal "ENM";
BA_ "SignalLongName" SG_ 1123 FrtPsStInfoDspPwrBtnCurrSlnVal "Front Passenger Seat Infotainment Display Power Button Current Selection Value";
BA_ "SignalType" SG_ 1944 VirtRrStInfoDsp2PwrBtnCtlAval "ENM";
BA_ "SignalLongName" SG_ 1944 VirtRrStInfoDsp2PwrBtnCtlAval "Virtual Rear Seat Infotainment Display 2 Power Button Control Available";
BA_ "SignalType" SG_ 1944 VirtRrStInfoDsp1PwrBtnCtlAval "ENM";
BA_ "SignalLongName" SG_ 1944 VirtRrStInfoDsp1PwrBtnCtlAval "Virtual Rear Seat Infotainment Display 1 Power Button Control Available";
BA_ "SignalType" SG_ 1944 RrStInfoDsp2PwrBtnCurrSlnVal "ENM";
BA_ "SignalLongName" SG_ 1944 RrStInfoDsp2PwrBtnCurrSlnVal "Rear Seat Infotainment Display 2 Power Button Current Selection Value";
BA_ "SignalType" SG_ 1944 RrStInfoDsp1PwrBtnCurrSlnVal "ENM";
BA_ "SignalLongName" SG_ 1944 RrStInfoDsp1PwrBtnCurrSlnVal "Rear Seat Infotainment Display 1 Power Button Current Selection Value";
BA_ "SignalType" SG_ 1122 PhnWrlsChrg4DsbldCstChgSetReq "ENM";
BA_ "SignalLongName" SG_ 1122 PhnWrlsChrg4DsbldCstChgSetReq "Phone Wireless Charging 4 Disabled Customization Change Setting Request";
BA_ "SignalType" SG_ 1122 PhnWrlsChrg3DsbldCstChgSetReq "ENM";
BA_ "SignalLongName" SG_ 1122 PhnWrlsChrg3DsbldCstChgSetReq "Phone Wireless Charging 3 Disabled Customization Change Setting Request";
BA_ "SignalType" SG_ 1122 PhnWrlsChrg2DsbldCstChgSetReq "ENM";
BA_ "SignalLongName" SG_ 1122 PhnWrlsChrg2DsbldCstChgSetReq "Phone Wireless Charging 2 Disabled Customization Change Setting Request";
BA_ "SignalType" SG_ 1122 VirtRrStInfoDsp2PwrBtnReq "ENM";
BA_ "SignalLongName" SG_ 1122 VirtRrStInfoDsp2PwrBtnReq "Virtual Rear Seat Infotainment Display 2 Power Button Request";
BA_ "SignalType" SG_ 1122 VirtRrStInfoDsp1PwrBtnReq "ENM";
BA_ "SignalLongName" SG_ 1122 VirtRrStInfoDsp1PwrBtnReq "Virtual Rear Seat Infotainment Display 1 Power Button Request";
BA_ "SignalType" SG_ 1122 VirtFrtPsStInfoDspPwrBtnReq "ENM";
BA_ "SignalLongName" SG_ 1122 VirtFrtPsStInfoDspPwrBtnReq "Virtual Front Passenger Seat Infotainment Display Power Button Request";
BA_ "SignalLongName" SG_ 1122 FrtLtZnAudVolCtlOfst "Quad Zone Audio Volume Control : Front Left Zone Audio Volume Control Offset";
BA_ "SignalType" SG_ 1122 LnKpAsstSeltdVirtCtlReq "ENM";
BA_ "SignalLongName" SG_ 1122 LnKpAsstSeltdVirtCtlReq "Lane Keep Assist Selected Virtual Control Request";
BA_ "SignalType" SG_ 1122 VirtRrStInfoDsp2FRstReq "ENM";
BA_ "SignalLongName" SG_ 1122 VirtRrStInfoDsp2FRstReq "Virtual Rear Seat Infotainment Display 2 Force Reset Request";
BA_ "SignalType" SG_ 1122 VirtRrStInfoDsp1FRstReq "ENM";
BA_ "SignalLongName" SG_ 1122 VirtRrStInfoDsp1FRstReq "Virtual Rear Seat Infotainment Display 1 Force Reset Request";
BA_ "SignalLongName" SG_ 1122 FrtRtZnAudVolCtlOfst "Quad Zone Audio Volume Control : Front Right Zone Audio Volume Control Offset";
BA_ "SignalLongName" SG_ 1122 RrRtZnAudVolCtlOfst "Quad Zone Audio Volume Control : Rear Right Zone Audio Volume Control Offset";
BA_ "SignalLongName" SG_ 1122 RrLtZnAudVolCtlOfst "Quad Zone Audio Volume Control : Rear Left Zone Audio Volume Control Offset";
BA_ "SignalType" SG_ 1122 QdZnAudVolSyncCtlOn "ENM";
BA_ "SignalLongName" SG_ 1122 QdZnAudVolSyncCtlOn "Quad Zone Audio Volume Control : Quad Zone Audio Volume Sync Control On";
BA_ "SignalType" SG_ 1945 PhnWrlsChrg1DsbldCstSetAval "ENM";
BA_ "SignalLongName" SG_ 1945 PhnWrlsChrg1DsbldCstSetAval "Phone Wireless Charging 1 Disabled Customization Setting Available";
BA_ "SignalType" SG_ 1945 PhnWrlsChrg1DsbldCstAvlFlg7 "ENM";
BA_ "SignalLongName" SG_ 1945 PhnWrlsChrg1DsbldCstAvlFlg7 "Phone Wireless Charging 1 Disabled Customization Availability Flag 7";
BA_ "SignalType" SG_ 1945 PhnWrlsChrg1DsbldCstAvlFlg6 "ENM";
BA_ "SignalLongName" SG_ 1945 PhnWrlsChrg1DsbldCstAvlFlg6 "Phone Wireless Charging 1 Disabled Customization Availability Flag 6";
BA_ "SignalType" SG_ 1945 PhnWrlsChrg1DsbldCstAvlFlg5 "ENM";
BA_ "SignalLongName" SG_ 1945 PhnWrlsChrg1DsbldCstAvlFlg5 "Phone Wireless Charging 1 Disabled Customization Availability Flag 5";
BA_ "SignalType" SG_ 1945 PhnWrlsChrg1DsbldCstAvlFlg4 "ENM";
BA_ "SignalLongName" SG_ 1945 PhnWrlsChrg1DsbldCstAvlFlg4 "Phone Wireless Charging 1 Disabled Customization Availability Flag 4";
BA_ "SignalType" SG_ 1121 PhnWrlsChrg2DsbldCstAvlFlg2 "ENM";
BA_ "SignalLongName" SG_ 1121 PhnWrlsChrg2DsbldCstAvlFlg2 "Phone Wireless Charging 2 Disabled Customization Availability Flag 2";
BA_ "SignalType" SG_ 1121 PhnWrlsChrg2DsbldCstAvlFlg1 "ENM";
BA_ "SignalLongName" SG_ 1121 PhnWrlsChrg2DsbldCstAvlFlg1 "Phone Wireless Charging 2 Disabled Customization Availability Flag 1";
BA_ "SignalType" SG_ 1121 WrlsChrgSys2ChrgSts "ENM";
BA_ "SignalLongName" SG_ 1121 WrlsChrgSys2ChrgSts "Wireless Charging System 2 Charging Status";
BA_ "SignalType" SG_ 1121 PhnWrlsChrg2DsbldCstCurrSetVal "ENM";
BA_ "SignalLongName" SG_ 1121 PhnWrlsChrg2DsbldCstCurrSetVal "Phone Wireless Charging 2 Disabled Customization Current Setting Value";
BA_ "SignalType" SG_ 1121 PhnWrlsChrg2DsbldCstSetAval "ENM";
BA_ "SignalLongName" SG_ 1121 PhnWrlsChrg2DsbldCstSetAval "Phone Wireless Charging 2 Disabled Customization Setting Available";
BA_ "SignalType" SG_ 1121 PhnWrlsChrg2DsbldCstAvlFlg7 "ENM";
BA_ "SignalLongName" SG_ 1121 PhnWrlsChrg2DsbldCstAvlFlg7 "Phone Wireless Charging 2 Disabled Customization Availability Flag 7";
BA_ "SignalType" SG_ 1121 PhnWrlsChrg2DsbldCstAvlFlg6 "ENM";
BA_ "SignalLongName" SG_ 1121 PhnWrlsChrg2DsbldCstAvlFlg6 "Phone Wireless Charging 2 Disabled Customization Availability Flag 6";
BA_ "SignalType" SG_ 1121 PhnWrlsChrg2DsbldCstAvlFlg5 "ENM";
BA_ "SignalLongName" SG_ 1121 PhnWrlsChrg2DsbldCstAvlFlg5 "Phone Wireless Charging 2 Disabled Customization Availability Flag 5";
BA_ "SignalType" SG_ 1121 PhnWrlsChrg2DsbldCstAvlFlg4 "ENM";
BA_ "SignalLongName" SG_ 1121 PhnWrlsChrg2DsbldCstAvlFlg4 "Phone Wireless Charging 2 Disabled Customization Availability Flag 4";
BA_ "SignalType" SG_ 1121 PhnWrlsChrg2DsbldCstAvlFlg3 "ENM";
BA_ "SignalLongName" SG_ 1121 PhnWrlsChrg2DsbldCstAvlFlg3 "Phone Wireless Charging 2 Disabled Customization Availability Flag 3";
BA_ "SignalType" SG_ 1946 PhnWrlsChrg3DsbldCstAvlFlg2 "ENM";
BA_ "SignalLongName" SG_ 1946 PhnWrlsChrg3DsbldCstAvlFlg2 "Phone Wireless Charging 3 Disabled Customization Availability Flag 2";
BA_ "SignalType" SG_ 1946 PhnWrlsChrg3DsbldCstAvlFlg1 "ENM";
BA_ "SignalLongName" SG_ 1946 PhnWrlsChrg3DsbldCstAvlFlg1 "Phone Wireless Charging 3 Disabled Customization Availability Flag 1";
BA_ "SignalType" SG_ 1946 WrlsChrgSys3ChrgSts "ENM";
BA_ "SignalLongName" SG_ 1946 WrlsChrgSys3ChrgSts "Wireless Charging System 3 Charging Status";
BA_ "SignalType" SG_ 1946 PhnWrlsChrg3DsbldCstCurrSetVal "ENM";
BA_ "SignalLongName" SG_ 1946 PhnWrlsChrg3DsbldCstCurrSetVal "Phone Wireless Charging 3 Disabled Customization Current Setting Value";
BA_ "SignalType" SG_ 1946 PhnWrlsChrg3DsbldCstSetAval "ENM";
BA_ "SignalLongName" SG_ 1946 PhnWrlsChrg3DsbldCstSetAval "Phone Wireless Charging 3 Disabled Customization Setting Available";
BA_ "SignalType" SG_ 1946 PhnWrlsChrg3DsbldCstAvlFlg7 "ENM";
BA_ "SignalLongName" SG_ 1946 PhnWrlsChrg3DsbldCstAvlFlg7 "Phone Wireless Charging 3 Disabled Customization Availability Flag 7";
BA_ "SignalType" SG_ 1946 PhnWrlsChrg3DsbldCstAvlFlg6 "ENM";
BA_ "SignalLongName" SG_ 1946 PhnWrlsChrg3DsbldCstAvlFlg6 "Phone Wireless Charging 3 Disabled Customization Availability Flag 6";
BA_ "SignalType" SG_ 1946 PhnWrlsChrg3DsbldCstAvlFlg5 "ENM";
BA_ "SignalLongName" SG_ 1946 PhnWrlsChrg3DsbldCstAvlFlg5 "Phone Wireless Charging 3 Disabled Customization Availability Flag 5";
BA_ "SignalType" SG_ 1946 PhnWrlsChrg3DsbldCstAvlFlg4 "ENM";
BA_ "SignalLongName" SG_ 1946 PhnWrlsChrg3DsbldCstAvlFlg4 "Phone Wireless Charging 3 Disabled Customization Availability Flag 4";
BA_ "SignalType" SG_ 1946 PhnWrlsChrg3DsbldCstAvlFlg3 "ENM";
BA_ "SignalLongName" SG_ 1946 PhnWrlsChrg3DsbldCstAvlFlg3 "Phone Wireless Charging 3 Disabled Customization Availability Flag 3";
BA_ "SignalType" SG_ 1120 PhnWrlsChrg4DsbldCstAvlFlg2 "ENM";
BA_ "SignalLongName" SG_ 1120 PhnWrlsChrg4DsbldCstAvlFlg2 "Phone Wireless Charging 4 Disabled Customization Availability Flag 2";
BA_ "SignalType" SG_ 1120 PhnWrlsChrg4DsbldCstAvlFlg1 "ENM";
BA_ "SignalLongName" SG_ 1120 PhnWrlsChrg4DsbldCstAvlFlg1 "Phone Wireless Charging 4 Disabled Customization Availability Flag 1";
BA_ "SignalType" SG_ 1120 WrlsChrgSys4ChrgSts "ENM";
BA_ "SignalLongName" SG_ 1120 WrlsChrgSys4ChrgSts "Wireless Charging System 4 Charging Status";
BA_ "SignalType" SG_ 1120 PhnWrlsChrg4DsbldCstCurrSetVal "ENM";
BA_ "SignalLongName" SG_ 1120 PhnWrlsChrg4DsbldCstCurrSetVal "Phone Wireless Charging 4 Disabled Customization Current Setting Value";
BA_ "SignalType" SG_ 1120 PhnWrlsChrg4DsbldCstSetAval "ENM";
BA_ "SignalLongName" SG_ 1120 PhnWrlsChrg4DsbldCstSetAval "Phone Wireless Charging 4 Disabled Customization Setting Available";
BA_ "SignalType" SG_ 1120 PhnWrlsChrg4DsbldCstAvlFlg7 "ENM";
BA_ "SignalLongName" SG_ 1120 PhnWrlsChrg4DsbldCstAvlFlg7 "Phone Wireless Charging 4 Disabled Customization Availability Flag 7";
BA_ "SignalType" SG_ 1120 PhnWrlsChrg4DsbldCstAvlFlg6 "ENM";
BA_ "SignalLongName" SG_ 1120 PhnWrlsChrg4DsbldCstAvlFlg6 "Phone Wireless Charging 4 Disabled Customization Availability Flag 6";
BA_ "SignalType" SG_ 1120 PhnWrlsChrg4DsbldCstAvlFlg5 "ENM";
BA_ "SignalLongName" SG_ 1120 PhnWrlsChrg4DsbldCstAvlFlg5 "Phone Wireless Charging 4 Disabled Customization Availability Flag 5";
BA_ "SignalType" SG_ 1120 PhnWrlsChrg4DsbldCstAvlFlg4 "ENM";
BA_ "SignalLongName" SG_ 1120 PhnWrlsChrg4DsbldCstAvlFlg4 "Phone Wireless Charging 4 Disabled Customization Availability Flag 4";
BA_ "SignalType" SG_ 1120 PhnWrlsChrg4DsbldCstAvlFlg3 "ENM";
BA_ "SignalLongName" SG_ 1120 PhnWrlsChrg4DsbldCstAvlFlg3 "Phone Wireless Charging 4 Disabled Customization Availability Flag 3";
BA_ "SignalLongName" SG_ 61 PrplSysMtrBTrqAchvd "Propulsion System Motor B Torque Achieved";
BA_ "SignalType" SG_ 61 PrplSysMtrBTrqAchvd_Inv "ENM";
BA_ "SignalLongName" SG_ 61 PrplSysMtrBTrqAchvd_Inv "Propulsion System Motor B Torque Achieved Invalid";
BA_ "SignalLongName" SG_ 61 PrplSysMtrCTrqAchvd "Propulsion System Motor C Torque Achieved";
BA_ "SignalType" SG_ 61 PrplSysMtrCTrqAchvd_Inv "ENM";
BA_ "SignalLongName" SG_ 61 PrplSysMtrCTrqAchvd_Inv "Propulsion System Motor C Torque Achieved Invalid";
BA_ "SignalType" SG_ 1954 DrvrSeltdSpdLmtrVirtCtlAllwd "ENM";
BA_ "SignalLongName" SG_ 1954 DrvrSeltdSpdLmtrVirtCtlAllwd "Driver Selected Speed Limiter Virtual Control Allowed";
BA_ "SignalType" SG_ 1954 AutoVehHldVirtCtlAval "ENM";
BA_ "SignalLongName" SG_ 1954 AutoVehHldVirtCtlAval "Auto Vehicle Hold Virtual Control Available";
BA_ "SignalType" SG_ 1954 AutoVehHldVirtCurrSeltnVal "ENM";
BA_ "SignalLongName" SG_ 1954 AutoVehHldVirtCurrSeltnVal "Auto Vehicle Hold Virtual Control Current Selection Value";
BA_ "SignalType" SG_ 1954 TrfcJamAsstVirtCtlCurrSeltnVal "ENM";
BA_ "SignalLongName" SG_ 1954 TrfcJamAsstVirtCtlCurrSeltnVal "Traffic Jam Assist Virtual Control Current Selection Value";
BA_ "SignalType" SG_ 1954 DrvrSeltdSpdLmtrVirtCtlAval "ENM";
BA_ "SignalLongName" SG_ 1954 DrvrSeltdSpdLmtrVirtCtlAval "Driver Selected Speed Limiter Virtual Control Available";
BA_ "SignalType" SG_ 1954 FuelDrOpnIndOn "ENM";
BA_ "SignalLongName" SG_ 1954 FuelDrOpnIndOn "Fuel Door Open Indication On";
BA_ "SignalType" SG_ 1954 VehRefulngStat "ENM";
BA_ "SignalLongName" SG_ 1954 VehRefulngStat "Vehicle Refueling State";
BA_ "SignalType" SG_ 1954 DrvrSeltdSpdLmtrVirtCtlSeltnAvl "ENM";
BA_ "SignalLongName" SG_ 1954 DrvrSeltdSpdLmtrVirtCtlSeltnAvl "Driver Selected Speed Limiter Virtual Control Selection Available";
BA_ "SignalType" SG_ 1954 TrfcJamAsstVirtCtlAval "ENM";
BA_ "SignalLongName" SG_ 1954 TrfcJamAsstVirtCtlAval "Traffic Jam Assist Virtual Control Available";
BA_ "SignalLongName" SG_ 1954 DrPstnLF "Door Position Left Front Information : Door Position Left Front";
BA_ "SignalType" SG_ 1954 ElecTransPrkSwSeltd "ENM";
BA_ "SignalLongName" SG_ 1954 ElecTransPrkSwSeltd "Electronic Transmission Park Switch Selected";
BA_ "SignalLongName" SG_ 1954 DrPstnRF "Door Position Right Front Information : Door Position Right Front";
BA_ "SignalType" SG_ 1954 DrPstnLF_Inv "ENM";
BA_ "SignalLongName" SG_ 1954 DrPstnLF_Inv "Door Position Left Front Information : Door Position Left Front Invalid";
BA_ "SignalType" SG_ 1954 DrPstnLF_DuD "ENM";
BA_ "SignalLongName" SG_ 1954 DrPstnLF_DuD "Door Position Left Front Information : Door Position Left Front Don't Use Data";
BA_ "SignalType" SG_ 1954 HybChrgModeStat "ENM";
BA_ "SignalLongName" SG_ 1954 HybChrgModeStat "Hybrid Charge Mode State";
BA_ "SignalType" SG_ 1954 DrPstnRF_Inv "ENM";
BA_ "SignalLongName" SG_ 1954 DrPstnRF_Inv "Door Position Right Front Information : Door Position Right Front Invalid";
BA_ "SignalType" SG_ 1954 DrPstnRF_DuD "ENM";
BA_ "SignalLongName" SG_ 1954 DrPstnRF_DuD "Door Position Right Front Information : Door Position Right Front Don't Use Data";
BA_ "SignalLongName" SG_ 1955 VirtKeyPinToStrtLckoutMaxTm "Virtual Key Pin To Start Lockout Maximum Time";
BA_ "SignalType" SG_ 1955 WhlCntrCapLgtCommSts "ENM";
BA_ "SignalLongName" SG_ 1955 WhlCntrCapLgtCommSts "Wheel Center Cap Light Communication Status";
BA_ "SignalType" SG_ 1955 VirtKeyPinToStrtMaxAtmp "ENM";
BA_ "SignalLongName" SG_ 1955 VirtKeyPinToStrtMaxAtmp "Virtual Key Pin To Start Maximum Attempts";
BA_ "SignalLongName" SG_ 1955 VirtKeyPinToStrtNFCStrtMaxTm "Virtual Key Pin To Start NFC Start Maximum Time";
BA_ "SignalLongName" SG_ 1955 VirtKeyPinToStrtVldPINMaxTm "Virtual Key Pin To Start Valid PIN Maximum Time";
BA_ "SignalType" SG_ 737 SrrndVwCamsOnReqd "ENM";
BA_ "SignalLongName" SG_ 737 SrrndVwCamsOnReqd "Surround View Cameras On Requested";
BA_ "SignalType" SG_ 737 RmtVidImgXferActv "ENM";
BA_ "SignalLongName" SG_ 737 RmtVidImgXferActv "Remote Video Image Transfer Active";
BA_ "SignalType" SG_ 1917 VehConPrvdrLrnSts "ENM";
BA_ "SignalLongName" SG_ 1917 VehConPrvdrLrnSts "Vehicle Content Provider Learn Status";
BA_ "SignalType" SG_ 669 VehOnStrThftDtcted "ENM";
BA_ "SignalLongName" SG_ 669 VehOnStrThftDtcted "Vehicle OnStar Theft Detected";
BA_ "SignalType" SG_ 669 VehOnStrCrshDtcted "ENM";
BA_ "SignalLongName" SG_ 669 VehOnStrCrshDtcted "Vehicle OnStar Crash Detected";
BA_ "SignalType" SG_ 669 RmtVidImgXferReqd "ENM";
BA_ "SignalLongName" SG_ 669 RmtVidImgXferReqd "Remote Video Image Transfer Requested";
BA_ "SignalLongName" SG_ 1972 PLCM_LCMDataAvlblChksum "Power Line Communication Module - License Compliance Material Display Interface : License Compliance Material Data Available Checksum";
BA_ "SignalLongName" SG_ 1972 PLCM_LCMDataAvlblOwnID "Power Line Communication Module - License Compliance Material Display Interface : License Compliance Material Data Available Owner ID";
BA_ "SignalLongName" SG_ 1972 PLCM_LCMDataAvlblLicTag "Power Line Communication Module - License Compliance Material Display Interface : License Compliance Material Data Available License Tag";
BA_ "SignalLongName" SG_ 1972 PLCM_LCMDataAvlblTotBlks "Power Line Communication Module - License Compliance Material Display Interface : License Compliance Material Data Available Total Blocks";
BA_ "SignalType" SG_ 1973 ChrgCommBridgeDrvrNtfn "ENM";
BA_ "SignalLongName" SG_ 1973 ChrgCommBridgeDrvrNtfn "Charging Communication Bridge Driver Notification";
BA_ "SignalType" SG_ 1973 ChrgCommSLACSts "ENM";
BA_ "SignalLongName" SG_ 1973 ChrgCommSLACSts "Charging Communication Signal Level Attenuation Characterization Status";
BA_ "SignalType" SG_ 1959 TnDrvrVolLimCstCurrSetVal "ENM";
BA_ "SignalLongName" SG_ 1959 TnDrvrVolLimCstCurrSetVal "Teen Driver Volume Limit Customization Setting : Teen Driver Volume Limit Customization Current Setting Value";
BA_ "SignalLongName" SG_ 1959 TnDrvrVolLimCstLvlCurrSetVal "Teen Driver Volume Limit Customization Setting : Teen Driver Volume Limit Customization Level Current Setting Value";
BA_ "SignalType" SG_ 1959 DMPDAutoClsTmRFCstChgSetReq "ENM";
BA_ "SignalLongName" SG_ 1959 DMPDAutoClsTmRFCstChgSetReq "Delivery Mode Power Door Auto Close Time Right Front Customization Change Setting Request";
BA_ "SignalType" SG_ 1959 DMPDAutoClsTmLFCstChgSetReq "ENM";
BA_ "SignalLongName" SG_ 1959 DMPDAutoClsTmLFCstChgSetReq "Delivery Mode Power Door Auto Close Time Left Front Customization Change Setting Request";
BA_ "SignalType" SG_ 1959 DMPDClsOutofPrkRFCstChgSetReq "ENM";
BA_ "SignalLongName" SG_ 1959 DMPDClsOutofPrkRFCstChgSetReq "Delivery Mode Power Door Close Out of Park Right Front Customization Change Setting Request";
BA_ "SignalType" SG_ 1959 DMPDClsOutofPrkLFCstChgSetReq "ENM";
BA_ "SignalLongName" SG_ 1959 DMPDClsOutofPrkLFCstChgSetReq "Delivery Mode Power Door Close Out of Park Left Front Customization Change Setting Request";
BA_ "SignalType" SG_ 1959 SCAPDOpnMaxTrvlCstChgSetReq "ENM";
BA_ "SignalLongName" SG_ 1959 SCAPDOpnMaxTrvlCstChgSetReq "Side Closure Access Power Door Open Maximum Travel Customization Change Setting Request";
BA_ "SignalType" SG_ 1959 SCAPDBrktoClsRFCstChgSetReq "ENM";
BA_ "SignalLongName" SG_ 1959 SCAPDBrktoClsRFCstChgSetReq "Side Closure Access Power Door Brake to Close Right Front Customization Change Setting Request";
BA_ "SignalType" SG_ 1959 SCAPDBrktoClsLFCstChgSetReq "ENM";
BA_ "SignalLongName" SG_ 1959 SCAPDBrktoClsLFCstChgSetReq "Side Closure Access Power Door Brake to Close Left Front Customization Change Setting Request";
BA_ "SignalType" SG_ 1959 ChrgCommGtwayIntrnlFltSts "ENM";
BA_ "SignalLongName" SG_ 1959 ChrgCommGtwayIntrnlFltSts "Charging Communication Controller Status : Charging Communication Gateway Internal Fault Status";
BA_ "SignalLongName" SG_ 1959 TnDrvrVolLimCstLvlMinAllwdVal "Teen Driver Volume Limit Customization Level Minimum Allowed Value";
BA_ "SignalType" SG_ 1959 ChrgCommGtwayOprtlSts "ENM";
BA_ "SignalLongName" SG_ 1959 ChrgCommGtwayOprtlSts "Charging Communication Controller Status : Charging Communication Gateway Operational Status";
BA_ "SignalLongName" SG_ 1962 DrPstnLR "Door Position Left Rear";
BA_ "SignalLongName" SG_ 1962 DrPstnRR "Door Position Right Rear";
BA_ "SignalType" SG_ 1962 DrPstnLR_Inv "ENM";
BA_ "SignalLongName" SG_ 1962 DrPstnLR_Inv "Door Position Left Rear Invalid";
BA_ "SignalType" SG_ 1962 DrPstnLR_DuD "ENM";
BA_ "SignalLongName" SG_ 1962 DrPstnLR_DuD "Door Position Left Rear Don't Use Data";
BA_ "SignalType" SG_ 1962 DMBlkhdDrOpnVehOffCstCurrSetVal "ENM";
BA_ "SignalLongName" SG_ 1962 DMBlkhdDrOpnVehOffCstCurrSetVal "Serial Data 256 Protected : Delivery Mode Bulkhead Door Open on Vehicle Off Customization Current Setting Value";
BA_ "SignalType" SG_ 1962 DrPstnRR_Inv "ENM";
BA_ "SignalLongName" SG_ 1962 DrPstnRR_Inv "Door Position Right Rear Invalid";
BA_ "SignalType" SG_ 1962 DrPstnRR_DuD "ENM";
BA_ "SignalLongName" SG_ 1962 DrPstnRR_DuD "Door Position Right Rear Don't Use Data";
BA_ "SignalType" SG_ 1962 CstdwnModeEnbld "ENM";
BA_ "SignalLongName" SG_ 1962 CstdwnModeEnbld "Coastdown Mode Enabled";
BA_ "SignalType" SG_ 1962 PedMpLocBsdDlvryModeLtdPwrIndOn "ENM";
BA_ "SignalLongName" SG_ 1962 PedMpLocBsdDlvryModeLtdPwrIndOn "PedalMapLocationBasedDeliveryModeLimitedPowerIndicationOn";
BA_ "SignalType" SG_ 1962 DMPDDOBlkhdDrOpnRFCstCurrSetVal "ENM";
BA_ "SignalLongName" SG_ 1962 DMPDDOBlkhdDrOpnRFCstCurrSetVal "Serial Data 84 Protected : Delivery Mode Power Door Delayed Open after Bulkhead Door Open Right Front Customization Current Setting Value";
BA_ "SignalType" SG_ 1962 DMPDDOBlkhdDrOpnLFCstCurrSetVal "ENM";
BA_ "SignalLongName" SG_ 1962 DMPDDOBlkhdDrOpnLFCstCurrSetVal "Serial Data 82 Protected : Delivery Mode Power Door Delayed Open after Bulkhead Door Open Left Front Customization Current Setting Value";
BA_ "SignalType" SG_ 1963 SCAOOAByKeyFobLFCstCurrSetVal "ENM";
BA_ "SignalLongName" SG_ 1963 SCAOOAByKeyFobLFCstCurrSetVal "Side Closure Access Open On Approach By Key Fob Left Front Customization Current Setting Value";
BA_ "SignalType" SG_ 1963 SCAPDBrktoClsLFCstCurrSetVal "ENM";
BA_ "SignalLongName" SG_ 1963 SCAPDBrktoClsLFCstCurrSetVal "Side Closure Access Power Door Brake to Close Left Front Customization Current Setting Value";
BA_ "SignalType" SG_ 1963 SCAOOAByVirtKeyLFCstCurrSetVal "ENM";
BA_ "SignalLongName" SG_ 1963 SCAOOAByVirtKeyLFCstCurrSetVal "Side Closure Access Open On Approach By Virtual Key Left Front Customization Current Setting Value";
BA_ "SignalType" SG_ 1963 SCAPDOpnMaxTrvlCstCurrSetVal "ENM";
BA_ "SignalLongName" SG_ 1963 SCAPDOpnMaxTrvlCstCurrSetVal "Side Closure Access Power Door Open Maximum Travel Customization Current Setting Value";
BA_ "SignalType" SG_ 1963 CoDrvrDrOpn_DuD "ENM";
BA_ "SignalLongName" SG_ 1963 CoDrvrDrOpn_DuD "Co-Driver Door Open Don't Use Data";
BA_ "SignalType" SG_ 1963 CoDrvrDrOpn "ENM";
BA_ "SignalLongName" SG_ 1963 CoDrvrDrOpn "Co-Driver Door Open";
BA_ "SignalType" SG_ 1963 DrRROpn_Inv "ENM";
BA_ "SignalLongName" SG_ 1963 DrRROpn_Inv "Door Right Rear Open Information : Door Right Rear Open Invalid";
BA_ "SignalType" SG_ 1963 DrRROpn_DuD "ENM";
BA_ "SignalLongName" SG_ 1963 DrRROpn_DuD "Door Right Rear Open Information : Door Right Rear Open Don't Use Data";
BA_ "SignalType" SG_ 1963 DrRROpn "ENM";
BA_ "SignalLongName" SG_ 1963 DrRROpn "Door Right Rear Open Information : Door Right Rear Open";
BA_ "SignalType" SG_ 1963 DrLROpn_Inv "ENM";
BA_ "SignalLongName" SG_ 1963 DrLROpn_Inv "Door Left Rear Open Information : Door Left Rear Open Invalid";
BA_ "SignalType" SG_ 1963 DrLROpn_DuD "ENM";
BA_ "SignalLongName" SG_ 1963 DrLROpn_DuD "Door Left Rear Open Information : Door Left Rear Open Don't Use Data";
BA_ "SignalType" SG_ 1963 DrLROpn "ENM";
BA_ "SignalLongName" SG_ 1963 DrLROpn "Door Left Rear Open Information : Door Left Rear Open";
BA_ "SignalType" SG_ 1963 SCAPwrDrMtnRRVirtCtlRrAllwd "ENM";
BA_ "SignalLongName" SG_ 1963 SCAPwrDrMtnRRVirtCtlRrAllwd "Side Closure Access Power Door Motion Right Rear Virtual Control Rear Allowed";
BA_ "SignalType" SG_ 1963 SCAPwrDrMtnRRVirtCtlFrtAllwd "ENM";
BA_ "SignalLongName" SG_ 1963 SCAPwrDrMtnRRVirtCtlFrtAllwd "Side Closure Access Power Door Motion Right Rear Virtual Control Front Allowed";
BA_ "SignalType" SG_ 1963 SCAPwrDrMtnLRVirtCtlRrAllwd "ENM";
BA_ "SignalLongName" SG_ 1963 SCAPwrDrMtnLRVirtCtlRrAllwd "Side Closure Access Power Door Motion Left Rear Virtual Control Rear Allowed";
BA_ "SignalType" SG_ 1963 SCAPwrDrMtnLRVirtCtlFrtAllwd "ENM";
BA_ "SignalLongName" SG_ 1963 SCAPwrDrMtnLRVirtCtlFrtAllwd "Side Closure Access Power Door Motion Left Rear Virtual Control Front Allowed";
BA_ "SignalType" SG_ 1963 SCAPwrDrMtnLFVirtCtlAllwd "ENM";
BA_ "SignalLongName" SG_ 1963 SCAPwrDrMtnLFVirtCtlAllwd "Side Closure Access Power Door Motion Left Front Virtual Control Allowed";
BA_ "SignalType" SG_ 1963 CoDrvrDrOpn_Inv "ENM";
BA_ "SignalLongName" SG_ 1963 CoDrvrDrOpn_Inv "Co-Driver Door Open Invalid";
BA_ "SignalType" SG_ 1963 SdDrRRInMtnActv "ENM";
BA_ "SignalLongName" SG_ 1963 SdDrRRInMtnActv "Side Door Right Rear in Motion Active";
BA_ "SignalType" SG_ 1963 SdDrRFInMtnActv "ENM";
BA_ "SignalLongName" SG_ 1963 SdDrRFInMtnActv "Side Door Right Front in Motion Active";
BA_ "SignalType" SG_ 1963 SdDrLRInMtnActv "ENM";
BA_ "SignalLongName" SG_ 1963 SdDrLRInMtnActv "Side Door Left Rear in Motion Active";
BA_ "SignalType" SG_ 1963 SdDrLFInMtnActv "ENM";
BA_ "SignalLongName" SG_ 1963 SdDrLFInMtnActv "Side Door Left Front in Motion Active";
BA_ "SignalType" SG_ 1963 HtdStrgWhlInd "ENM";
BA_ "SignalLongName" SG_ 1963 HtdStrgWhlInd "Heated Steering Wheel Indication";
BA_ "SignalType" SG_ 1963 FltDrvrActvRmtCstCurrSetVal "ENM";
BA_ "SignalLongName" SG_ 1963 FltDrvrActvRmtCstCurrSetVal "Fleet Driver Active Remote Customization Current Setting Value";
BA_ "SignalType" SG_ 1963 LSCMBABP_ReqActvAuth "ENM";
BA_ "SignalLongName" SG_ 1963 LSCMBABP_ReqActvAuth "Serial Data 40 Protected : Low Speed Collision Mitigation Braking Autonomous Brake Request Active Authenticated";
BA_ "SignalType" SG_ 1963 FIMRIMABP_BrkgReqAuth "ENM";
BA_ "SignalLongName" SG_ 1963 FIMRIMABP_BrkgReqAuth "EOCM General Information 1 Protected : Rear Impact Mitigation Autonomous Brake Braking Request Authenticated";
BA_ "SignalType" SG_ 1963 ChsDynoModeEnbld "ENM";
BA_ "SignalLongName" SG_ 1963 ChsDynoModeEnbld "Serial Data 17 Protected : Chassis Dynamometer Mode Enabled";
BA_ "SignalType" SG_ 1963 HtdStrgWhlLvlIndOn "ENM";
BA_ "SignalLongName" SG_ 1963 HtdStrgWhlLvlIndOn "Heated Steering Wheel Level Indication On";
BA_ "SignalLongName" SG_ 1100 HVACICRHtdArmrstLvlChgRrLt "Serial Data 265 : HVAC Infotainment Controls Request Heated Armrest Level Change Rear Left";
BA_ "SignalLongName" SG_ 1100 HVACICRHtdArmrstLvlChgFrtRt "Serial Data 265 : HVAC Infotainment Controls Request Heated Armrest Level Change Front Right";
BA_ "SignalLongName" SG_ 1100 HVACICRHtdArmrstLvlChgFrtLt "Serial Data 265 : HVAC Infotainment Controls Request Heated Armrest Level Change Front Left";
BA_ "SignalType" SG_ 1100 HVACICRHtdArmrstLvlFrtRt "ENM";
BA_ "SignalLongName" SG_ 1100 HVACICRHtdArmrstLvlFrtRt "Serial Data 265 : HVAC Infotainment Controls Request Heated Armrest Level Front Right";
BA_ "SignalType" SG_ 1100 HVACICRHtdArmrstLvlFrtLt "ENM";
BA_ "SignalLongName" SG_ 1100 HVACICRHtdArmrstLvlFrtLt "Serial Data 265 : HVAC Infotainment Controls Request Heated Armrest Level Front Left";
BA_ "SignalLongName" SG_ 1100 HVACICRHtdArmrstLvlChgRrRt "Serial Data 265 : HVAC Infotainment Controls Request Heated Armrest Level Change Rear Right";
BA_ "SignalType" SG_ 1100 HVACICRHtdArmrstLvlFrtRtActv "ENM";
BA_ "SignalLongName" SG_ 1100 HVACICRHtdArmrstLvlFrtRtActv "Serial Data 265 : HVAC Infotainment Controls Request Heated Armrest Level Front Right Active";
BA_ "SignalType" SG_ 1100 HVACICRHtdArmrstLvlFrtLtActv "ENM";
BA_ "SignalLongName" SG_ 1100 HVACICRHtdArmrstLvlFrtLtActv "Serial Data 265 : HVAC Infotainment Controls Request Heated Armrest Level Front Left Active";
BA_ "SignalLongName" SG_ 1100 SD265_ARC "Serial Data 265 : Alive Rolling Count";
BA_ "SignalType" SG_ 1100 HVACICRHtdArmrstLvlRrRt "ENM";
BA_ "SignalLongName" SG_ 1100 HVACICRHtdArmrstLvlRrRt "Serial Data 265 : HVAC Infotainment Controls Request Heated Armrest Level Rear Right";
BA_ "SignalType" SG_ 1100 HVACICRHtdArmrstLvlRrLt "ENM";
BA_ "SignalLongName" SG_ 1100 HVACICRHtdArmrstLvlRrLt "Serial Data 265 : HVAC Infotainment Controls Request Heated Armrest Level Rear Left";
BA_ "SignalLongName" SG_ 1100 HVACInfoCtlRqBlwLvlChgThrdRw "Serial Data 264 : HVAC Infotainment Controls Request Blower Level Change Third Row";
BA_ "SignalType" SG_ 1100 HVACInfoCtlRqAirDstThrdRw "ENM";
BA_ "SignalLongName" SG_ 1100 HVACInfoCtlRqAirDstThrdRw "Serial Data 264 : HVAC Infotainment Controls Request Air Distribution Third Row";
BA_ "SignalType" SG_ 1100 HVACInfoCtlRqAirDstChgNxtThrdRw "ENM";
BA_ "SignalLongName" SG_ 1100 HVACInfoCtlRqAirDstChgNxtThrdRw "Serial Data 264 : HVAC Infotainment Controls Request Air Distribution Change Next Third Row";
BA_ "SignalType" SG_ 1100 HVACICRHtdArmrstLvlRrRtActv "ENM";
BA_ "SignalLongName" SG_ 1100 HVACICRHtdArmrstLvlRrRtActv "Serial Data 265 : HVAC Infotainment Controls Request Heated Armrest Level Rear Right Active";
BA_ "SignalType" SG_ 1100 HVACICRHtdArmrstLvlRrLtActv "ENM";
BA_ "SignalLongName" SG_ 1100 HVACICRHtdArmrstLvlRrLtActv "Serial Data 265 : HVAC Infotainment Controls Request Heated Armrest Level Rear Left Active";
BA_ "SignalLongName" SG_ 1100 HVACInfoCtlRqBlwLvlThrdRw "Serial Data 264 : HVAC Infotainment Controls Request Blower Level Third Row";
BA_ "SignalLongName" SG_ 1100 HVACInfoCtlRqTempChgThrdRw "Serial Data 264 : HVAC Infotainment Controls Request Temperature Change Third Row";
BA_ "SignalType" SG_ 1100 HVACInfoCtlRqSyncThrdRwChg "ENM";
BA_ "SignalLongName" SG_ 1100 HVACInfoCtlRqSyncThrdRwChg "Serial Data 264 : HVAC Infotainment Controls Request Sync Third Row Change";
BA_ "SignalType" SG_ 1100 HVACInfoCtlRqBlwLvlThrdRwActv "ENM";
BA_ "SignalLongName" SG_ 1100 HVACInfoCtlRqBlwLvlThrdRwActv "Serial Data 264 : HVAC Infotainment Controls Request Blower Level Third Row Active";
BA_ "SignalLongName" SG_ 1100 HVACInfoCtlRqTempLvlThrdRw "Serial Data 264 : HVAC Infotainment Controls Request Temperature Level Third Row";
BA_ "SignalLongName" SG_ 1100 SD264_ARC "Serial Data 264 : Alive Rolling Count";
BA_ "SignalType" SG_ 1100 HVACInfoCtlRqThrdRwPwrSetChg "ENM";
BA_ "SignalLongName" SG_ 1100 HVACInfoCtlRqThrdRwPwrSetChg "Serial Data 264 : HVAC Infotainment Controls Request Third Row Power Setting Change";
BA_ "SignalType" SG_ 1100 HVACInfoCtlRqThrdRwLckSetChg "ENM";
BA_ "SignalLongName" SG_ 1100 HVACInfoCtlRqThrdRwLckSetChg "Serial Data 264 : HVAC Infotainment Controls Request Third Row Lock Setting Change";
BA_ "SignalType" SG_ 1100 HVACInfoCtlRqThrdRwAutoSetChg "ENM";
BA_ "SignalLongName" SG_ 1100 HVACInfoCtlRqThrdRwAutoSetChg "Serial Data 264 : HVAC Infotainment Controls Request Third Row Auto Setting Change";
BA_ "SignalType" SG_ 1100 HVACInfoCtlRqTempLvlThrdRwActv "ENM";
BA_ "SignalLongName" SG_ 1100 HVACInfoCtlRqTempLvlThrdRwActv "Serial Data 264 : HVAC Infotainment Controls Request Temperature Level Third Row Active";
BA_ "SignalType" SG_ 1967 ChrgCommBridgeOprtlSts "ENM";
BA_ "SignalLongName" SG_ 1967 ChrgCommBridgeOprtlSts "Charging Communication Bridge Status : Charging Communication Bridge Operational Status";
BA_ "SignalType" SG_ 1967 ChrgCommBridgeIntrnlFltSts "ENM";
BA_ "SignalLongName" SG_ 1967 ChrgCommBridgeIntrnlFltSts "Charging Communication Bridge Status : Charging Communication Bridge Internal Fault Status";
BA_ "SignalType" SG_ 1420 VidTrlrTowPhs2ChmEvntStat "ENM";
BA_ "SignalLongName" SG_ 1420 VidTrlrTowPhs2ChmEvntStat "Trailering Video Viewing Phase 2 Chime Event State";
BA_ "SignalType" SG_ 1420 RrPedtrnClsnMtgnNtfyChmEvntStat "ENM";
BA_ "SignalLongName" SG_ 1420 RrPedtrnClsnMtgnNtfyChmEvntStat "Rear Pedestrian Collision Mitigation Notify Chime Event State";
BA_ "SignalType" SG_ 1420 TrlrVidVwPhs1ChmEvntStat "ENM";
BA_ "SignalLongName" SG_ 1420 TrlrVidVwPhs1ChmEvntStat "Trailering Video Viewing Phase 1 Chime Event State";
BA_ "SignalType" SG_ 1113 DMHrnOutPrkCstChgSetReq "ENM";
BA_ "SignalLongName" SG_ 1113 DMHrnOutPrkCstChgSetReq "Delivery Mode Horn Out of Park Customization Change Setting Request";
BA_ "SignalType" SG_ 1113 DMCabLgtPrkCstChgSetReq "ENM";
BA_ "SignalLongName" SG_ 1113 DMCabLgtPrkCstChgSetReq "Delivery Mode Cab Lighting on Park Customization Change Setting Request";
BA_ "SignalType" SG_ 1113 InfoFrtSnshdPstnReq "ENM";
BA_ "SignalLongName" SG_ 1113 InfoFrtSnshdPstnReq "Infotainment Front Sunshade Position Request";
BA_ "SignalType" SG_ 1113 RmtVidVwgLgtFlshReqd "ENM";
BA_ "SignalLongName" SG_ 1113 RmtVidVwgLgtFlshReqd "Remote Video Viewing Light Flash Requested";
BA_ "SignalType" SG_ 1113 RmtVidVwgIntrLgtReqd "ENM";
BA_ "SignalLongName" SG_ 1113 RmtVidVwgIntrLgtReqd "Remote Video Viewing Interior Light Requested";
BA_ "SignalType" SG_ 1113 RmtVidVwgExtLgtReqd "ENM";
BA_ "SignalLongName" SG_ 1113 RmtVidVwgExtLgtReqd "Remote Video Viewing Exterior Light Requested";
BA_ "SignalType" SG_ 1113 HtdArmrstSyncCstChgSetReq "ENM";
BA_ "SignalLongName" SG_ 1113 HtdArmrstSyncCstChgSetReq "Heated Armrest Sync Customization Change Setting Request";
BA_ "SignalType" SG_ 1113 AutoAirOtltAmgCstChgSetReq "ENM";
BA_ "SignalLongName" SG_ 1113 AutoAirOtltAmgCstChgSetReq "Automatic Air Outlet Aiming Customization Change Setting Request";
BA_ "SignalType" SG_ 1113 ArflBsdOnOccpRrPsCstChgSetReq "ENM";
BA_ "SignalLongName" SG_ 1113 ArflBsdOnOccpRrPsCstChgSetReq "Airflow Based On Occupancy Rear Passenger Customization Change Setting Request";
BA_ "SignalType" SG_ 1113 ArflBsdOnOccpFrtPsCstChgSetReq "ENM";
BA_ "SignalLongName" SG_ 1113 ArflBsdOnOccpFrtPsCstChgSetReq "Airflow Based On Occupancy Front Passenger Customization Change Setting Request";
BA_ "SignalType" SG_ 1113 TrlrTireLkDtnUserReq "ENM";
BA_ "SignalLongName" SG_ 1113 TrlrTireLkDtnUserReq "Trailer Tire Leak Detection User Request";
BA_ "SignalType" SG_ 1113 CbnAirClnFltrtnCstChgSetReq "ENM";
BA_ "SignalLongName" SG_ 1113 CbnAirClnFltrtnCstChgSetReq "Cabin Air Clean Filtration Customization Change Setting Request";
BA_ "SignalType" SG_ 1113 AutoNckScrfCstChgSetReq "ENM";
BA_ "SignalLongName" SG_ 1113 AutoNckScrfCstChgSetReq "Automatic Neck Scarf Customization Change Setting Request";
BA_ "SignalType" SG_ 1113 ClmCtlRrBlw2CtlCktOORHiFlrSts "ENM";
BA_ "SignalLongName" SG_ 1113 ClmCtlRrBlw2CtlCktOORHiFlrSts "Climate Control Rear Blower 2 Control Circuit Information : Climate Control Rear Blower 2 Control Circuit Out of Range High Failure Status";
BA_ "SignalType" SG_ 1113 ClmCtlRrBlw2CtlCktFlrSts "ENM";
BA_ "SignalLongName" SG_ 1113 ClmCtlRrBlw2CtlCktFlrSts "Climate Control Rear Blower 2 Control Circuit Information : Climate Control Rear Blower 2 Control Circuit Failure Status";
BA_ "SignalType" SG_ 1113 DuctAirTempRrVntRwVltgDatRxd "ENM";
BA_ "SignalLongName" SG_ 1113 DuctAirTempRrVntRwVltgDatRxd "Duct Air Temperature Rear Vent Raw Voltage Data Received";
BA_ "SignalType" SG_ 1113 DuctAirTempRrRtVntRwVltgDatRxd "ENM";
BA_ "SignalLongName" SG_ 1113 DuctAirTempRrRtVntRwVltgDatRxd "Duct Air Temperature Rear Right Vent Raw Voltage Data Received";
BA_ "SignalType" SG_ 1113 DuctAirTempRrRtFloorRwVltDatRxd "ENM";
BA_ "SignalLongName" SG_ 1113 DuctAirTempRrRtFloorRwVltDatRxd "Duct Air Temperature Rear Right Floor Raw Voltage Data Received";
BA_ "SignalType" SG_ 1113 DuctAirTempRrFloorRwVltgDatRxd "ENM";
BA_ "SignalLongName" SG_ 1113 DuctAirTempRrFloorRwVltgDatRxd "Duct Air Temperature Rear Floor Raw Voltage Data Received";
BA_ "SignalType" SG_ 1113 ClmCtlRrBlwCtlCktOORHiFlrSts "ENM";
BA_ "SignalLongName" SG_ 1113 ClmCtlRrBlwCtlCktOORHiFlrSts "Climate Control Rear Blower Control Circuit Information : Climate Control Rear Blower Control Circuit Out of Range High Failure Status";
BA_ "SignalType" SG_ 1113 ClmCtlRrBlwCtlCktFlrSts "ENM";
BA_ "SignalLongName" SG_ 1113 ClmCtlRrBlwCtlCktFlrSts "Climate Control Rear Blower Control Circuit Information : Climate Control Rear Blower Control Circuit Failure Status";
BA_ "SignalType" SG_ 1113 ClmCtlRrBlw2CtlCktStsDatRxd "ENM";
BA_ "SignalLongName" SG_ 1113 ClmCtlRrBlw2CtlCktStsDatRxd "Climate Control Rear Blower 2 Control Circuit Information : Climate Control Rear Blower 2 Control Circuit Status Data Received";
BA_ "SignalType" SG_ 1113 ClmCtlRrBlw2CtlCktOORLoFlrSts "ENM";
BA_ "SignalLongName" SG_ 1113 ClmCtlRrBlw2CtlCktOORLoFlrSts "Climate Control Rear Blower 2 Control Circuit Information : Climate Control Rear Blower 2 Control Circuit Out of Range Low Failure Status";
BA_ "SignalType" SG_ 1113 InfoThmSeltnExpdCurrSetVal "ENM";
BA_ "SignalLongName" SG_ 1113 InfoThmSeltnExpdCurrSetVal "Infotainment Theme Selection Expanded Current Setting Value";
BA_ "SignalType" SG_ 1113 ClmCtlRrBlwCtlCktStsDatRxd "ENM";
BA_ "SignalLongName" SG_ 1113 ClmCtlRrBlwCtlCktStsDatRxd "Climate Control Rear Blower Control Circuit Information : Climate Control Rear Blower Control Circuit Status Data Received";
BA_ "SignalType" SG_ 1113 ClmCtlRrBlwCtlCktOORLoFlrSts "ENM";
BA_ "SignalLongName" SG_ 1113 ClmCtlRrBlwCtlCktOORLoFlrSts "Climate Control Rear Blower Control Circuit Information : Climate Control Rear Blower Control Circuit Out of Range Low Failure Status";
BA_ "SignalType" SG_ 1113 OccptLtBehindRmndrCstChgSetReq "ENM";
BA_ "SignalLongName" SG_ 1113 OccptLtBehindRmndrCstChgSetReq "Occupant Left Behind Reminder Customization Change Setting Request";
VAL_ 733 TlLmpAuxLftOtg 0 "FALSE" 1 "TRUE" ;
VAL_ 733 RvrsLmpLtActv 0 "FALSE" 1 "TRUE" ;
VAL_ 733 PrkLmpRtOtg 0 "FALSE" 1 "TRUE" ;
VAL_ 733 PrkLmpLftOtg 0 "FALSE" 1 "TRUE" ;
VAL_ 733 PrkLmpAuxRtOtg 0 "FALSE" 1 "TRUE" ;
VAL_ 733 PrkLmpAuxLftOtg 0 "FALSE" 1 "TRUE" ;
VAL_ 733 BLS_BrkLmpRtActv 0 "FALSE" 1 "TRUE" ;
VAL_ 733 BLS_BrkLmpLtActv 0 "FALSE" 1 "TRUE" ;
VAL_ 733 TlLmpRtOtg 0 "FALSE" 1 "TRUE" ;
VAL_ 733 TlLmpLftOtg 0 "FALSE" 1 "TRUE" ;
VAL_ 733 TlLmpAuxRtOtg 0 "FALSE" 1 "TRUE" ;
VAL_ 734 BGI5_TrnLmpRtFncActv 0 "FALSE" 1 "TRUE" ;
VAL_ 734 BGI5_TrnLmpLtFncActv 0 "FALSE" 1 "TRUE" ;
VAL_ 1154 ChmPrdcrQdrntRRSOH 0 "Unknown" 1 "Healthy" 2 "Faulted" ;
VAL_ 1154 ChmPrdcrQdrntRFSOH 0 "Unknown" 1 "Healthy" 2 "Faulted" ;
VAL_ 1154 ChmPrdcrQdrntLRSOH 0 "Unknown" 1 "Healthy" 2 "Faulted" ;
VAL_ 1154 ChmPrdcrQdrntLFSOH 0 "Unknown" 1 "Healthy" 2 "Faulted" ;
VAL_ 1913 InfoHtdFrtWshldSetChgReqd 0 "FALSE" 1 "TRUE" ;
VAL_ 1913 InfoHtdFrtWshldSet 0 "No Action" 1 "HFWS_Off" 2 "HFWS_On" 3 "Auto" ;
VAL_ 229 DrvModeConfDrvrResp 0 "No Indication" 1 "Baja ESC Confirm" 2 "Baja ESC Cancel" 3 "Terrain ESC Confirm" 4 "Terrain ESC Cancel" 5 "Response 5" 6 "Response 6" 7 "Response 7" 8 "Response 8" 9 "Response 9" 10 "Response 10" 11 "Response 11" 12 "Response 12" 13 "Response 13" 14 "Response 14" 15 "Response 15" ;
VAL_ 537 MaxPwrModeConfDrvrResp 0 "No Indication" 1 "Max Power Confirm" 2 "Max Power Cancel" 3 "Response 3" 4 "Response 4" 5 "Response 5" 6 "Response 6" 7 "Response 7" ;
VAL_ 1304 HVACICRMcrClmStSyncRrRt 0 "FALSE" 1 "TRUE" ;
VAL_ 1304 HVACICRMcrClmStSyncRrLt 0 "FALSE" 1 "TRUE" ;
VAL_ 1304 HVACICRMcrClmStSyncFrtRt 0 "FALSE" 1 "TRUE" ;
VAL_ 1304 HVACICRMcrClmStSyncFrtLt 0 "FALSE" 1 "TRUE" ;
VAL_ 1304 HVACICRNckScrfLvlRrLt 0 "Off" 1 "1" 2 "2" 3 "3" ;
VAL_ 1304 HVACICRNckScrfLvlFrtRt 0 "Off" 1 "1" 2 "2" 3 "3" ;
VAL_ 1304 HVACICRNckScrfLvlFrtLt 0 "Off" 1 "1" 2 "2" 3 "3" ;
VAL_ 1304 HVACICRFrtRtAutoSetChg 0 "FALSE" 1 "TRUE" ;
VAL_ 1304 HVACICRBlwLvlRrRtActv 0 "FALSE" 1 "TRUE" ;
VAL_ 1304 HVACICRBlwLvlFrtRtActv 0 "FALSE" 1 "TRUE" ;
VAL_ 1304 HVACICRNckScrfLvlRrRt 0 "Off" 1 "1" 2 "2" 3 "3" ;
VAL_ 1304 HVACICRRrRtAutoSetChg 0 "FALSE" 1 "TRUE" ;
VAL_ 1304 HVACICRNckScrfLvlRrRtActv 0 "FALSE" 1 "TRUE" ;
VAL_ 1304 HVACICRNckScrfLvlRrLtActv 0 "FALSE" 1 "TRUE" ;
VAL_ 1304 HVACICRNckScrfLvlFrtRtActv 0 "FALSE" 1 "TRUE" ;
VAL_ 1304 HVACICRNckScrfLvlFrtLtActv 0 "FALSE" 1 "TRUE" ;
VAL_ 1445 SCAPwrDrMtnRRVirtCtlAval 0 "Not Available" 1 "Available" ;
VAL_ 1445 SCAPwrDrMtnLRVirtCtlAval 0 "Not Available" 1 "Available" ;
VAL_ 521 AckCod 0 "FALSE" 1 "TRUE" ;
VAL_ 521 AckFlrRsn 0 "Success" 1 "General Login Error" 2 "Login Error With Data Missing" 3 "Live Data Missing" 4 "Supplemental Data Missing" 5 "Reserved 0x05" 6 "Reserved 0x06" 7 "Reserved 0x07" 8 "Reserved 0x08" 9 "Reserved 0x09" 10 "Reserved 0x0A" 11 "Reserved 0x0B" 12 "Reserved 0x0C" 13 "Reserved 0x0D" 14 "Reserved 0x0E" 15 "Reserved 0x0F" 16 "Reserved 0x10" 17 "Reserved 0x11" 18 "Reserved 0x12" 19 "Reserved 0x13" 20 "Reserved 0x14" 21 "Reserved 0x15" 22 "Reserved 0x16" 23 "Reserved 0x17" 24 "Reserved 0x18" 25 "Reserved 0x19" 26 "Reserved 0x1A" 27 "Reserved 0x1B" 28 "Reserved 0x1C" 29 "Reserved 0x1D" 30 "Reserved 0x1E" 31 "Reserved 0x1F" 32 "Reserved 0x20" 33 "Reserved 0x21" 34 "Reserved 0x22" 35 "Reserved 0x23" 36 "Reserved 0x24" 37 "Reserved 0x25" 38 "Reserved 0x26" 39 "Reserved 0x27" 40 "Reserved 0x28" 41 "Reserved 0x29" 42 "Reserved 0x2A" 43 "Reserved 0x2B" 44 "Reserved 0x2C" 45 "Reserved 0x2D" 46 "Reserved 0x2E" 47 "Reserved 0x2F" 48 "Reserved 0x30" 49 "Reserved 0x31" 50 "Reserved 0x32" 51 "Reserved 0x33" 52 "Reserved 0x34" 53 "Reserved 0x35" 54 "Reserved 0x36" 55 "Reserved 0x37" 56 "Reserved 0x38" 57 "Reserved 0x39" 58 "Reserved 0x3A" 59 "Reserved 0x3B" 60 "Reserved 0x3C" 61 "Reserved 0x3D" 62 "Reserved 0x3E" 63 "Reserved 0x3F" 64 "Reserved 0x40" 65 "Reserved 0x41" 66 "Reserved 0x42" 67 "Reserved 0x43" 68 "Reserved 0x44" 69 "Reserved 0x45" 70 "Reserved 0x46" 71 "Reserved 0x47" 72 "Reserved 0x48" 73 "Reserved 0x49" 74 "Reserved 0x4A" 75 "Reserved 0x4B" 76 "Reserved 0x4C" 77 "Reserved 0x4D" 78 "Reserved 0x4E" 79 "Reserved 0x4F" 80 "Reserved 0x50" 81 "Reserved 0x51" 82 "Reserved 0x52" 83 "Reserved 0x53" 84 "Reserved 0x54" 85 "Reserved 0x55" 86 "Reserved 0x56" 87 "Reserved 0x57" 88 "Reserved 0x58" 89 "Reserved 0x59" 90 "Reserved 0x5A" 91 "Reserved 0x5B" 92 "Reserved 0x5C" 93 "Reserved 0x5D" 94 "Reserved 0x5E" 95 "Reserved 0x5F" 96 "Reserved 0x60" 97 "Reserved 0x61" 98 "Reserved 0x62" 99 "Reserved 0x63" 100 "Reserved 0x64" 101 "Reserved 0x65" 102 "Reserved 0x66" 103 "Reserved 0x67" 104 "Reserved 0x68" 105 "Reserved 0x69" 106 "Reserved 0x6A" 107 "Reserved 0x6B" 108 "Reserved 0x6C" 109 "Reserved 0x6D" 110 "Reserved 0x6E" 111 "Reserved 0x6F" 112 "Reserved 0x70" 113 "Reserved 0x71" 114 "Reserved 0x72" 115 "Reserved 0x73" 116 "Reserved 0x74" 117 "Reserved 0x75" 118 "Reserved 0x76" 119 "Reserved 0x77" 120 "Reserved 0x78" 121 "Reserved 0x79" 122 "Reserved 0x7A" 123 "Reserved 0x7B" 124 "Reserved 0x7C" 125 "Reserved 0x7D" 126 "Reserved 0x7E" 127 "Reserved 0x7F" 128 "Reserved 0x80" 129 "Reserved 0x81" 130 "Reserved 0x82" 131 "Reserved 0x83" 132 "Reserved 0x84" 133 "Reserved 0x85" 134 "Reserved 0x86" 135 "Reserved 0x87" 136 "Reserved 0x88" 137 "Reserved 0x89" 138 "Reserved 0x8A" 139 "Reserved 0x8B" 140 "Reserved 0x8C" 141 "Reserved 0x8D" 142 "Reserved 0x8E" 143 "Reserved 0x8F" 144 "Reserved 0x90" 145 "Live Data Check Error" 146 "Supplemental Data Check Error" 147 "General TCP Data Manager Failure" 148 "Reserved 0x94" 149 "Reserved 0x95" 150 "Reserved 0x96" 151 "Reserved 0x97" 152 "Reserved 0x98" 153 "Reserved 0x99" 154 "Reserved 0x9A" 155 "Reserved 0x9B" 156 "Reserved 0x9C" 157 "Reserved 0x9D" 158 "Reserved 0x9E" 159 "Reserved 0x9F" 160 "Reserved 0xA0" 161 "Reserved 0xA1" 162 "Reserved 0xA2" 163 "Reserved 0xA3" 164 "Reserved 0xA4" 165 "Reserved 0xA5" 166 "Reserved 0xA6" 167 "Reserved 0xA7" 168 "Reserved 0xA8" 169 "Reserved 0xA9" 170 "Reserved 0xAA" 171 "Reserved 0xAB" 172 "Reserved 0xAC" 173 "Reserved 0xAD" 174 "Reserved 0xAE" 175 "Reserved 0xAF" 176 "Reserved 0xB0" 177 "Reserved 0xB1" 178 "Reserved 0xB2" 179 "Reserved 0xB3" 180 "Reserved 0xB4" 181 "Reserved 0xB5" 182 "Reserved 0xB6" 183 "Reserved 0xB7" 184 "Reserved 0xB8" 185 "Reserved 0xB9" 186 "Reserved 0xBA" 187 "Reserved 0xBB" 188 "Reserved 0xBC" 189 "Reserved 0xBD" 190 "Reserved 0xBE" 191 "Reserved 0xBF" 192 "Reserved 0xC0" 193 "Reserved 0xC1" 194 "Reserved 0xC2" 195 "Reserved 0xC3" 196 "Reserved 0xC4" 197 "Reserved 0xC5" 198 "Reserved 0xC6" 199 "Reserved 0xC7" 200 "Reserved 0xC8" 201 "Reserved 0xC9" 202 "Reserved 0xCA" 203 "Reserved 0xCB" 204 "Reserved 0xCC" 205 "Reserved 0xCD" 206 "Reserved 0xCE" 207 "Reserved 0xCF" 208 "Reserved 0xD0" 209 "Reserved 0xD1" 210 "Reserved 0xD2" 211 "Reserved 0xD3" 212 "Reserved 0xD4" 213 "Reserved 0xD5" 214 "Reserved 0xD6" 215 "Reserved 0xD7" 216 "Reserved 0xD8" 217 "Reserved 0xD9" 218 "Reserved 0xDA" 219 "Reserved 0xDB" 220 "Reserved 0xDC" 221 "Reserved 0xDD" 222 "Reserved 0xDE" 223 "Reserved 0xDF" 224 "Reserved 0xE0" 225 "Reserved 0xE1" 226 "Reserved 0xE2" 227 "Reserved 0xE3" 228 "Reserved 0xE4" 229 "Reserved 0xE5" 230 "Reserved 0xE6" 231 "Reserved 0xE7" 232 "Reserved 0xE8" 233 "Reserved 0xE9" 234 "Reserved 0xEA" 235 "Reserved 0xEB" 236 "Reserved 0xEC" 237 "Reserved 0xED" 238 "Reserved 0xEE" 239 "Reserved 0xEF" 240 "Reserved 0xF0" 241 "Reserved 0xF1" 242 "Reserved 0xF2" 243 "Reserved 0xF3" 244 "Reserved 0xF4" 245 "Reserved 0xF5" 246 "Reserved 0xF6" 247 "Reserved 0xF7" 248 "Reserved 0xF8" 249 "Reserved 0xF9" 250 "Reserved 0xFA" 251 "Reserved 0xFB" 252 "Reserved 0xFC" 253 "Reserved 0xFD" 254 "Reserved 0xFE" 255 "Reserved 0xFF" ;
VAL_ 1910 IntrAmbtColrCtlCstAvlFlg34 0 "FALSE" 1 "TRUE" ;
VAL_ 1910 IntrAmbtColrCtlCstAvlFlg33 0 "FALSE" 1 "TRUE" ;
VAL_ 1910 IntrAmbtColrCtlCstAvlFlg32 0 "FALSE" 1 "TRUE" ;
VAL_ 1910 IntrAmbtColrCtlCstAvlFlg42 0 "FALSE" 1 "TRUE" ;
VAL_ 1910 IntrAmbtColrCtlCstAvlFlg41 0 "FALSE" 1 "TRUE" ;
VAL_ 1910 IntrAmbtColrCtlCstAvlFlg40 0 "FALSE" 1 "TRUE" ;
VAL_ 1910 IntrAmbtColrCtlCstAvlFlg39 0 "FALSE" 1 "TRUE" ;
VAL_ 1910 IntrAmbtColrCtlCstAvlFlg38 0 "FALSE" 1 "TRUE" ;
VAL_ 1910 IntrAmbtColrCtlCstAvlFlg37 0 "FALSE" 1 "TRUE" ;
VAL_ 1910 IntrAmbtColrCtlCstAvlFlg36 0 "FALSE" 1 "TRUE" ;
VAL_ 1910 IntrAmbtColrCtlCstAvlFlg35 0 "FALSE" 1 "TRUE" ;
VAL_ 1910 IntrAmbtColrCtlCstAvlFlg50 0 "FALSE" 1 "TRUE" ;
VAL_ 1910 IntrAmbtColrCtlCstAvlFlg49 0 "FALSE" 1 "TRUE" ;
VAL_ 1910 IntrAmbtColrCtlCstAvlFlg48 0 "FALSE" 1 "TRUE" ;
VAL_ 1910 IntrAmbtColrCtlCstAvlFlg47 0 "FALSE" 1 "TRUE" ;
VAL_ 1910 IntrAmbtColrCtlCstAvlFlg46 0 "FALSE" 1 "TRUE" ;
VAL_ 1910 IntrAmbtColrCtlCstAvlFlg45 0 "FALSE" 1 "TRUE" ;
VAL_ 1910 IntrAmbtColrCtlCstAvlFlg44 0 "FALSE" 1 "TRUE" ;
VAL_ 1910 IntrAmbtColrCtlCstAvlFlg43 0 "FALSE" 1 "TRUE" ;
VAL_ 1910 IntrAmbtColrCtlCstAvlFlg58 0 "FALSE" 1 "TRUE" ;
VAL_ 1910 IntrAmbtColrCtlCstAvlFlg57 0 "FALSE" 1 "TRUE" ;
VAL_ 1910 IntrAmbtColrCtlCstAvlFlg56 0 "FALSE" 1 "TRUE" ;
VAL_ 1910 IntrAmbtColrCtlCstAvlFlg55 0 "FALSE" 1 "TRUE" ;
VAL_ 1910 IntrAmbtColrCtlCstAvlFlg54 0 "FALSE" 1 "TRUE" ;
VAL_ 1910 IntrAmbtColrCtlCstAvlFlg53 0 "FALSE" 1 "TRUE" ;
VAL_ 1910 IntrAmbtColrCtlCstAvlFlg52 0 "FALSE" 1 "TRUE" ;
VAL_ 1910 IntrAmbtColrCtlCstAvlFlg51 0 "FALSE" 1 "TRUE" ;
VAL_ 1910 IntrAmbtColrCtlCstAvlFlg66 0 "FALSE" 1 "TRUE" ;
VAL_ 1910 IntrAmbtColrCtlCstAvlFlg65 0 "FALSE" 1 "TRUE" ;
VAL_ 1910 IntrAmbtColrCtlCstAvlFlg64 0 "FALSE" 1 "TRUE" ;
VAL_ 1910 IntrAmbtColrCtlCstAvlFlg63 0 "FALSE" 1 "TRUE" ;
VAL_ 1910 IntrAmbtColrCtlCstAvlFlg62 0 "FALSE" 1 "TRUE" ;
VAL_ 1910 IntrAmbtColrCtlCstAvlFlg61 0 "FALSE" 1 "TRUE" ;
VAL_ 1910 IntrAmbtColrCtlCstAvlFlg60 0 "FALSE" 1 "TRUE" ;
VAL_ 1910 IntrAmbtColrCtlCstAvlFlg59 0 "FALSE" 1 "TRUE" ;
VAL_ 1910 IntrAmbtColrCtlCstAvlFlg74 0 "FALSE" 1 "TRUE" ;
VAL_ 1910 IntrAmbtColrCtlCstAvlFlg73 0 "FALSE" 1 "TRUE" ;
VAL_ 1910 IntrAmbtColrCtlCstAvlFlg72 0 "FALSE" 1 "TRUE" ;
VAL_ 1910 IntrAmbtColrCtlCstAvlFlg71 0 "FALSE" 1 "TRUE" ;
VAL_ 1910 IntrAmbtColrCtlCstAvlFlg70 0 "FALSE" 1 "TRUE" ;
VAL_ 1910 IntrAmbtColrCtlCstAvlFlg69 0 "FALSE" 1 "TRUE" ;
VAL_ 1910 IntrAmbtColrCtlCstAvlFlg68 0 "FALSE" 1 "TRUE" ;
VAL_ 1910 IntrAmbtColrCtlCstAvlFlg67 0 "FALSE" 1 "TRUE" ;
VAL_ 1910 IntrAmbtColrCtlCstAvlFlg82 0 "FALSE" 1 "TRUE" ;
VAL_ 1910 IntrAmbtColrCtlCstAvlFlg81 0 "FALSE" 1 "TRUE" ;
VAL_ 1910 IntrAmbtColrCtlCstAvlFlg80 0 "FALSE" 1 "TRUE" ;
VAL_ 1910 IntrAmbtColrCtlCstAvlFlg79 0 "FALSE" 1 "TRUE" ;
VAL_ 1910 IntrAmbtColrCtlCstAvlFlg78 0 "FALSE" 1 "TRUE" ;
VAL_ 1910 IntrAmbtColrCtlCstAvlFlg77 0 "FALSE" 1 "TRUE" ;
VAL_ 1910 IntrAmbtColrCtlCstAvlFlg76 0 "FALSE" 1 "TRUE" ;
VAL_ 1910 IntrAmbtColrCtlCstAvlFlg75 0 "FALSE" 1 "TRUE" ;
VAL_ 1912 IntrAmbtColrCtlCstAvlFlg107 0 "FALSE" 1 "TRUE" ;
VAL_ 1912 IntrAmbtColrCtlCstAvlFlg106 0 "FALSE" 1 "TRUE" ;
VAL_ 1912 IntrAmbtColrCtlCstAvlFlg105 0 "FALSE" 1 "TRUE" ;
VAL_ 1912 IntrAmbtColrCtlCstAvlFlg104 0 "FALSE" 1 "TRUE" ;
VAL_ 1912 IntrAmbtColrCtlCstAvlFlg103 0 "FALSE" 1 "TRUE" ;
VAL_ 1912 IntrAmbtColrCtlCstAvlFlg102 0 "FALSE" 1 "TRUE" ;
VAL_ 1912 IntrAmbtColrCtlCstAvlFlg101 0 "FALSE" 1 "TRUE" ;
VAL_ 1912 IntrAmbtColrCtlCstAvlFlg100 0 "FALSE" 1 "TRUE" ;
VAL_ 1912 IntrAmbtColrCtlCstAvlFlg115 0 "FALSE" 1 "TRUE" ;
VAL_ 1912 IntrAmbtColrCtlCstAvlFlg114 0 "FALSE" 1 "TRUE" ;
VAL_ 1912 IntrAmbtColrCtlCstAvlFlg113 0 "FALSE" 1 "TRUE" ;
VAL_ 1912 IntrAmbtColrCtlCstAvlFlg112 0 "FALSE" 1 "TRUE" ;
VAL_ 1912 IntrAmbtColrCtlCstAvlFlg111 0 "FALSE" 1 "TRUE" ;
VAL_ 1912 IntrAmbtColrCtlCstAvlFlg110 0 "FALSE" 1 "TRUE" ;
VAL_ 1912 IntrAmbtColrCtlCstAvlFlg109 0 "FALSE" 1 "TRUE" ;
VAL_ 1912 IntrAmbtColrCtlCstAvlFlg108 0 "FALSE" 1 "TRUE" ;
VAL_ 1912 IntrAmbtColrCtlCstAvlFlg123 0 "FALSE" 1 "TRUE" ;
VAL_ 1912 IntrAmbtColrCtlCstAvlFlg122 0 "FALSE" 1 "TRUE" ;
VAL_ 1912 IntrAmbtColrCtlCstAvlFlg121 0 "FALSE" 1 "TRUE" ;
VAL_ 1912 IntrAmbtColrCtlCstAvlFlg120 0 "FALSE" 1 "TRUE" ;
VAL_ 1912 IntrAmbtColrCtlCstAvlFlg119 0 "FALSE" 1 "TRUE" ;
VAL_ 1912 IntrAmbtColrCtlCstAvlFlg118 0 "FALSE" 1 "TRUE" ;
VAL_ 1912 IntrAmbtColrCtlCstAvlFlg117 0 "FALSE" 1 "TRUE" ;
VAL_ 1912 IntrAmbtColrCtlCstAvlFlg116 0 "FALSE" 1 "TRUE" ;
VAL_ 1912 IntrAmbtColrCtlCstAvlFlg86 0 "FALSE" 1 "TRUE" ;
VAL_ 1912 IntrAmbtColrCtlCstAvlFlg85 0 "FALSE" 1 "TRUE" ;
VAL_ 1912 IntrAmbtColrCtlCstAvlFlg84 0 "FALSE" 1 "TRUE" ;
VAL_ 1912 IntrAmbtColrCtlCstAvlFlg83 0 "FALSE" 1 "TRUE" ;
VAL_ 1912 IntrAmbtColrCtlCstAvlFlg127 0 "FALSE" 1 "TRUE" ;
VAL_ 1912 IntrAmbtColrCtlCstAvlFlg126 0 "FALSE" 1 "TRUE" ;
VAL_ 1912 IntrAmbtColrCtlCstAvlFlg125 0 "FALSE" 1 "TRUE" ;
VAL_ 1912 IntrAmbtColrCtlCstAvlFlg124 0 "FALSE" 1 "TRUE" ;
VAL_ 1912 IntrAmbtColrCtlCstAvlFlg94 0 "FALSE" 1 "TRUE" ;
VAL_ 1912 IntrAmbtColrCtlCstAvlFlg93 0 "FALSE" 1 "TRUE" ;
VAL_ 1912 IntrAmbtColrCtlCstAvlFlg92 0 "FALSE" 1 "TRUE" ;
VAL_ 1912 IntrAmbtColrCtlCstAvlFlg91 0 "FALSE" 1 "TRUE" ;
VAL_ 1912 IntrAmbtColrCtlCstAvlFlg90 0 "FALSE" 1 "TRUE" ;
VAL_ 1912 IntrAmbtColrCtlCstAvlFlg89 0 "FALSE" 1 "TRUE" ;
VAL_ 1912 IntrAmbtColrCtlCstAvlFlg88 0 "FALSE" 1 "TRUE" ;
VAL_ 1912 IntrAmbtColrCtlCstAvlFlg87 0 "FALSE" 1 "TRUE" ;
VAL_ 1912 ElvtdIdlCstSetAvlFlg2 0 "FALSE" 1 "TRUE" ;
VAL_ 1912 ElvtdIdlCstSetAvlFlg1 0 "FALSE" 1 "TRUE" ;
VAL_ 1912 ElvtdIdlCstSetAval 0 "FALSE" 1 "TRUE" ;
VAL_ 1912 IntrAmbtColrCtlCstAvlFlg99 0 "FALSE" 1 "TRUE" ;
VAL_ 1912 IntrAmbtColrCtlCstAvlFlg98 0 "FALSE" 1 "TRUE" ;
VAL_ 1912 IntrAmbtColrCtlCstAvlFlg97 0 "FALSE" 1 "TRUE" ;
VAL_ 1912 IntrAmbtColrCtlCstAvlFlg96 0 "FALSE" 1 "TRUE" ;
VAL_ 1912 IntrAmbtColrCtlCstAvlFlg95 0 "FALSE" 1 "TRUE" ;
VAL_ 1912 DMSDrwDrvrCstAvlFlg3 0 "FALSE" 1 "TRUE" ;
VAL_ 1912 DMSDrwDrvrCstAvlFlg2 0 "FALSE" 1 "TRUE" ;
VAL_ 1912 DMSDrwDrvrCstAvlFlg1 0 "FALSE" 1 "TRUE" ;
VAL_ 1912 ElvtdIdlCstSetAvlFlg7 0 "FALSE" 1 "TRUE" ;
VAL_ 1912 ElvtdIdlCstSetAvlFlg6 0 "FALSE" 1 "TRUE" ;
VAL_ 1912 ElvtdIdlCstSetAvlFlg5 0 "FALSE" 1 "TRUE" ;
VAL_ 1912 ElvtdIdlCstSetAvlFlg4 0 "FALSE" 1 "TRUE" ;
VAL_ 1912 ElvtdIdlCstSetAvlFlg3 0 "FALSE" 1 "TRUE" ;
VAL_ 1912 VehSpdAcurLvl 0 "Unknown" 1 "Two and Half Percent" 2 "One Percent" ;
VAL_ 1912 DMSDrwDrvrCstSetAval 0 "FALSE" 1 "TRUE" ;
VAL_ 1912 DMSDrwDrvrCstAvlFlg7 0 "FALSE" 1 "TRUE" ;
VAL_ 1912 DMSDrwDrvrCstAvlFlg6 0 "FALSE" 1 "TRUE" ;
VAL_ 1912 DMSDrwDrvrCstAvlFlg5 0 "FALSE" 1 "TRUE" ;
VAL_ 1912 DMSDrwDrvrCstAvlFlg4 0 "FALSE" 1 "TRUE" ;
VAL_ 1915 ExtAudSOH 0 "Unknown" 1 "Partial Loss" 2 "Full Loss" 3 "No Faults Detected" ;
VAL_ 1915 ExtDispSOH 0 "Unknown" 1 "Partial Loss" 2 "Full Loss" 3 "No Faults Detected" ;
VAL_ 1915 EmrgCallAudSOH 0 "Unknown" 1 "Partial Loss" 2 "Full Loss" 3 "No Faults Detected" ;
VAL_ 1915 CbnAudSOH 0 "Unknown" 1 "Partial Loss" 2 "Full Loss" 3 "No Faults Detected" ;
VAL_ 1916 AmpSOHAEDSPModeCurrStat 0 "No Action" 1 "DSP Mode 0" 2 "DSP Mode 1" 3 "DSP Mode 2" 4 "DSP Mode 3" 5 "DSP Mode 4" 6 "DSP Mode 5" 7 "DSP Mode 6" 8 "DSP Mode 7" ;
VAL_ 1916 AmpSOHAEVehNoisCmpnAtv 0 "FALSE" 1 "TRUE" ;
VAL_ 735 InfoPsngSysLng_Inv 0 "FALSE" 1 "TRUE" ;
VAL_ 735 InfoPsngSysLat_Inv 0 "FALSE" 1 "TRUE" ;
VAL_ 1134 StHtdCushLvlLFSet 0 "Off" 1 "Low" 2 "Medium" 3 "High" ;
VAL_ 1134 StHtdBkLvlLFSet 0 "Off" 1 "Low" 2 "Medium" 3 "High" ;
VAL_ 1134 StHtdCushLvlLRSet 0 "Off" 1 "Low" 2 "Medium" 3 "High" ;
VAL_ 1134 StHtdBkLvlLRSet 0 "Off" 1 "Low" 2 "Medium" 3 "High" ;
VAL_ 1134 StVntdCoolCushLvlLFSet 0 "Off" 1 "Low" 2 "Medium" 3 "High" ;
VAL_ 1134 StVntdCoolBkLvlLFSet 0 "Off" 1 "Low" 2 "Medium" 3 "High" ;
VAL_ 1134 StHtdCushLvlRFSet 0 "Off" 1 "Low" 2 "Medium" 3 "High" ;
VAL_ 1134 StHtdBkLvlRFSet 0 "Off" 1 "Low" 2 "Medium" 3 "High" ;
VAL_ 1134 StVntdCoolCushLvlLRSet 0 "Off" 1 "Low" 2 "Medium" 3 "High" ;
VAL_ 1134 StVntdCoolBkLvlLRSet 0 "Off" 1 "Low" 2 "Medium" 3 "High" ;
VAL_ 1134 RrDrOpnCmfRclCstSetVal 0 "Setting Unknown" 1 "Off" 2 "On" ;
VAL_ 1134 StVntdCoolCushLvlRFSet 0 "Off" 1 "Low" 2 "Medium" 3 "High" ;
VAL_ 1134 StVntdCoolBkLvlRFSet 0 "Off" 1 "Low" 2 "Medium" 3 "High" ;
VAL_ 1933 StBkHrztlLRVirtCtlAllwd 0 "Not Allowed" 1 "Allowed" ;
VAL_ 1933 StCushSdBolsLRVirtCtlAllwd 0 "Not Allowed" 1 "Allowed" ;
VAL_ 1933 StCushRrVertLRVirtCtlAllwd 0 "Not Allowed" 1 "Allowed" ;
VAL_ 1933 StCushLgthHrztlLRVirtCtlAllwd 0 "Not Allowed" 1 "Allowed" ;
VAL_ 1933 StCushHrztlLRVirtCtlAllwd 0 "Not Allowed" 1 "Allowed" ;
VAL_ 1933 StCushFrtVertLRVirtCtlAllwd 0 "Not Allowed" 1 "Allowed" ;
VAL_ 1933 StBkSdBolsLRVirtCtlAllwd 0 "Not Allowed" 1 "Allowed" ;
VAL_ 1933 StBkLumbVertLRVirtCtlAllwd 0 "Not Allowed" 1 "Allowed" ;
VAL_ 1933 StBkLumbHrztlLRVirtCtlAllwd 0 "Not Allowed" 1 "Allowed" ;
VAL_ 1933 StUpprShldrHrztlLRVirtCtlAllwd 0 "Not Allowed" 1 "Allowed" ;
VAL_ 1933 StMasgLRVirtCtlAllwd 0 "Not Allowed" 1 "Allowed" ;
VAL_ 1933 StHdrstVertLRVirtCtlAllwd 0 "Not Allowed" 1 "Allowed" ;
VAL_ 1933 StHdrstHrztlLRVirtCtlAllwd 0 "Not Allowed" 1 "Allowed" ;
VAL_ 1933 StMasgIntstyLRLstKnwnSet 0 "Massage Off" 1 "Intensity 1" 2 "Intensity 2" 3 "Intensity 3" 4 "Intensity 4" 5 "Intensity 5" 6 "Intensity 6" 7 "Intensity 7" ;
VAL_ 1933 StMasgTypLRLstKnwnSet 0 "Massage Off" 1 "Type 1" 2 "Type 2" 3 "Type 3" 4 "Type 4" 5 "Type 5" 6 "Type 6" 7 "Type 7" 8 "Type 8" 9 "Type 9" 10 "Type 10" 11 "Type 11" 12 "Type 12" 13 "Type 13" 14 "Type 14" 15 "Type 15" ;
VAL_ 1131 SuprRmtPrkFcsStsVCU 0 "No Focus" 1 "Focus" ;
VAL_ 1133 HVACICROtltFrtRtOtbdArflQnty 0 "0" 1 "25" 2 "50" 3 "75" 4 "100" ;
VAL_ 1133 HVACICROtltFrtRtInbdArflQnty 0 "0" 1 "25" 2 "50" 3 "75" 4 "100" ;
VAL_ 1133 HVACICROtltFrtRtStat 0 "Manual" 1 "Auto" 2 "Focused" 3 "Diffused" ;
VAL_ 1133 HVACICROscMdFrtRtSet 0 "No Action" 1 "Left Right Only" 2 "Up Down Only" 3 "Left Right Up Down" ;
VAL_ 1133 HVACICRHVACPwrFrtRtChg 0 "FALSE" 1 "TRUE" ;
VAL_ 1133 HVACICRCkMdOn 0 "FALSE" 1 "TRUE" ;
VAL_ 1133 HVACICRHVACPwrRrLtChg 0 "FALSE" 1 "TRUE" ;
VAL_ 1133 HVACICROtltRrLtStat 0 "Manual" 1 "Auto" 2 "Focused" 3 "Diffused" ;
VAL_ 1133 HVACICROscMdRrLtSet 0 "No Action" 1 "Left Right Only" 2 "Up Down Only" 3 "Left Right Up Down" ;
VAL_ 1934 HVACICROtltFrtLtOtbdArflQnty 0 "0" 1 "25" 2 "50" 3 "75" 4 "100" ;
VAL_ 1934 HVACICROtltFrtLtInbdArflQnty 0 "0" 1 "25" 2 "50" 3 "75" 4 "100" ;
VAL_ 1934 HVACICROtltFrtLtStat 0 "Manual" 1 "Auto" 2 "Focused" 3 "Diffused" ;
VAL_ 1934 HVACICROscMdFrtLtSet 0 "No Action" 1 "Left Right Only" 2 "Up Down Only" 3 "Left Right Up Down" ;
VAL_ 1934 HVACICRHVACPwrFrtLtChg 0 "FALSE" 1 "TRUE" ;
VAL_ 1934 HVACICROscMdRrRtSet 0 "No Action" 1 "Left Right Only" 2 "Up Down Only" 3 "Left Right Up Down" ;
VAL_ 1934 HVACICRHVACPwrRrRtChg 0 "FALSE" 1 "TRUE" ;
VAL_ 1934 HVACICROtltRrRtStat 0 "Manual" 1 "Auto" 2 "Focused" 3 "Diffused" ;
VAL_ 1341 HVACICFRFrtBlwCkt1InvDatDtd 0 "FALSE" 1 "TRUE" ;
VAL_ 1341 HVACICFRFrtBlwCkt1DatRxd 0 "FALSE" 1 "TRUE" ;
VAL_ 1339 HVACICFRFrtBlwCkt2InvDatDtd 0 "FALSE" 1 "TRUE" ;
VAL_ 1339 HVACICFRFrtBlwCkt2DatRxd 0 "FALSE" 1 "TRUE" ;
VAL_ 1337 HVACICFRFrtLtTempCkt1InvDatDtd 0 "FALSE" 1 "TRUE" ;
VAL_ 1337 HVACICFRFrtLtTempCkt1DatRxd 0 "FALSE" 1 "TRUE" ;
VAL_ 1144 HVACICFRFrtLtTempCkt2InvDatDtd 0 "FALSE" 1 "TRUE" ;
VAL_ 1144 HVACICFRFrtLtTempCkt2DatRxd 0 "FALSE" 1 "TRUE" ;
VAL_ 1937 HVACICFRFrtLtTempCkt3InvDatDtd 0 "FALSE" 1 "TRUE" ;
VAL_ 1937 HVACICFRFrtLtTempCkt3DatRxd 0 "FALSE" 1 "TRUE" ;
VAL_ 1129 HVACICFRFrtRtTempCkt1InvDatDtd 0 "FALSE" 1 "TRUE" ;
VAL_ 1129 HVACICFRFrtRtTempCkt1DatRxd 0 "FALSE" 1 "TRUE" ;
VAL_ 1938 HVACICFRFrtRtTempCkt2InvDatDtd 0 "FALSE" 1 "TRUE" ;
VAL_ 1938 HVACICFRFrtRtTempCkt2DatRxd 0 "FALSE" 1 "TRUE" ;
VAL_ 1128 HVACICFRFrtRtTempCkt3InvDatDtd 0 "FALSE" 1 "TRUE" ;
VAL_ 1128 HVACICFRFrtRtTempCkt3DatRxd 0 "FALSE" 1 "TRUE" ;
VAL_ 1939 HVACICFRBlwLvlFrtSnsdStat1 0 "Uninitialized" 1 "Released" 2 "Pressed" 3 "Indeterminate" 4 "Out of Range Low" 5 "Out of Range High" ;
VAL_ 1939 HVACICFRTempFrtLtSnsdStat1 0 "Uninitialized" 1 "Released" 2 "Pressed" 3 "Indeterminate" 4 "Out of Range Low" 5 "Out of Range High" ;
VAL_ 1939 HVACICFRBlwLvlFrtSnsdStat2 0 "Uninitialized" 1 "Released" 2 "Pressed" 3 "Indeterminate" 4 "Out of Range Low" 5 "Out of Range High" ;
VAL_ 1939 HVACICFRTempFrtRtSnsdStat2 0 "Uninitialized" 1 "Released" 2 "Pressed" 3 "Indeterminate" 4 "Out of Range Low" 5 "Out of Range High" ;
VAL_ 1939 HVACICFRTempFrtRtSnsdStat1 0 "Uninitialized" 1 "Released" 2 "Pressed" 3 "Indeterminate" 4 "Out of Range Low" 5 "Out of Range High" ;
VAL_ 1939 HVACICFRTempFrtLtSnsdStat2 0 "Uninitialized" 1 "Released" 2 "Pressed" 3 "Indeterminate" 4 "Out of Range Low" 5 "Out of Range High" ;
VAL_ 1939 HVACICFRTempFrtRtCorrSts 0 "Indeterminate" 1 "Pass Criteria Met" 2 "Fail Criteria Met" ;
VAL_ 1939 HVACICFRTempFrtLtCorrSts 0 "Indeterminate" 1 "Pass Criteria Met" 2 "Fail Criteria Met" ;
VAL_ 1939 HVACICFRBlwLvlFrtCorrSts 0 "Indeterminate" 1 "Pass Criteria Met" 2 "Fail Criteria Met" ;
VAL_ 1939 HVACICFRTempFrtRtDatErr 0 "FALSE" 1 "TRUE" ;
VAL_ 1939 HVACICFRTempFrtLtDatErr 0 "FALSE" 1 "TRUE" ;
VAL_ 1939 HVACICFRMsg2InvDatDtd 0 "FALSE" 1 "TRUE" ;
VAL_ 1939 HVACICFRMsg2DatRxd 0 "FALSE" 1 "TRUE" ;
VAL_ 1939 HVACICFRBlwLvlFrtDatErr 0 "FALSE" 1 "TRUE" ;
VAL_ 1127 HVACICFRFrtHVACAutoSnsdStat 0 "Uninitialized" 1 "Released" 2 "Pressed" 3 "Indeterminate" 4 "Out of Range Low" 5 "Out of Range High" ;
VAL_ 1127 HVACICFRFrtDefrSnsdStat 0 "Uninitialized" 1 "Released" 2 "Pressed" 3 "Indeterminate" 4 "Out of Range Low" 5 "Out of Range High" ;
VAL_ 1127 HVACICFRCompSnsdStat 0 "Uninitialized" 1 "Released" 2 "Pressed" 3 "Indeterminate" 4 "Out of Range Low" 5 "Out of Range High" ;
VAL_ 1127 HVACICFRRrDfgSnsdStat 0 "Uninitialized" 1 "Released" 2 "Pressed" 3 "Indeterminate" 4 "Out of Range Low" 5 "Out of Range High" ;
VAL_ 1127 HVACICFRRecircSnsdStat 0 "Uninitialized" 1 "Released" 2 "Pressed" 3 "Indeterminate" 4 "Out of Range Low" 5 "Out of Range High" ;
VAL_ 1127 HVACICFRHtSnsdStat 0 "Uninitialized" 1 "Released" 2 "Pressed" 3 "Indeterminate" 4 "Out of Range Low" 5 "Out of Range High" ;
VAL_ 1127 HVACICFRFrtHVACAutoDatErr 0 "FALSE" 1 "TRUE" ;
VAL_ 1127 HVACICFRFrtDefrDatErr 0 "FALSE" 1 "TRUE" ;
VAL_ 1127 HVACICFRCompSetChg 0 "FALSE" 1 "TRUE" ;
VAL_ 1127 HVACICFRCompDatErr 0 "FALSE" 1 "TRUE" ;
VAL_ 1127 HVACICFRRecircSetChg 0 "FALSE" 1 "TRUE" ;
VAL_ 1127 HVACICFRRecircDatErr 0 "FALSE" 1 "TRUE" ;
VAL_ 1127 HVACICFRMsg1InvDatDtd 0 "FALSE" 1 "TRUE" ;
VAL_ 1127 HVACICFRMsg1DatRxd 0 "FALSE" 1 "TRUE" ;
VAL_ 1127 HVACICFRMaxDefrChg 0 "FALSE" 1 "TRUE" ;
VAL_ 1127 HVACICFRHtSetChg 0 "FALSE" 1 "TRUE" ;
VAL_ 1127 HVACICFRHtDatErr 0 "FALSE" 1 "TRUE" ;
VAL_ 1127 HVACICFRFrtHVACAutoSetChg 0 "FALSE" 1 "TRUE" ;
VAL_ 1127 HVACICFRRrDfgSetChg 0 "FALSE" 1 "TRUE" ;
VAL_ 1127 HVACICFRRrDfgDatErr 0 "FALSE" 1 "TRUE" ;
VAL_ 736 HVACICFRDiag2InvDatDtd 0 "FALSE" 1 "TRUE" ;
VAL_ 736 HVACICFRDiag2DatRxd 0 "FALSE" 1 "TRUE" ;
VAL_ 736 HVACICFRDiag1InvDatDtd 0 "FALSE" 1 "TRUE" ;
VAL_ 736 HVACICFRDiag1DatRxd 0 "FALSE" 1 "TRUE" ;
VAL_ 736 HVACICFRIntrnlCmptErr 0 "Indeterminate" 1 "Pass Criteria Met" 2 "Fail Criteria Met" ;
VAL_ 736 InfoCtlFBTchscrnDiag2InvDatDtd 0 "FALSE" 1 "TRUE" ;
VAL_ 736 InfoCtlFBTchscrnDiag2DatRxd 0 "FALSE" 1 "TRUE" ;
VAL_ 736 InfoCtlFBTchscrnDiag1InvDatDtd 0 "FALSE" 1 "TRUE" ;
VAL_ 736 InfoCtlFBTchscrnDiag1DatRxd 0 "FALSE" 1 "TRUE" ;
VAL_ 736 InfoCtlFBIntrnlCmpErr 0 "Indeterminate" 1 "Pass Criteria Met" 2 "Fail Criteria Met" ;
VAL_ 736 HVACICVRIntrnlCmptErr 0 "Indeterminate" 1 "Pass Criteria Met" 2 "Fail Criteria Met" ;
VAL_ 1942 StVntdCoolCushLvlRRSet 0 "Off" 1 "Low" 2 "Medium" 3 "High" ;
VAL_ 1942 StVntdCoolBkLvlRRSet 0 "Off" 1 "Low" 2 "Medium" 3 "High" ;
VAL_ 1942 StHtdCushLvlRRSet 0 "Off" 1 "Low" 2 "Medium" 3 "High" ;
VAL_ 1942 StHtdBkLvlRRSet 0 "Off" 1 "Low" 2 "Medium" 3 "High" ;
VAL_ 1942 DlvryModeActv 0 "FALSE" 1 "TRUE" ;
VAL_ 1942 RrPedtrnClsnMtgnVisAlrtReq 0 "Off" 1 "Pedestrian Alert" 2 "Pedestrian Notify" ;
VAL_ 1942 RTESTlmDatUpdtIndActv 0 "FALSE" 1 "TRUE" ;
VAL_ 1942 SGI2P_AirSpnsnRdHghtTgtStsAuth 0 "Faulted" 1 "Entry/Exit" 2 "Lowered 3" 3 "Lowered 2" 4 "Lowered 1" 5 "Showroom" 6 "Normal" 7 "Raised 1" 8 "Raised 2" 9 "Raised 3" 10 "Cargo" 11 "Trailer Low" 12 "Trailer High" 13 "Car Show" ;
VAL_ 1124 StVntdCoolBkLvlLRVirtCtlReq 0 "No Request" 1 "Off" 2 "Low" 3 "Medium" 4 "High" ;
VAL_ 1124 StHtdCushLvlLRVirtCtlReq 0 "No Request" 1 "Off" 2 "Low" 3 "Medium" 4 "High" ;
VAL_ 1124 StHtdBkLvlLRVirtCtlReq 0 "No Request" 1 "Off" 2 "Low" 3 "Medium" 4 "High" ;
VAL_ 1124 StHtdCushLvlRFVirtCtlReq 0 "No Request" 1 "Off" 2 "Low" 3 "Medium" 4 "High" ;
VAL_ 1124 StHtdBkLvlRFVirtCtlReq 0 "No Request" 1 "Off" 2 "Low" 3 "Medium" 4 "High" ;
VAL_ 1124 StVntdCoolCushLvlLRVirtCtlReq 0 "No Request" 1 "Off" 2 "Low" 3 "Medium" 4 "High" ;
VAL_ 1124 StVntdCoolCushLvlRFVirtCtlReq 0 "No Request" 1 "Off" 2 "Low" 3 "Medium" 4 "High" ;
VAL_ 1124 StVntdCoolBkLvlRFVirtCtlReq 0 "No Request" 1 "Off" 2 "Low" 3 "Medium" 4 "High" ;
VAL_ 1124 StVntdCoolBkLvlRRVirtCtlReq 0 "No Request" 1 "Off" 2 "Low" 3 "Medium" 4 "High" ;
VAL_ 1124 StHtdCushLvlRRVirtCtlReq 0 "No Request" 1 "Off" 2 "Low" 3 "Medium" 4 "High" ;
VAL_ 1124 StHtdBkLvlRRVirtCtlReq 0 "No Request" 1 "Off" 2 "Low" 3 "Medium" 4 "High" ;
VAL_ 1124 StMemLRVirtCtlReq 0 "No Request" 1 "Store Mem 1" 2 "Store Mem 2" 3 "Store Mem 3" 4 "Store Mem 4" 5 "Store Mem 5" 6 "Store Mem 6" 7 "Store Mem 7" 8 "Store Mem 8" 9 "Store Exit 1" 10 "Store Exit 2" 11 "Store Exit 3" 12 "Store Exit 4" 13 "Store Exit 5" 14 "Store Exit 6" 15 "Store Exit 7" 16 "Store Exit 8" 17 "Recall Mem 1" 18 "Recall Mem 2" 19 "Recall Mem 3" 20 "Recall Mem 4" 21 "Recall Mem 5" 22 "Recall Mem 6" 23 "Recall Mem 7" 24 "Recall Mem 8" 25 "Recall Exit 1" 26 "Recall Exit 2" 27 "Recall Exit 3" 28 "Recall Exit 4" 29 "Recall Exit 5" 30 "Recall Exit 6" 31 "Recall Exit 7" 32 "Recall Exit 8" 33 "Stop All Movement" ;
VAL_ 1124 StVntdCoolCushLvlRRVirtCtlReq 0 "No Request" 1 "Off" 2 "Low" 3 "Medium" 4 "High" ;
VAL_ 1124 StMemRFVirtCtlReq 0 "No Request" 1 "Store Mem 1" 2 "Store Mem 2" 3 "Store Mem 3" 4 "Store Mem 4" 5 "Store Mem 5" 6 "Store Mem 6" 7 "Store Mem 7" 8 "Store Mem 8" 9 "Store Exit 1" 10 "Store Exit 2" 11 "Store Exit 3" 12 "Store Exit 4" 13 "Store Exit 5" 14 "Store Exit 6" 15 "Store Exit 7" 16 "Store Exit 8" 17 "Recall Mem 1" 18 "Recall Mem 2" 19 "Recall Mem 3" 20 "Recall Mem 4" 21 "Recall Mem 5" 22 "Recall Mem 6" 23 "Recall Mem 7" 24 "Recall Mem 8" 25 "Recall Exit 1" 26 "Recall Exit 2" 27 "Recall Exit 3" 28 "Recall Exit 4" 29 "Recall Exit 5" 30 "Recall Exit 6" 31 "Recall Exit 7" 32 "Recall Exit 8" 33 "Stop All Movement" ;
VAL_ 1124 RrDrOpnCmfRclCstChgSetReq 0 "No Action" 1 "Off" 2 "On" ;
VAL_ 1124 StMemRRVirtCtlReq 0 "No Request" 1 "Store Mem 1" 2 "Store Mem 2" 3 "Store Mem 3" 4 "Store Mem 4" 5 "Store Mem 5" 6 "Store Mem 6" 7 "Store Mem 7" 8 "Store Mem 8" 9 "Store Exit 1" 10 "Store Exit 2" 11 "Store Exit 3" 12 "Store Exit 4" 13 "Store Exit 5" 14 "Store Exit 6" 15 "Store Exit 7" 16 "Store Exit 8" 17 "Recall Mem 1" 18 "Recall Mem 2" 19 "Recall Mem 3" 20 "Recall Mem 4" 21 "Recall Mem 5" 22 "Recall Mem 6" 23 "Recall Mem 7" 24 "Recall Mem 8" 25 "Recall Exit 1" 26 "Recall Exit 2" 27 "Recall Exit 3" 28 "Recall Exit 4" 29 "Recall Exit 5" 30 "Recall Exit 6" 31 "Recall Exit 7" 32 "Recall Exit 8" 33 "Stop All Movement" ;
VAL_ 1124 VirtFrtPsStInfoDspFRstReq 0 "No Action" 1 "Force Reset" ;
VAL_ 1124 PhnWrlsChrg1DsbldCstChgSetReq 0 "No Action" 1 "Off" 2 "On" ;
VAL_ 1124 DlvryModeVwgCstChgSetReq 0 "No Action" 1 "Off" 2 "On" ;
VAL_ 1943 VehNeutAbuseIndReq 0 "No Indication" 1 "Speed Too High" 2 "Distance Too Far" ;
VAL_ 1943 ClmCtlCbnFrtLtTempSet_Inv 0 "FALSE" 1 "TRUE" ;
VAL_ 1123 VirtFrtPsStInfoDspPwrBtnCtlAval 0 "Not Available" 1 "Available" ;
VAL_ 1123 FrtPsStInfoDspPwrBtnCurrSlnVal 0 "Unknown" 1 "On" 2 "Off" ;
VAL_ 1944 VirtRrStInfoDsp2PwrBtnCtlAval 0 "Not Available" 1 "Available" ;
VAL_ 1944 VirtRrStInfoDsp1PwrBtnCtlAval 0 "Not Available" 1 "Available" ;
VAL_ 1944 RrStInfoDsp2PwrBtnCurrSlnVal 0 "Unknown" 1 "On" 2 "Off" ;
VAL_ 1944 RrStInfoDsp1PwrBtnCurrSlnVal 0 "Unknown" 1 "On" 2 "Off" ;
VAL_ 1122 PhnWrlsChrg4DsbldCstChgSetReq 0 "No Action" 1 "Off" 2 "On" ;
VAL_ 1122 PhnWrlsChrg3DsbldCstChgSetReq 0 "No Action" 1 "Off" 2 "On" ;
VAL_ 1122 PhnWrlsChrg2DsbldCstChgSetReq 0 "No Action" 1 "Off" 2 "On" ;
VAL_ 1122 VirtRrStInfoDsp2PwrBtnReq 0 "No Action" 1 "Press And Release" 2 "Press And Hold" ;
VAL_ 1122 VirtRrStInfoDsp1PwrBtnReq 0 "No Action" 1 "Press And Release" 2 "Press And Hold" ;
VAL_ 1122 VirtFrtPsStInfoDspPwrBtnReq 0 "No Action" 1 "Press And Release" 2 "Press And Hold" ;
VAL_ 1122 LnKpAsstSeltdVirtCtlReq 0 "No Action" 1 "On" 2 "Off" ;
VAL_ 1122 VirtRrStInfoDsp2FRstReq 0 "No Action" 1 "Force Reset" ;
VAL_ 1122 VirtRrStInfoDsp1FRstReq 0 "No Action" 1 "Force Reset" ;
VAL_ 1122 QdZnAudVolSyncCtlOn 0 "FALSE" 1 "TRUE" ;
VAL_ 1945 PhnWrlsChrg1DsbldCstSetAval 0 "FALSE" 1 "TRUE" ;
VAL_ 1945 PhnWrlsChrg1DsbldCstAvlFlg7 0 "FALSE" 1 "TRUE" ;
VAL_ 1945 PhnWrlsChrg1DsbldCstAvlFlg6 0 "FALSE" 1 "TRUE" ;
VAL_ 1945 PhnWrlsChrg1DsbldCstAvlFlg5 0 "FALSE" 1 "TRUE" ;
VAL_ 1945 PhnWrlsChrg1DsbldCstAvlFlg4 0 "FALSE" 1 "TRUE" ;
VAL_ 1121 PhnWrlsChrg2DsbldCstAvlFlg2 0 "FALSE" 1 "TRUE" ;
VAL_ 1121 PhnWrlsChrg2DsbldCstAvlFlg1 0 "FALSE" 1 "TRUE" ;
VAL_ 1121 WrlsChrgSys2ChrgSts 0 "WCS Not Present" 1 "Charging Inactive" 2 "Charging Active" 3 "Charging Complete" 4 "Foreign Object Detected" 5 "WCS Overtemp Shutdown" 6 "Phone Overtemp" 7 "Establishing Communications" ;
VAL_ 1121 PhnWrlsChrg2DsbldCstCurrSetVal 0 "Setting Unknown" 1 "Off" 2 "On" ;
VAL_ 1121 PhnWrlsChrg2DsbldCstSetAval 0 "FALSE" 1 "TRUE" ;
VAL_ 1121 PhnWrlsChrg2DsbldCstAvlFlg7 0 "FALSE" 1 "TRUE" ;
VAL_ 1121 PhnWrlsChrg2DsbldCstAvlFlg6 0 "FALSE" 1 "TRUE" ;
VAL_ 1121 PhnWrlsChrg2DsbldCstAvlFlg5 0 "FALSE" 1 "TRUE" ;
VAL_ 1121 PhnWrlsChrg2DsbldCstAvlFlg4 0 "FALSE" 1 "TRUE" ;
VAL_ 1121 PhnWrlsChrg2DsbldCstAvlFlg3 0 "FALSE" 1 "TRUE" ;
VAL_ 1946 PhnWrlsChrg3DsbldCstAvlFlg2 0 "FALSE" 1 "TRUE" ;
VAL_ 1946 PhnWrlsChrg3DsbldCstAvlFlg1 0 "FALSE" 1 "TRUE" ;
VAL_ 1946 WrlsChrgSys3ChrgSts 0 "WCS Not Present" 1 "Charging Inactive" 2 "Charging Active" 3 "Charging Complete" 4 "Foreign Object Detected" 5 "WCS Overtemp Shutdown" 6 "Phone Overtemp" 7 "Establishing Communications" ;
VAL_ 1946 PhnWrlsChrg3DsbldCstCurrSetVal 0 "Setting Unknown" 1 "Off" 2 "On" ;
VAL_ 1946 PhnWrlsChrg3DsbldCstSetAval 0 "FALSE" 1 "TRUE" ;
VAL_ 1946 PhnWrlsChrg3DsbldCstAvlFlg7 0 "FALSE" 1 "TRUE" ;
VAL_ 1946 PhnWrlsChrg3DsbldCstAvlFlg6 0 "FALSE" 1 "TRUE" ;
VAL_ 1946 PhnWrlsChrg3DsbldCstAvlFlg5 0 "FALSE" 1 "TRUE" ;
VAL_ 1946 PhnWrlsChrg3DsbldCstAvlFlg4 0 "FALSE" 1 "TRUE" ;
VAL_ 1946 PhnWrlsChrg3DsbldCstAvlFlg3 0 "FALSE" 1 "TRUE" ;
VAL_ 1120 PhnWrlsChrg4DsbldCstAvlFlg2 0 "FALSE" 1 "TRUE" ;
VAL_ 1120 PhnWrlsChrg4DsbldCstAvlFlg1 0 "FALSE" 1 "TRUE" ;
VAL_ 1120 WrlsChrgSys4ChrgSts 0 "WCS Not Present" 1 "Charging Inactive" 2 "Charging Active" 3 "Charging Complete" 4 "Foreign Object Detected" 5 "WCS Overtemp Shutdown" 6 "Phone Overtemp" 7 "Establishing Communications" ;
VAL_ 1120 PhnWrlsChrg4DsbldCstCurrSetVal 0 "Setting Unknown" 1 "Off" 2 "On" ;
VAL_ 1120 PhnWrlsChrg4DsbldCstSetAval 0 "FALSE" 1 "TRUE" ;
VAL_ 1120 PhnWrlsChrg4DsbldCstAvlFlg7 0 "FALSE" 1 "TRUE" ;
VAL_ 1120 PhnWrlsChrg4DsbldCstAvlFlg6 0 "FALSE" 1 "TRUE" ;
VAL_ 1120 PhnWrlsChrg4DsbldCstAvlFlg5 0 "FALSE" 1 "TRUE" ;
VAL_ 1120 PhnWrlsChrg4DsbldCstAvlFlg4 0 "FALSE" 1 "TRUE" ;
VAL_ 1120 PhnWrlsChrg4DsbldCstAvlFlg3 0 "FALSE" 1 "TRUE" ;
VAL_ 61 PrplSysMtrBTrqAchvd_Inv 0 "FALSE" 1 "TRUE" ;
VAL_ 61 PrplSysMtrCTrqAchvd_Inv 0 "FALSE" 1 "TRUE" ;
VAL_ 1954 DrvrSeltdSpdLmtrVirtCtlAllwd 0 "Not Allowed" 1 "Allowed" ;
VAL_ 1954 AutoVehHldVirtCtlAval 0 "Not Available" 1 "Available" ;
VAL_ 1954 AutoVehHldVirtCurrSeltnVal 0 "Unknown" 1 "Disabled" 2 "Enabled Once Key Cycle" 3 "Enabled Always" ;
VAL_ 1954 TrfcJamAsstVirtCtlCurrSeltnVal 0 "Unknown" 1 "Off" 2 "On" ;
VAL_ 1954 DrvrSeltdSpdLmtrVirtCtlAval 0 "Not Available" 1 "Available" ;
VAL_ 1954 FuelDrOpnIndOn 0 "FALSE" 1 "TRUE" ;
VAL_ 1954 VehRefulngStat 0 "Inactive" 1 "Wait to Refuel" 2 "Ready to Refuel" ;
VAL_ 1954 DrvrSeltdSpdLmtrVirtCtlSeltnAvl 0 "Not Available" 1 "Manual Only" 2 "Manual and Auto" ;
VAL_ 1954 TrfcJamAsstVirtCtlAval 0 "Not Available" 1 "Available" ;
VAL_ 1954 ElecTransPrkSwSeltd 0 "FALSE" 1 "TRUE" ;
VAL_ 1954 DrPstnLF_Inv 0 "FALSE" 1 "TRUE" ;
VAL_ 1954 DrPstnLF_DuD 0 "FALSE" 1 "TRUE" ;
VAL_ 1954 HybChrgModeStat 0 "Charge Depleting" 1 "Charge Sustaining" ;
VAL_ 1954 DrPstnRF_Inv 0 "FALSE" 1 "TRUE" ;
VAL_ 1954 DrPstnRF_DuD 0 "FALSE" 1 "TRUE" ;
VAL_ 1955 WhlCntrCapLgtCommSts 0 "No Center Cap Lights Present" 1 "Not Connected" 2 "Connecton Pending" 3 "Connected" 4 "Connection Fault" ;
VAL_ 1955 VirtKeyPinToStrtMaxAtmp 0 "No Value" 1 "1 Attempt" 2 "2 Attempts" 3 "3 Attempts" 4 "4 Attempts" 5 "5 Attempts" 6 "6 Attempts" 7 "7 Attempts" 8 "8 Attempts" 9 "9 Attempts" 10 "10 Attempts" 11 "11 Attempts" 12 "12 Attempts" 13 "13 Attempts" 14 "14 Attempts" 15 "15 Attempts" ;
VAL_ 737 SrrndVwCamsOnReqd 0 "FALSE" 1 "TRUE" ;
VAL_ 737 RmtVidImgXferActv 0 "FALSE" 1 "TRUE" ;
VAL_ 1917 VehConPrvdrLrnSts 0 "Learn Unknown" 1 "Learn Complete" 2 "Learn Incomplete" ;
VAL_ 669 VehOnStrThftDtcted 0 "FALSE" 1 "TRUE" ;
VAL_ 669 VehOnStrCrshDtcted 0 "FALSE" 1 "TRUE" ;
VAL_ 669 RmtVidImgXferReqd 0 "FALSE" 1 "TRUE" ;
VAL_ 1973 ChrgCommBridgeDrvrNtfn 0 "None" 1 "Temporary Error" 2 "OTA Restriction" 3 "Charging Station Fault" 4 "Internal Service Fault" ;
VAL_ 1973 ChrgCommSLACSts 0 "Idle" 1 "Parameter Discovery Request" 2 "Parameter Discovery Response" 3 "Sounding Indication" 4 "Start Attenuation Characterization Indication" 5 "Attenuation Characterization Indication" 6 "Attenuation Characterization Indication Response" 7 "SLAC Match Request" 8 "SLAC Match Confirmation" 9 "Set Key Request" 10 "Set Key Confirmation" 11 "SLAC Complete" 12 "SLAC Failed" ;
VAL_ 1959 TnDrvrVolLimCstCurrSetVal 0 "Unknown" 1 "Off" 2 "On" ;
VAL_ 1959 DMPDAutoClsTmRFCstChgSetReq 0 "No Action" 1 "Standard" 2 "Extended" 3 "Keep Open" ;
VAL_ 1959 DMPDAutoClsTmLFCstChgSetReq 0 "No Action" 1 "Standard" 2 "Extended" 3 "Keep Open" ;
VAL_ 1959 DMPDClsOutofPrkRFCstChgSetReq 0 "No Action" 1 "Off" 2 "On" ;
VAL_ 1959 DMPDClsOutofPrkLFCstChgSetReq 0 "No Action" 1 "Off" 2 "On" ;
VAL_ 1959 SCAPDOpnMaxTrvlCstChgSetReq 0 "No Action" 1 "Slight" 2 "Standard" 3 "Maximum" ;
VAL_ 1959 SCAPDBrktoClsRFCstChgSetReq 0 "No Action" 1 "Off" 2 "On" ;
VAL_ 1959 SCAPDBrktoClsLFCstChgSetReq 0 "No Action" 1 "Off" 2 "On" ;
VAL_ 1959 ChrgCommGtwayIntrnlFltSts 0 "PLC_GWHealth_Unknown" 1 "PLC_GWHealth_NoFault" 2 "PLC_GWHealth_Faulted" ;
VAL_ 1959 ChrgCommGtwayOprtlSts 0 "PLC_GW_Unknown" 1 "PLC_GW_InActive" 2 "PLC_GW_Active" 3 "PLC_GW_Disabled" ;
VAL_ 1962 DrPstnLR_Inv 0 "FALSE" 1 "TRUE" ;
VAL_ 1962 DrPstnLR_DuD 0 "FALSE" 1 "TRUE" ;
VAL_ 1962 DMBlkhdDrOpnVehOffCstCurrSetVal 0 "Setting Unknown" 1 "Off" 2 "On" ;
VAL_ 1962 DrPstnRR_Inv 0 "FALSE" 1 "TRUE" ;
VAL_ 1962 DrPstnRR_DuD 0 "FALSE" 1 "TRUE" ;
VAL_ 1962 CstdwnModeEnbld 0 "FALSE" 1 "TRUE" ;
VAL_ 1962 PedMpLocBsdDlvryModeLtdPwrIndOn 0 "FALSE" 1 "TRUE" ;
VAL_ 1962 DMPDDOBlkhdDrOpnRFCstCurrSetVal 0 "Setting Unknown" 1 "Off" 2 "On" ;
VAL_ 1962 DMPDDOBlkhdDrOpnLFCstCurrSetVal 0 "Setting Unknown" 1 "Off" 2 "On" ;
VAL_ 1963 SCAOOAByKeyFobLFCstCurrSetVal 0 "Setting Unknown" 1 "Off" 2 "On" ;
VAL_ 1963 SCAPDBrktoClsLFCstCurrSetVal 0 "Setting Unknown" 1 "Off" 2 "On" ;
VAL_ 1963 SCAOOAByVirtKeyLFCstCurrSetVal 0 "Setting Unknown" 1 "Off" 2 "On" ;
VAL_ 1963 SCAPDOpnMaxTrvlCstCurrSetVal 0 "Setting Unknown" 1 "Slight" 2 "Standard" 3 "Maximum" ;
VAL_ 1963 CoDrvrDrOpn_DuD 0 "FALSE" 1 "TRUE" ;
VAL_ 1963 CoDrvrDrOpn 0 "FALSE" 1 "TRUE" ;
VAL_ 1963 DrRROpn_Inv 0 "FALSE" 1 "TRUE" ;
VAL_ 1963 DrRROpn_DuD 0 "FALSE" 1 "TRUE" ;
VAL_ 1963 DrRROpn 0 "FALSE" 1 "TRUE" ;
VAL_ 1963 DrLROpn_Inv 0 "FALSE" 1 "TRUE" ;
VAL_ 1963 DrLROpn_DuD 0 "FALSE" 1 "TRUE" ;
VAL_ 1963 DrLROpn 0 "FALSE" 1 "TRUE" ;
VAL_ 1963 SCAPwrDrMtnRRVirtCtlRrAllwd 0 "Not Allowed" 1 "Allowed" ;
VAL_ 1963 SCAPwrDrMtnRRVirtCtlFrtAllwd 0 "Not Allowed" 1 "Allowed" ;
VAL_ 1963 SCAPwrDrMtnLRVirtCtlRrAllwd 0 "Not Allowed" 1 "Allowed" ;
VAL_ 1963 SCAPwrDrMtnLRVirtCtlFrtAllwd 0 "Not Allowed" 1 "Allowed" ;
VAL_ 1963 SCAPwrDrMtnLFVirtCtlAllwd 0 "Not Allowed" 1 "Allowed" ;
VAL_ 1963 CoDrvrDrOpn_Inv 0 "FALSE" 1 "TRUE" ;
VAL_ 1963 SdDrRRInMtnActv 0 "FALSE" 1 "TRUE" ;
VAL_ 1963 SdDrRFInMtnActv 0 "FALSE" 1 "TRUE" ;
VAL_ 1963 SdDrLRInMtnActv 0 "FALSE" 1 "TRUE" ;
VAL_ 1963 SdDrLFInMtnActv 0 "FALSE" 1 "TRUE" ;
VAL_ 1963 HtdStrgWhlInd 0 "Off" 1 "Low" 2 "Med" 3 "High" ;
VAL_ 1963 FltDrvrActvRmtCstCurrSetVal 0 "Setting Unknown" 1 "Off" 2 "On" ;
VAL_ 1963 LSCMBABP_ReqActvAuth 0 "FALSE" 1 "TRUE" ;
VAL_ 1963 FIMRIMABP_BrkgReqAuth 0 "FALSE" 1 "TRUE" ;
VAL_ 1963 ChsDynoModeEnbld 0 "FALSE" 1 "TRUE" ;
VAL_ 1963 HtdStrgWhlLvlIndOn 0 "FALSE" 1 "TRUE" ;
VAL_ 1100 HVACICRHtdArmrstLvlFrtRt 0 "Off" 1 "1" 2 "2" 3 "3" ;
VAL_ 1100 HVACICRHtdArmrstLvlFrtLt 0 "Off" 1 "1" 2 "2" 3 "3" ;
VAL_ 1100 HVACICRHtdArmrstLvlFrtRtActv 0 "FALSE" 1 "TRUE" ;
VAL_ 1100 HVACICRHtdArmrstLvlFrtLtActv 0 "FALSE" 1 "TRUE" ;
VAL_ 1100 HVACICRHtdArmrstLvlRrRt 0 "Off" 1 "1" 2 "2" 3 "3" ;
VAL_ 1100 HVACICRHtdArmrstLvlRrLt 0 "Off" 1 "1" 2 "2" 3 "3" ;
VAL_ 1100 HVACInfoCtlRqAirDstThrdRw 0 "No Action" 1 "Auto" 2 "Floor" 3 "Floor And Vent" 4 "Vent" 5 "Vent And Roof" 6 "Roof" 7 "Roof And Floor" 8 "Floor And Vent And Roof" ;
VAL_ 1100 HVACInfoCtlRqAirDstChgNxtThrdRw 0 "FALSE" 1 "TRUE" ;
VAL_ 1100 HVACICRHtdArmrstLvlRrRtActv 0 "FALSE" 1 "TRUE" ;
VAL_ 1100 HVACICRHtdArmrstLvlRrLtActv 0 "FALSE" 1 "TRUE" ;
VAL_ 1100 HVACInfoCtlRqSyncThrdRwChg 0 "FALSE" 1 "TRUE" ;
VAL_ 1100 HVACInfoCtlRqBlwLvlThrdRwActv 0 "FALSE" 1 "TRUE" ;
VAL_ 1100 HVACInfoCtlRqThrdRwPwrSetChg 0 "FALSE" 1 "TRUE" ;
VAL_ 1100 HVACInfoCtlRqThrdRwLckSetChg 0 "FALSE" 1 "TRUE" ;
VAL_ 1100 HVACInfoCtlRqThrdRwAutoSetChg 0 "FALSE" 1 "TRUE" ;
VAL_ 1100 HVACInfoCtlRqTempLvlThrdRwActv 0 "FALSE" 1 "TRUE" ;
VAL_ 1967 ChrgCommBridgeOprtlSts 0 "PLC_Bridge_Unknown" 1 "PLC_Bridge_InActive" 2 "PLC_Bridge_Active" 3 "PLC_Bridge_Disabled" ;
VAL_ 1967 ChrgCommBridgeIntrnlFltSts 0 "PLC_BridgeHealth_Unknown" 1 "PLC_BridgeHealth_NoFault" 2 "PLC_BridgeHealth_Faulted" ;
VAL_ 1420 VidTrlrTowPhs2ChmEvntStat 0 "NO_ACTION" 1 "ACTIVE" 2 "CANCEL_CHIME" ;
VAL_ 1420 RrPedtrnClsnMtgnNtfyChmEvntStat 0 "NO_ACTION" 1 "ACTIVE" 2 "CANCEL_CHIME" ;
VAL_ 1420 TrlrVidVwPhs1ChmEvntStat 0 "No Action" 1 "Active" 2 "Cancel Chime" ;
VAL_ 1113 DMHrnOutPrkCstChgSetReq 0 "No Action" 1 "Off" 2 "On" ;
VAL_ 1113 DMCabLgtPrkCstChgSetReq 0 "No Action" 1 "Off" 2 "On" ;
VAL_ 1113 InfoFrtSnshdPstnReq 0 "No Request" 1 "0%" 2 "10%" 3 "20%" 4 "30%" 5 "40%" 6 "50%" 7 "60%" 8 "70%" 9 "80%" 10 "90%" 11 "100%" 12 "Comfort Open" 13 "Stop" ;
VAL_ 1113 RmtVidVwgLgtFlshReqd 0 "FALSE" 1 "TRUE" ;
VAL_ 1113 RmtVidVwgIntrLgtReqd 0 "FALSE" 1 "TRUE" ;
VAL_ 1113 RmtVidVwgExtLgtReqd 0 "FALSE" 1 "TRUE" ;
VAL_ 1113 HtdArmrstSyncCstChgSetReq 0 "No Action" 1 "Off" 2 "On" ;
VAL_ 1113 AutoAirOtltAmgCstChgSetReq 0 "No Action" 1 "Off" 2 "On" ;
VAL_ 1113 ArflBsdOnOccpRrPsCstChgSetReq 0 "No Action" 1 "Off" 2 "On" ;
VAL_ 1113 ArflBsdOnOccpFrtPsCstChgSetReq 0 "No Action" 1 "Off" 2 "On" ;
VAL_ 1113 TrlrTireLkDtnUserReq 0 "No Action" 1 "Enabled" 2 "Disabled" 3 "Reset" ;
VAL_ 1113 CbnAirClnFltrtnCstChgSetReq 0 "No Action" 1 "Off" 2 "On" ;
VAL_ 1113 AutoNckScrfCstChgSetReq 0 "No Action" 1 "Off" 2 "On" 3 "Sync to Heated Seats" ;
VAL_ 1113 ClmCtlRrBlw2CtlCktOORHiFlrSts 0 "Indeterminate" 1 "Pass Criteria Met" 2 "Fail Criteria Met" ;
VAL_ 1113 ClmCtlRrBlw2CtlCktFlrSts 0 "Indeterminate" 1 "Pass Criteria Met" 2 "Fail Criteria Met" ;
VAL_ 1113 DuctAirTempRrVntRwVltgDatRxd 0 "FALSE" 1 "TRUE" ;
VAL_ 1113 DuctAirTempRrRtVntRwVltgDatRxd 0 "FALSE" 1 "TRUE" ;
VAL_ 1113 DuctAirTempRrRtFloorRwVltDatRxd 0 "FALSE" 1 "TRUE" ;
VAL_ 1113 DuctAirTempRrFloorRwVltgDatRxd 0 "FALSE" 1 "TRUE" ;
VAL_ 1113 ClmCtlRrBlwCtlCktOORHiFlrSts 0 "Indeterminate" 1 "Pass Criteria Met" 2 "Fail Criteria Met" ;
VAL_ 1113 ClmCtlRrBlwCtlCktFlrSts 0 "Indeterminate" 1 "Pass Criteria Met" 2 "Fail Criteria Met" ;
VAL_ 1113 ClmCtlRrBlw2CtlCktStsDatRxd 0 "FALSE" 1 "TRUE" ;
VAL_ 1113 ClmCtlRrBlw2CtlCktOORLoFlrSts 0 "Indeterminate" 1 "Pass Criteria Met" 2 "Fail Criteria Met" ;
VAL_ 1113 InfoThmSeltnExpdCurrSetVal 0 "Unknown" 1 "None" 2 "Theme 1" 3 "Theme 2" 4 "Theme 3" 5 "Theme 4" 6 "Theme 5" 7 "Theme 6" 8 "Theme 7" 9 "Theme 8" 10 "Theme 9" 11 "Theme 10" 12 "Theme 11" 13 "Theme 12" 14 "Theme 13" 15 "Theme 14" 16 "Theme 15" 17 "Theme 16" 18 "Theme 17" 19 "Theme 18" 20 "Theme 19" 21 "Theme 20" 22 "Theme 21" 23 "Theme 22" 24 "Theme 23" 25 "Theme 24" 26 "Theme 25" 27 "Theme 26" 28 "Theme 27" 29 "Theme 28" 30 "Theme 29" 31 "Theme 30" 32 "Theme 31" 33 "Theme 32" 34 "Theme 33" 35 "Theme 34" 36 "Theme 35" 37 "Theme 36" 38 "Theme 37" 39 "Theme 38" 40 "Theme 39" 41 "Theme 40" 42 "Theme 41" 43 "Theme 42" 44 "Theme 43" 45 "Theme 44" 46 "Theme 45" 47 "Theme 46" 48 "Theme 47" 49 "Theme 48" 50 "Theme 49" 51 "Theme 50" 52 "Theme 51" 53 "Theme 52" 54 "Theme 53" 55 "Theme 54" 56 "Theme 55" 57 "Theme 56" 58 "Theme 57" 59 "Theme 58" 60 "Theme 59" 61 "Theme 60" 62 "Theme 61" 63 "Theme 62" 64 "Theme 63" 65 "Theme 64" 66 "Theme 65" 67 "Theme 66" 68 "Theme 67" 69 "Theme 68" 70 "Theme 69" 71 "Theme 70" 72 "Theme 71" 73 "Theme 72" 74 "Theme 73" 75 "Theme 74" 76 "Theme 75" 77 "Theme 76" 78 "Theme 77" 79 "Theme 78" 80 "Theme 79" 81 "Theme 80" 82 "Theme 81" 83 "Theme 82" 84 "Theme 83" 85 "Theme 84" 86 "Theme 85" 87 "Theme 86" 88 "Theme 87" 89 "Theme 88" 90 "Theme 89" 91 "Theme 90" 92 "Theme 91" 93 "Theme 92" 94 "Theme 93" 95 "Theme 94" 96 "Theme 95" 97 "Theme 96" 98 "Theme 97" 99 "Theme 98" 100 "Theme 99" 101 "Theme 100" 102 "Theme 101" 103 "Theme 102" 104 "Theme 103" 105 "Theme 104" 106 "Theme 105" 107 "Theme 106" 108 "Theme 107" 109 "Theme 108" 110 "Theme 109" 111 "Theme 110" 112 "Theme 111" 113 "Theme 112" 114 "Theme 113" 115 "Theme 114" 116 "Theme 115" 117 "Theme 116" 118 "Theme 117" 119 "Theme 118" 120 "Theme 119" 121 "Theme 120" 122 "Theme 121" 123 "Theme 122" 124 "Theme 123" 125 "Theme 124" 126 "Theme 125" 127 "Theme 126" 128 "Theme 127" 129 "Theme 128" 130 "Theme 129" 131 "Theme 130" 132 "Theme 131" 133 "Theme 132" 134 "Theme 133" 135 "Theme 134" 136 "Theme 135" 137 "Theme 136" 138 "Theme 137" 139 "Theme 138" 140 "Theme 139" 141 "Theme 140" 142 "Theme 141" 143 "Theme 142" 144 "Theme 143" 145 "Theme 144" 146 "Theme 145" 147 "Theme 146" 148 "Theme 147" 149 "Theme 148" 150 "Theme 149" 151 "Theme 150" 152 "Theme 151" 153 "Theme 152" 154 "Theme 153" 155 "Theme 154" 156 "Theme 155" 157 "Theme 156" 158 "Theme 157" 159 "Theme 158" 160 "Theme 159" 161 "Theme 160" 162 "Theme 161" 163 "Theme 162" 164 "Theme 163" 165 "Theme 164" 166 "Theme 165" 167 "Theme 166" 168 "Theme 167" 169 "Theme 168" 170 "Theme 169" 171 "Theme 170" 172 "Theme 171" 173 "Theme 172" 174 "Theme 173" 175 "Theme 174" 176 "Theme 175" 177 "Theme 176" 178 "Theme 177" 179 "Theme 178" 180 "Theme 179" 181 "Theme 180" 182 "Theme 181" 183 "Theme 182" 184 "Theme 183" 185 "Theme 184" 186 "Theme 185" 187 "Theme 186" 188 "Theme 187" 189 "Theme 188" 190 "Theme 189" 191 "Theme 190" 192 "Theme 191" 193 "Theme 192" 194 "Theme 193" 195 "Theme 194" 196 "Theme 195" 197 "Theme 196" 198 "Theme 197" 199 "Theme 198" 200 "Theme 199" 201 "Theme 200" 202 "Theme 201" 203 "Theme 202" 204 "Theme 203" 205 "Theme 204" 206 "Theme 205" 207 "Theme 206" 208 "Theme 207" 209 "Theme 208" 210 "Theme 209" 211 "Theme 210" 212 "Theme 211" 213 "Theme 212" 214 "Theme 213" 215 "Theme 214" 216 "Theme 215" 217 "Theme 216" 218 "Theme 217" 219 "Theme 218" 220 "Theme 219" 221 "Theme 220" 222 "Theme 221" 223 "Theme 222" 224 "Theme 223" 225 "Theme 224" 226 "Theme 225" 227 "Theme 226" 228 "Theme 227" 229 "Theme 228" 230 "Theme 229" 231 "Theme 230" 232 "Theme 231" 233 "Theme 232" 234 "Theme 233" 235 "Theme 234" 236 "Theme 235" 237 "Theme 236" 238 "Theme 237" 239 "Theme 238" 240 "Theme 239" 241 "Theme 240" 242 "Theme 241" 243 "Theme 242" 244 "Theme 243" 245 "Theme 244" 246 "Theme 245" 247 "Theme 246" 248 "Theme 247" 249 "Theme 248" 250 "Theme 249" 251 "Theme 250" 252 "Theme 251" 253 "Theme 252" 254 "Theme 253" 255 "Theme 254" ;
VAL_ 1113 ClmCtlRrBlwCtlCktStsDatRxd 0 "FALSE" 1 "TRUE" ;
VAL_ 1113 ClmCtlRrBlwCtlCktOORLoFlrSts 0 "Indeterminate" 1 "Pass Criteria Met" 2 "Fail Criteria Met" ;
VAL_ 1113 OccptLtBehindRmndrCstChgSetReq 0 "No Action" 1 "Off" 2 "On" ;
